VERSION "dbc-export 1 2026.26.6.5"

NS_ :

BS_:

BU_: ADSP APB APP APS APSB BB BMS CC CMP CMPD CP DAS DI DIF DIR DPB EPAS3P EPAS3S EPASTP EPASTS EPBL EPBR ESP EVSE FC GTW HCML HCMR HVP IBST ICR IDB LS OCS1P PARK PCS PCS2 PM PMF PMR PNCD PTC RADC RCM RCM2 RCM3 RCU SCCM SCM SCS SDCR TAS TCU TCU2 TPMS TRCM UI UIS UMC USM V2G VC VCBATT VCBATT0 VCBATT1 VCBATT2 VCCC VCFRONT VCFRONT1 VCFRONT2 VCLEFT VCRIGHT VCSEAT2L VCSEAT2R VCSEC VEH

BO_ 1025 BMS_brickMeasurements: 8 BMS
 SG_ BMS_brickVoltageMultiplexer M : 0|8@1+ (1,0) [0|255] "" Vector__XXX
 SG_ BMS_brickVoltageCounter : 14|2@1+ (1,0) [0|3] "" Vector__XXX
 SG_ BMS_brickVoltageStatus1 m0 : 8|2@1+ (1,0) [0|3] "" Vector__XXX
 SG_ BMS_brickVoltageStatus2 m0 : 10|2@1+ (1,0) [0|3] "" Vector__XXX
 SG_ BMS_brickVoltageStatus3 m0 : 12|2@1+ (1,0) [0|3] "" Vector__XXX
 SG_ BMS_brickVoltage1 m0 : 16|16@1+ (0.0001,0) [0|5] "V" Vector__XXX
 SG_ BMS_brickVoltage2 m0 : 32|16@1+ (0.0001,0) [0|5] "V" Vector__XXX
 SG_ BMS_brickVoltage3 m0 : 48|16@1+ (0.0001,0) [0|5] "V" Vector__XXX
 SG_ BMS_brickVoltageStatus4 m1 : 8|2@1+ (1,0) [0|3] "" Vector__XXX
 SG_ BMS_brickVoltageStatus5 m1 : 10|2@1+ (1,0) [0|3] "" Vector__XXX
 SG_ BMS_brickVoltageStatus6 m1 : 12|2@1+ (1,0) [0|3] "" Vector__XXX
 SG_ BMS_brickVoltage4 m1 : 16|16@1+ (0.0001,0) [0|5] "V" Vector__XXX
 SG_ BMS_brickVoltage5 m1 : 32|16@1+ (0.0001,0) [0|5] "V" Vector__XXX
 SG_ BMS_brickVoltage6 m1 : 48|16@1+ (0.0001,0) [0|5] "V" Vector__XXX
 SG_ BMS_brickVoltageStatus7 m2 : 8|2@1+ (1,0) [0|3] "" Vector__XXX
 SG_ BMS_brickVoltageStatus8 m2 : 10|2@1+ (1,0) [0|3] "" Vector__XXX
 SG_ BMS_brickVoltageStatus9 m2 : 12|2@1+ (1,0) [0|3] "" Vector__XXX
 SG_ BMS_brickVoltage7 m2 : 16|16@1+ (0.0001,0) [0|5] "V" Vector__XXX
 SG_ BMS_brickVoltage8 m2 : 32|16@1+ (0.0001,0) [0|5] "V" Vector__XXX
 SG_ BMS_brickVoltage9 m2 : 48|16@1+ (0.0001,0) [0|5] "V" Vector__XXX
 SG_ BMS_brickVoltageStatus10 m3 : 8|2@1+ (1,0) [0|3] "" Vector__XXX
 SG_ BMS_brickVoltageStatus11 m3 : 10|2@1+ (1,0) [0|3] "" Vector__XXX
 SG_ BMS_brickVoltageStatus12 m3 : 12|2@1+ (1,0) [0|3] "" Vector__XXX
 SG_ BMS_brickVoltage10 m3 : 16|16@1+ (0.0001,0) [0|5] "V" Vector__XXX
 SG_ BMS_brickVoltage11 m3 : 32|16@1+ (0.0001,0) [0|5] "V" Vector__XXX
 SG_ BMS_brickVoltage12 m3 : 48|16@1+ (0.0001,0) [0|5] "V" Vector__XXX
 SG_ BMS_brickVoltageStatus13 m4 : 8|2@1+ (1,0) [0|3] "" Vector__XXX
 SG_ BMS_brickVoltageStatus14 m4 : 10|2@1+ (1,0) [0|3] "" Vector__XXX
 SG_ BMS_brickVoltageStatus15 m4 : 12|2@1+ (1,0) [0|3] "" Vector__XXX
 SG_ BMS_brickVoltage13 m4 : 16|16@1+ (0.0001,0) [0|5] "V" Vector__XXX
 SG_ BMS_brickVoltage14 m4 : 32|16@1+ (0.0001,0) [0|5] "V" Vector__XXX
 SG_ BMS_brickVoltage15 m4 : 48|16@1+ (0.0001,0) [0|5] "V" Vector__XXX
 SG_ BMS_brickVoltageStatus16 m5 : 8|2@1+ (1,0) [0|3] "" Vector__XXX
 SG_ BMS_brickVoltageStatus17 m5 : 10|2@1+ (1,0) [0|3] "" Vector__XXX
 SG_ BMS_brickVoltageStatus18 m5 : 12|2@1+ (1,0) [0|3] "" Vector__XXX
 SG_ BMS_brickVoltage16 m5 : 16|16@1+ (0.0001,0) [0|5] "V" Vector__XXX
 SG_ BMS_brickVoltage17 m5 : 32|16@1+ (0.0001,0) [0|5] "V" Vector__XXX
 SG_ BMS_brickVoltage18 m5 : 48|16@1+ (0.0001,0) [0|5] "V" Vector__XXX
 SG_ BMS_brickVoltageStatus19 m6 : 8|2@1+ (1,0) [0|3] "" Vector__XXX
 SG_ BMS_brickVoltageStatus20 m6 : 10|2@1+ (1,0) [0|3] "" Vector__XXX
 SG_ BMS_brickVoltageStatus21 m6 : 12|2@1+ (1,0) [0|3] "" Vector__XXX
 SG_ BMS_brickVoltage19 m6 : 16|16@1+ (0.0001,0) [0|5] "V" Vector__XXX
 SG_ BMS_brickVoltage20 m6 : 32|16@1+ (0.0001,0) [0|5] "V" Vector__XXX
 SG_ BMS_brickVoltage21 m6 : 48|16@1+ (0.0001,0) [0|5] "V" Vector__XXX
 SG_ BMS_brickVoltageStatus22 m7 : 8|2@1+ (1,0) [0|3] "" Vector__XXX
 SG_ BMS_brickVoltageStatus23 m7 : 10|2@1+ (1,0) [0|3] "" Vector__XXX
 SG_ BMS_brickVoltageStatus24 m7 : 12|2@1+ (1,0) [0|3] "" Vector__XXX
 SG_ BMS_brickVoltage22 m7 : 16|16@1+ (0.0001,0) [0|5] "V" Vector__XXX
 SG_ BMS_brickVoltage23 m7 : 32|16@1+ (0.0001,0) [0|5] "V" Vector__XXX
 SG_ BMS_brickVoltage24 m7 : 48|16@1+ (0.0001,0) [0|5] "V" Vector__XXX
 SG_ BMS_brickVoltageStatus25 m8 : 8|2@1+ (1,0) [0|3] "" Vector__XXX
 SG_ BMS_brickVoltageStatus26 m8 : 10|2@1+ (1,0) [0|3] "" Vector__XXX
 SG_ BMS_brickVoltageStatus27 m8 : 12|2@1+ (1,0) [0|3] "" Vector__XXX
 SG_ BMS_brickVoltage25 m8 : 16|16@1+ (0.0001,0) [0|5] "V" Vector__XXX
 SG_ BMS_brickVoltage26 m8 : 32|16@1+ (0.0001,0) [0|5] "V" Vector__XXX
 SG_ BMS_brickVoltage27 m8 : 48|16@1+ (0.0001,0) [0|5] "V" Vector__XXX
 SG_ BMS_brickVoltageStatus28 m9 : 8|2@1+ (1,0) [0|3] "" Vector__XXX
 SG_ BMS_brickVoltageStatus29 m9 : 10|2@1+ (1,0) [0|3] "" Vector__XXX
 SG_ BMS_brickVoltageStatus30 m9 : 12|2@1+ (1,0) [0|3] "" Vector__XXX
 SG_ BMS_brickVoltage28 m9 : 16|16@1+ (0.0001,0) [0|5] "V" Vector__XXX
 SG_ BMS_brickVoltage29 m9 : 32|16@1+ (0.0001,0) [0|5] "V" Vector__XXX
 SG_ BMS_brickVoltage30 m9 : 48|16@1+ (0.0001,0) [0|5] "V" Vector__XXX
 SG_ BMS_brickVoltageStatus31 m10 : 8|2@1+ (1,0) [0|3] "" Vector__XXX
 SG_ BMS_brickVoltageStatus32 m10 : 10|2@1+ (1,0) [0|3] "" Vector__XXX
 SG_ BMS_brickVoltageStatus33 m10 : 12|2@1+ (1,0) [0|3] "" Vector__XXX
 SG_ BMS_brickVoltage31 m10 : 16|16@1+ (0.0001,0) [0|5] "V" Vector__XXX
 SG_ BMS_brickVoltage32 m10 : 32|16@1+ (0.0001,0) [0|5] "V" Vector__XXX
 SG_ BMS_brickVoltage33 m10 : 48|16@1+ (0.0001,0) [0|5] "V" Vector__XXX
 SG_ BMS_brickVoltageStatus34 m11 : 8|2@1+ (1,0) [0|3] "" Vector__XXX
 SG_ BMS_brickVoltageStatus35 m11 : 10|2@1+ (1,0) [0|3] "" Vector__XXX
 SG_ BMS_brickVoltageStatus36 m11 : 12|2@1+ (1,0) [0|3] "" Vector__XXX
 SG_ BMS_brickVoltage34 m11 : 16|16@1+ (0.0001,0) [0|5] "V" Vector__XXX
 SG_ BMS_brickVoltage35 m11 : 32|16@1+ (0.0001,0) [0|5] "V" Vector__XXX
 SG_ BMS_brickVoltage36 m11 : 48|16@1+ (0.0001,0) [0|5] "V" Vector__XXX
 SG_ BMS_brickVoltageStatus37 m12 : 8|2@1+ (1,0) [0|3] "" Vector__XXX
 SG_ BMS_brickVoltageStatus38 m12 : 10|2@1+ (1,0) [0|3] "" Vector__XXX
 SG_ BMS_brickVoltageStatus39 m12 : 12|2@1+ (1,0) [0|3] "" Vector__XXX
 SG_ BMS_brickVoltage37 m12 : 16|16@1+ (0.0001,0) [0|5] "V" Vector__XXX
 SG_ BMS_brickVoltage38 m12 : 32|16@1+ (0.0001,0) [0|5] "V" Vector__XXX
 SG_ BMS_brickVoltage39 m12 : 48|16@1+ (0.0001,0) [0|5] "V" Vector__XXX
 SG_ BMS_brickVoltageStatus40 m13 : 8|2@1+ (1,0) [0|3] "" Vector__XXX
 SG_ BMS_brickVoltageStatus41 m13 : 10|2@1+ (1,0) [0|3] "" Vector__XXX
 SG_ BMS_brickVoltageStatus42 m13 : 12|2@1+ (1,0) [0|3] "" Vector__XXX
 SG_ BMS_brickVoltage40 m13 : 16|16@1+ (0.0001,0) [0|5] "V" Vector__XXX
 SG_ BMS_brickVoltage41 m13 : 32|16@1+ (0.0001,0) [0|5] "V" Vector__XXX
 SG_ BMS_brickVoltage42 m13 : 48|16@1+ (0.0001,0) [0|5] "V" Vector__XXX
 SG_ BMS_brickVoltageStatus43 m14 : 8|2@1+ (1,0) [0|3] "" Vector__XXX
 SG_ BMS_brickVoltageStatus44 m14 : 10|2@1+ (1,0) [0|3] "" Vector__XXX
 SG_ BMS_brickVoltageStatus45 m14 : 12|2@1+ (1,0) [0|3] "" Vector__XXX
 SG_ BMS_brickVoltage43 m14 : 16|16@1+ (0.0001,0) [0|5] "V" Vector__XXX
 SG_ BMS_brickVoltage44 m14 : 32|16@1+ (0.0001,0) [0|5] "V" Vector__XXX
 SG_ BMS_brickVoltage45 m14 : 48|16@1+ (0.0001,0) [0|5] "V" Vector__XXX
 SG_ BMS_brickVoltageStatus46 m15 : 8|2@1+ (1,0) [0|3] "" Vector__XXX
 SG_ BMS_brickVoltageStatus47 m15 : 10|2@1+ (1,0) [0|3] "" Vector__XXX
 SG_ BMS_brickVoltageStatus48 m15 : 12|2@1+ (1,0) [0|3] "" Vector__XXX
 SG_ BMS_brickVoltage46 m15 : 16|16@1+ (0.0001,0) [0|5] "V" Vector__XXX
 SG_ BMS_brickVoltage47 m15 : 32|16@1+ (0.0001,0) [0|5] "V" Vector__XXX
 SG_ BMS_brickVoltage48 m15 : 48|16@1+ (0.0001,0) [0|5] "V" Vector__XXX
 SG_ BMS_brickVoltageStatus49 m16 : 8|2@1+ (1,0) [0|3] "" Vector__XXX
 SG_ BMS_brickVoltageStatus50 m16 : 10|2@1+ (1,0) [0|3] "" Vector__XXX
 SG_ BMS_brickVoltageStatus51 m16 : 12|2@1+ (1,0) [0|3] "" Vector__XXX
 SG_ BMS_brickVoltage49 m16 : 16|16@1+ (0.0001,0) [0|5] "V" Vector__XXX
 SG_ BMS_brickVoltage50 m16 : 32|16@1+ (0.0001,0) [0|5] "V" Vector__XXX
 SG_ BMS_brickVoltage51 m16 : 48|16@1+ (0.0001,0) [0|5] "V" Vector__XXX
 SG_ BMS_brickVoltageStatus52 m17 : 8|2@1+ (1,0) [0|3] "" Vector__XXX
 SG_ BMS_brickVoltageStatus53 m17 : 10|2@1+ (1,0) [0|3] "" Vector__XXX
 SG_ BMS_brickVoltageStatus54 m17 : 12|2@1+ (1,0) [0|3] "" Vector__XXX
 SG_ BMS_brickVoltage52 m17 : 16|16@1+ (0.0001,0) [0|5] "V" Vector__XXX
 SG_ BMS_brickVoltage53 m17 : 32|16@1+ (0.0001,0) [0|5] "V" Vector__XXX
 SG_ BMS_brickVoltage54 m17 : 48|16@1+ (0.0001,0) [0|5] "V" Vector__XXX
 SG_ BMS_brickVoltageStatus55 m18 : 8|2@1+ (1,0) [0|3] "" Vector__XXX
 SG_ BMS_brickVoltageStatus56 m18 : 10|2@1+ (1,0) [0|3] "" Vector__XXX
 SG_ BMS_brickVoltageStatus57 m18 : 12|2@1+ (1,0) [0|3] "" Vector__XXX
 SG_ BMS_brickVoltage55 m18 : 16|16@1+ (0.0001,0) [0|5] "V" Vector__XXX
 SG_ BMS_brickVoltage56 m18 : 32|16@1+ (0.0001,0) [0|5] "V" Vector__XXX
 SG_ BMS_brickVoltage57 m18 : 48|16@1+ (0.0001,0) [0|5] "V" Vector__XXX
 SG_ BMS_brickVoltageStatus58 m19 : 8|2@1+ (1,0) [0|3] "" Vector__XXX
 SG_ BMS_brickVoltageStatus59 m19 : 10|2@1+ (1,0) [0|3] "" Vector__XXX
 SG_ BMS_brickVoltageStatus60 m19 : 12|2@1+ (1,0) [0|3] "" Vector__XXX
 SG_ BMS_brickVoltage58 m19 : 16|16@1+ (0.0001,0) [0|5] "V" Vector__XXX
 SG_ BMS_brickVoltage59 m19 : 32|16@1+ (0.0001,0) [0|5] "V" Vector__XXX
 SG_ BMS_brickVoltage60 m19 : 48|16@1+ (0.0001,0) [0|5] "V" Vector__XXX
 SG_ BMS_brickVoltageStatus61 m20 : 8|2@1+ (1,0) [0|3] "" Vector__XXX
 SG_ BMS_brickVoltageStatus62 m20 : 10|2@1+ (1,0) [0|3] "" Vector__XXX
 SG_ BMS_brickVoltageStatus63 m20 : 12|2@1+ (1,0) [0|3] "" Vector__XXX
 SG_ BMS_brickVoltage61 m20 : 16|16@1+ (0.0001,0) [0|5] "V" Vector__XXX
 SG_ BMS_brickVoltage62 m20 : 32|16@1+ (0.0001,0) [0|5] "V" Vector__XXX
 SG_ BMS_brickVoltage63 m20 : 48|16@1+ (0.0001,0) [0|5] "V" Vector__XXX
 SG_ BMS_brickVoltageStatus64 m21 : 8|2@1+ (1,0) [0|3] "" Vector__XXX
 SG_ BMS_brickVoltageStatus65 m21 : 10|2@1+ (1,0) [0|3] "" Vector__XXX
 SG_ BMS_brickVoltageStatus66 m21 : 12|2@1+ (1,0) [0|3] "" Vector__XXX
 SG_ BMS_brickVoltage64 m21 : 16|16@1+ (0.0001,0) [0|5] "V" Vector__XXX
 SG_ BMS_brickVoltage65 m21 : 32|16@1+ (0.0001,0) [0|5] "V" Vector__XXX
 SG_ BMS_brickVoltage66 m21 : 48|16@1+ (0.0001,0) [0|5] "V" Vector__XXX
 SG_ BMS_brickVoltageStatus67 m22 : 8|2@1+ (1,0) [0|3] "" Vector__XXX
 SG_ BMS_brickVoltageStatus68 m22 : 10|2@1+ (1,0) [0|3] "" Vector__XXX
 SG_ BMS_brickVoltageStatus69 m22 : 12|2@1+ (1,0) [0|3] "" Vector__XXX
 SG_ BMS_brickVoltage67 m22 : 16|16@1+ (0.0001,0) [0|5] "V" Vector__XXX
 SG_ BMS_brickVoltage68 m22 : 32|16@1+ (0.0001,0) [0|5] "V" Vector__XXX
 SG_ BMS_brickVoltage69 m22 : 48|16@1+ (0.0001,0) [0|5] "V" Vector__XXX
 SG_ BMS_brickVoltageStatus70 m23 : 8|2@1+ (1,0) [0|3] "" Vector__XXX
 SG_ BMS_brickVoltageStatus71 m23 : 10|2@1+ (1,0) [0|3] "" Vector__XXX
 SG_ BMS_brickVoltageStatus72 m23 : 12|2@1+ (1,0) [0|3] "" Vector__XXX
 SG_ BMS_brickVoltage70 m23 : 16|16@1+ (0.0001,0) [0|5] "V" Vector__XXX
 SG_ BMS_brickVoltage71 m23 : 32|16@1+ (0.0001,0) [0|5] "V" Vector__XXX
 SG_ BMS_brickVoltage72 m23 : 48|16@1+ (0.0001,0) [0|5] "V" Vector__XXX
 SG_ BMS_brickVoltageStatus73 m24 : 8|2@1+ (1,0) [0|3] "" Vector__XXX
 SG_ BMS_brickVoltageStatus74 m24 : 10|2@1+ (1,0) [0|3] "" Vector__XXX
 SG_ BMS_brickVoltageStatus75 m24 : 12|2@1+ (1,0) [0|3] "" Vector__XXX
 SG_ BMS_brickVoltage73 m24 : 16|16@1+ (0.0001,0) [0|5] "V" Vector__XXX
 SG_ BMS_brickVoltage74 m24 : 32|16@1+ (0.0001,0) [0|5] "V" Vector__XXX
 SG_ BMS_brickVoltage75 m24 : 48|16@1+ (0.0001,0) [0|5] "V" Vector__XXX
 SG_ BMS_brickVoltageStatus76 m25 : 8|2@1+ (1,0) [0|3] "" Vector__XXX
 SG_ BMS_brickVoltageStatus77 m25 : 10|2@1+ (1,0) [0|3] "" Vector__XXX
 SG_ BMS_brickVoltageStatus78 m25 : 12|2@1+ (1,0) [0|3] "" Vector__XXX
 SG_ BMS_brickVoltage76 m25 : 16|16@1+ (0.0001,0) [0|5] "V" Vector__XXX
 SG_ BMS_brickVoltage77 m25 : 32|16@1+ (0.0001,0) [0|5] "V" Vector__XXX
 SG_ BMS_brickVoltage78 m25 : 48|16@1+ (0.0001,0) [0|5] "V" Vector__XXX
 SG_ BMS_brickVoltageStatus79 m26 : 8|2@1+ (1,0) [0|3] "" Vector__XXX
 SG_ BMS_brickVoltageStatus80 m26 : 10|2@1+ (1,0) [0|3] "" Vector__XXX
 SG_ BMS_brickVoltageStatus81 m26 : 12|2@1+ (1,0) [0|3] "" Vector__XXX
 SG_ BMS_brickVoltage79 m26 : 16|16@1+ (0.0001,0) [0|5] "V" Vector__XXX
 SG_ BMS_brickVoltage80 m26 : 32|16@1+ (0.0001,0) [0|5] "V" Vector__XXX
 SG_ BMS_brickVoltage81 m26 : 48|16@1+ (0.0001,0) [0|5] "V" Vector__XXX
 SG_ BMS_brickVoltageStatus82 m27 : 8|2@1+ (1,0) [0|3] "" Vector__XXX
 SG_ BMS_brickVoltageStatus83 m27 : 10|2@1+ (1,0) [0|3] "" Vector__XXX
 SG_ BMS_brickVoltageStatus84 m27 : 12|2@1+ (1,0) [0|3] "" Vector__XXX
 SG_ BMS_brickVoltage82 m27 : 16|16@1+ (0.0001,0) [0|5] "V" Vector__XXX
 SG_ BMS_brickVoltage83 m27 : 32|16@1+ (0.0001,0) [0|5] "V" Vector__XXX
 SG_ BMS_brickVoltage84 m27 : 48|16@1+ (0.0001,0) [0|5] "V" Vector__XXX
 SG_ BMS_brickVoltageStatus85 m28 : 8|2@1+ (1,0) [0|3] "" Vector__XXX
 SG_ BMS_brickVoltageStatus86 m28 : 10|2@1+ (1,0) [0|3] "" Vector__XXX
 SG_ BMS_brickVoltageStatus87 m28 : 12|2@1+ (1,0) [0|3] "" Vector__XXX
 SG_ BMS_brickVoltage85 m28 : 16|16@1+ (0.0001,0) [0|5] "V" Vector__XXX
 SG_ BMS_brickVoltage86 m28 : 32|16@1+ (0.0001,0) [0|5] "V" Vector__XXX
 SG_ BMS_brickVoltage87 m28 : 48|16@1+ (0.0001,0) [0|5] "V" Vector__XXX
 SG_ BMS_brickVoltageStatus88 m29 : 8|2@1+ (1,0) [0|3] "" Vector__XXX
 SG_ BMS_brickVoltageStatus89 m29 : 10|2@1+ (1,0) [0|3] "" Vector__XXX
 SG_ BMS_brickVoltageStatus90 m29 : 12|2@1+ (1,0) [0|3] "" Vector__XXX
 SG_ BMS_brickVoltage88 m29 : 16|16@1+ (0.0001,0) [0|5] "V" Vector__XXX
 SG_ BMS_brickVoltage89 m29 : 32|16@1+ (0.0001,0) [0|5] "V" Vector__XXX
 SG_ BMS_brickVoltage90 m29 : 48|16@1+ (0.0001,0) [0|5] "V" Vector__XXX
 SG_ BMS_brickVoltageStatus91 m30 : 8|2@1+ (1,0) [0|3] "" Vector__XXX
 SG_ BMS_brickVoltageStatus92 m30 : 10|2@1+ (1,0) [0|3] "" Vector__XXX
 SG_ BMS_brickVoltageStatus93 m30 : 12|2@1+ (1,0) [0|3] "" Vector__XXX
 SG_ BMS_brickVoltage91 m30 : 16|16@1+ (0.0001,0) [0|5] "V" Vector__XXX
 SG_ BMS_brickVoltage92 m30 : 32|16@1+ (0.0001,0) [0|5] "V" Vector__XXX
 SG_ BMS_brickVoltage93 m30 : 48|16@1+ (0.0001,0) [0|5] "V" Vector__XXX
 SG_ BMS_brickVoltageStatus94 m31 : 8|2@1+ (1,0) [0|3] "" Vector__XXX
 SG_ BMS_brickVoltageStatus95 m31 : 10|2@1+ (1,0) [0|3] "" Vector__XXX
 SG_ BMS_brickVoltageStatus96 m31 : 12|2@1+ (1,0) [0|3] "" Vector__XXX
 SG_ BMS_brickVoltage94 m31 : 16|16@1+ (0.0001,0) [0|5] "V" Vector__XXX
 SG_ BMS_brickVoltage95 m31 : 32|16@1+ (0.0001,0) [0|5] "V" Vector__XXX
 SG_ BMS_brickVoltage96 m31 : 48|16@1+ (0.0001,0) [0|5] "V" Vector__XXX
 SG_ BMS_brickVoltageStatus97 m32 : 8|2@1+ (1,0) [0|3] "" Vector__XXX
 SG_ BMS_brickVoltageStatus98 m32 : 10|2@1+ (1,0) [0|3] "" Vector__XXX
 SG_ BMS_brickVoltageStatus99 m32 : 12|2@1+ (1,0) [0|3] "" Vector__XXX
 SG_ BMS_brickVoltage97 m32 : 16|16@1+ (0.0001,0) [0|5] "V" Vector__XXX
 SG_ BMS_brickVoltage98 m32 : 32|16@1+ (0.0001,0) [0|5] "V" Vector__XXX
 SG_ BMS_brickVoltage99 m32 : 48|16@1+ (0.0001,0) [0|5] "V" Vector__XXX
 SG_ BMS_brickVoltageStatus100 m33 : 8|2@1+ (1,0) [0|3] "" Vector__XXX
 SG_ BMS_brickVoltageStatus101 m33 : 10|2@1+ (1,0) [0|3] "" Vector__XXX
 SG_ BMS_brickVoltageStatus102 m33 : 12|2@1+ (1,0) [0|3] "" Vector__XXX
 SG_ BMS_brickVoltage100 m33 : 16|16@1+ (0.0001,0) [0|5] "V" Vector__XXX
 SG_ BMS_brickVoltage101 m33 : 32|16@1+ (0.0001,0) [0|5] "V" Vector__XXX
 SG_ BMS_brickVoltage102 m33 : 48|16@1+ (0.0001,0) [0|5] "V" Vector__XXX
 SG_ BMS_brickVoltageStatus103 m34 : 8|2@1+ (1,0) [0|3] "" Vector__XXX
 SG_ BMS_brickVoltageStatus104 m34 : 10|2@1+ (1,0) [0|3] "" Vector__XXX
 SG_ BMS_brickVoltageStatus105 m34 : 12|2@1+ (1,0) [0|3] "" Vector__XXX
 SG_ BMS_brickVoltage103 m34 : 16|16@1+ (0.0001,0) [0|5] "V" Vector__XXX
 SG_ BMS_brickVoltage104 m34 : 32|16@1+ (0.0001,0) [0|5] "V" Vector__XXX
 SG_ BMS_brickVoltage105 m34 : 48|16@1+ (0.0001,0) [0|5] "V" Vector__XXX
 SG_ BMS_brickVoltageStatus106 m35 : 8|2@1+ (1,0) [0|3] "" Vector__XXX
 SG_ BMS_brickVoltageStatus107 m35 : 10|2@1+ (1,0) [0|3] "" Vector__XXX
 SG_ BMS_brickVoltageStatus108 m35 : 12|2@1+ (1,0) [0|3] "" Vector__XXX
 SG_ BMS_brickVoltage106 m35 : 16|16@1+ (0.0001,0) [0|5] "V" Vector__XXX
 SG_ BMS_brickVoltage107 m35 : 32|16@1+ (0.0001,0) [0|5] "V" Vector__XXX
 SG_ BMS_brickVoltage108 m35 : 48|16@1+ (0.0001,0) [0|5] "V" Vector__XXX

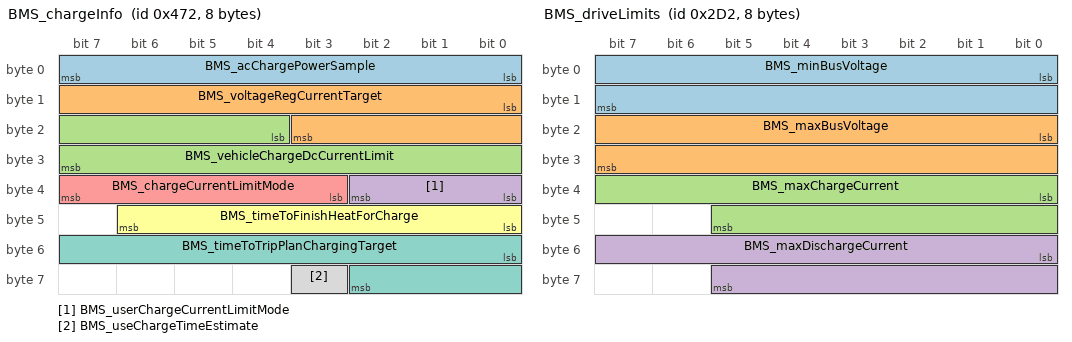
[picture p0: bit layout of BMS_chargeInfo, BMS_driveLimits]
BO_ 1138 BMS_chargeInfo: 8 BMS
 SG_ BMS_acChargePowerSample : 0|8@1+ (0.1,0) [0|25] "kW" Vector__XXX
 SG_ BMS_voltageRegCurrentTarget : 8|12@1+ (0.5,0) [0|2047.5] "A" Vector__XXX
 SG_ BMS_vehicleChargeDcCurrentLimit : 20|12@1+ (0.5,0) [0|2047.5] "A" Vector__XXX
 SG_ BMS_userChargeCurrentLimitMode : 32|3@1+ (1,0) [0|7] "" Vector__XXX
 SG_ BMS_chargeCurrentLimitMode : 35|5@1+ (1,0) [0|31] "" Vector__XXX
 SG_ BMS_timeToFinishHeatForCharge : 40|7@1+ (5,0) [0|600] "min" Vector__XXX
 SG_ BMS_timeToTripPlanChargingTarget : 48|11@1+ (1,0) [0|2046] "min" Vector__XXX
 SG_ BMS_useChargeTimeEstimate : 59|1@1+ (1,0) [0|1] "" Vector__XXX

BO_ 722 BMS_driveLimits: 8 BMS
 SG_ BMS_minBusVoltage : 0|16@1+ (0.02,0) [0|1200] "V" Vector__XXX
 SG_ BMS_maxBusVoltage : 16|16@1+ (0.02,0) [0|1200] "V" Vector__XXX
 SG_ BMS_maxChargeCurrent : 32|14@1+ (0.1,0) [0|1638.2] "A" Vector__XXX
 SG_ BMS_maxDischargeCurrent : 48|14@1+ (0.15,0) [0|2455] "A" Vector__XXX

BO_ 690 BMS_energyStatus: 8 BMS
 SG_ BMS_energyStatusMultiplexer M : 0|2@1+ (1,0) [0|3] "" Vector__XXX
 SG_ BMS_nominalFullPackEnergy m0 : 16|16@1+ (0.02,0) [0|1310.68] "kWh" Vector__XXX
 SG_ BMS_nominalEnergyRemaining m0 : 32|16@1+ (0.02,0) [0|1310.68] "kWh" Vector__XXX
 SG_ BMS_idealEnergyRemaining m0 : 48|16@1+ (0.02,0) [0|1310.68] "kWh" Vector__XXX
 SG_ BMS_fullChargeComplete m1 : 15|1@1+ (1,0) [0|1] "" Vector__XXX
 SG_ BMS_energyBuffer m1 : 16|16@1+ (0.01,0) [0|655.34] "kWh" Vector__XXX
 SG_ BMS_expectedEnergyRemaining m1 : 32|16@1+ (0.02,0) [0|1310.68] "kWh" Vector__XXX
 SG_ BMS_energyToChargeComplete m1 : 48|16@1+ (0.02,0) [0|1310.68] "kWh" Vector__XXX
 SG_ BMS_energyRemainingDisplay m2 : 8|16@1+ (0.02,0) [0|1310.68] "kWh" Vector__XXX
 SG_ BMS_energyRemainingTDisplay m2 : 24|16@1+ (0.02,0) [0|1310.68] "kWh" Vector__XXX
 SG_ BMS_energyDisplayErrorBlendRate m2 : 40|12@1+ (0.0156288165599,0) [0|64] "%" Vector__XXX
 SG_ BMS_userFacingSoe m2 : 52|11@1+ (0.05,0) [0|100] "%" Vector__XXX

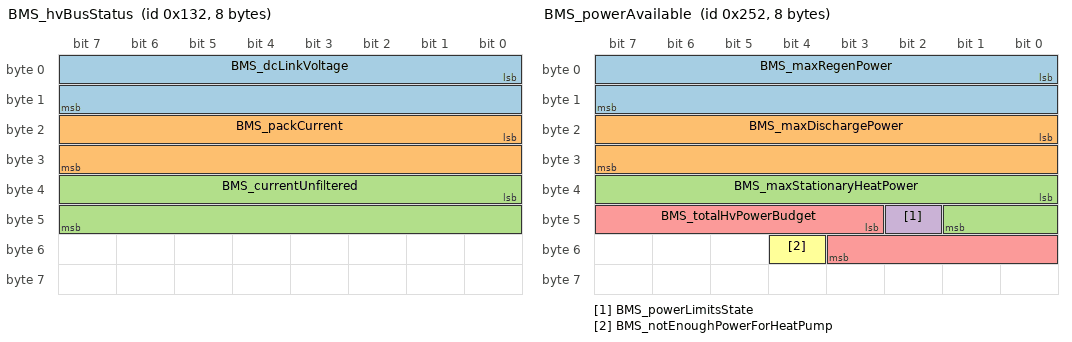
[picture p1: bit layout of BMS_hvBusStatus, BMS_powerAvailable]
BO_ 306 BMS_hvBusStatus: 8 BMS
 SG_ BMS_dcLinkVoltage : 0|16@1+ (0.01,0) [0|655.35] "V" Vector__XXX
 SG_ BMS_packCurrent : 16|16@1- (0.1,0) [-3276.7|3276.7] "A" Vector__XXX
 SG_ BMS_currentUnfiltered : 32|16@1- (0.05,-822) [-2460.3|816.3] "A" Vector__XXX

BO_ 768 BMS_info: 8 BMS
 SG_ BMS_infoIndex M : 0|8@1+ (1,0) [0|255] "" Vector__XXX
 SG_ BMS_buildType m10 : 8|3@1+ (1,0) [0|7] "" Vector__XXX
 SG_ BMS_buildConfigId m10 : 16|16@1+ (1,0) [0|65535] "" Vector__XXX
 SG_ BMS_hardwareId m10 : 32|16@1+ (1,0) [0|65535] "" Vector__XXX
 SG_ BMS_componentId m10 : 48|16@1+ (1,0) [0|65535] "" Vector__XXX
 SG_ BMS_pcbaId m11 : 16|8@1+ (1,0) [0|255] "" Vector__XXX
 SG_ BMS_assemblyId m11 : 24|8@1+ (1,0) [0|255] "" Vector__XXX
 SG_ BMS_usageId m11 : 32|16@1+ (1,0) [0|65535] "" Vector__XXX
 SG_ BMS_subUsageId m11 : 48|16@1+ (1,0) [0|65535] "" Vector__XXX
 SG_ BMS_platformType m13 : 8|8@1+ (1,0) [0|255] "" Vector__XXX
 SG_ BMS_appCrc m13 : 32|32@1+ (1,0) [0|4294967295] "" Vector__XXX
 SG_ BMS_appGitHash m17 : 8|56@1+ (1,0) [0|7.20575940379e+16] "" Vector__XXX
 SG_ BMS_bootGitHash m18 : 8|56@1+ (1,0) [0|7.20575940379e+16] "" Vector__XXX
 SG_ BMS_bootUdsProtoVersion m20 : 8|8@1+ (1,0) [0|255] "" Vector__XXX
 SG_ BMS_bootCrc m20 : 32|32@1+ (1,0) [0|4294967295] "" Vector__XXX

BO_ 978 BMS_kwhCounter: 8 BMS
 SG_ BMS_kwhDischargeTotal : 0|32@1+ (0.001,0) [0|268435.456] "KWh" Vector__XXX
 SG_ BMS_kwhChargeTotal : 32|32@1+ (0.001,0) [0|268435.456] "KWh" Vector__XXX

BO_ 1010 BMS_kwhCountersMultiplexed: 8 BMS
 SG_ BMS_kwhCounter_Id M : 0|4@1+ (1,0) [0|15] "" Vector__XXX
 SG_ BMS_acChargerKwhTotal m0 : 8|32@1+ (0.001,0) [0|268435.456] "KWh" Vector__XXX
 SG_ BMS_dcChargerKwhTotal m1 : 8|32@1+ (0.001,0) [0|268435.456] "KWh" Vector__XXX
 SG_ BMS_kwhRegenChargeTotal m2 : 8|32@1+ (0.001,0) [0|268435.456] "KWh" Vector__XXX
 SG_ BMS_kwhDriveDischargeTotal m3 : 8|32@1+ (0.001,0) [0|268435.456] "KWh" Vector__XXX
 SG_ BMS_kwhDischargeTotalModule1 m4 : 8|28@1+ (0.001,0) [0|268435.455] "KWh" Vector__XXX
 SG_ BMS_kwhChargeTotalModule1 m4 : 36|28@1+ (0.001,0) [0|268435.455] "KWh" Vector__XXX
 SG_ BMS_kwhAcChargeTotalModule1 m5 : 8|28@1+ (0.001,0) [0|268435.455] "KWh" Vector__XXX
 SG_ BMS_kwhDcChargeTotalModule1 m5 : 36|28@1+ (0.001,0) [0|268435.455] "KWh" Vector__XXX
 SG_ BMS_kwhDischargeTotalModule2 m6 : 8|28@1+ (0.001,0) [0|268435.455] "KWh" Vector__XXX
 SG_ BMS_kwhChargeTotalModule2 m6 : 36|28@1+ (0.001,0) [0|268435.455] "KWh" Vector__XXX
 SG_ BMS_kwhAcChargeTotalModule2 m7 : 8|28@1+ (0.001,0) [0|268435.455] "KWh" Vector__XXX
 SG_ BMS_kwhDcChargeTotalModule2 m7 : 36|28@1+ (0.001,0) [0|268435.455] "KWh" Vector__XXX
 SG_ BMS_kwhDischargeTotalModule3 m8 : 8|28@1+ (0.001,0) [0|268435.455] "KWh" Vector__XXX
 SG_ BMS_kwhChargeTotalModule3 m8 : 36|28@1+ (0.001,0) [0|268435.455] "KWh" Vector__XXX
 SG_ BMS_kwhAcChargeTotalModule3 m9 : 8|28@1+ (0.001,0) [0|268435.455] "KWh" Vector__XXX
 SG_ BMS_kwhDcChargeTotalModule3 m9 : 36|28@1+ (0.001,0) [0|268435.455] "KWh" Vector__XXX
 SG_ BMS_kwhDischargeTotalModule4 m10 : 8|28@1+ (0.001,0) [0|268435.455] "KWh" Vector__XXX
 SG_ BMS_kwhChargeTotalModule4 m10 : 36|28@1+ (0.001,0) [0|268435.455] "KWh" Vector__XXX
 SG_ BMS_kwhAcChargeTotalModule4 m11 : 8|28@1+ (0.001,0) [0|268435.455] "KWh" Vector__XXX
 SG_ BMS_kwhDcChargeTotalModule4 m11 : 36|28@1+ (0.001,0) [0|268435.455] "KWh" Vector__XXX

BO_ 884 BMS_log1: 8 BMS
 SG_ BMS_log1MuxId M : 0|8@1+ (1,0) [0|255] "" Vector__XXX
 SG_ BMS_powerTransferStatus m4 : 16|4@1+ (1,0) [0|15] "" Vector__XXX
 SG_ BMS_extDcPrechargeVoltageLimit m4 : 20|12@1+ (0.146502256393,0) [0|599.926739929] "V" Vector__XXX
 SG_ BMS_dcChargeCurrentRequest m4 : 32|14@1- (0.25,0) [-2048|2047.75] "A" Vector__XXX
 SG_ BMS_dcChargeCurrentLimit m4 : 46|13@1- (0.5,0) [-2048|2047.5] "A" Vector__XXX
 SG_ BMS_dcDischargeEnabled m4 : 59|1@1+ (1,0) [0|1] "" Vector__XXX
 SG_ BMS_rippleChargeRetryCount m4 : 60|3@1+ (1,0) [0|7] "" Vector__XXX
 SG_ BMS_dcChargeVoltageLimit m5 : 8|12@1+ (0.146502256393,0) [0|599.926739929] "V" Vector__XXX
 SG_ BMS_dcChargePowerLimit m5 : 20|12@1- (1,0) [-2048|2047] "kW" Vector__XXX
 SG_ BMS_acRealPowerRequest m5 : 32|16@1- (0.002,0) [-40|40] "kW" Vector__XXX
 SG_ BMS_maxExtIsoFcLinkV m5 : 48|13@1+ (0.134293735027,0) [0|1099.99998361] "V" Vector__XXX
 SG_ BMS_energyMaxPredictedBrickTemp m13 : 8|8@1+ (1,-50) [-50|205] "C" Vector__XXX
 SG_ BMS_energyTempGradientAtMaxTemp m13 : 16|9@1+ (0.1,0) [0|51.1] "C" Vector__XXX
 SG_ BMS_energyWalkMaxSoc m13 : 25|10@1+ (0.1,0) [0|102.3] "%" Vector__XXX
 SG_ BMS_energyWalkMinSoc m13 : 35|10@1+ (0.1,0) [0|102.3] "%" Vector__XXX
 SG_ BMS_chargeEnergyWalkState m13 : 45|2@1+ (1,0) [0|3] "" Vector__XXX
 SG_ BMS_packVoltage m13 : 48|16@1+ (0.01,0) [0|655.35] "V" Vector__XXX
 SG_ BMS_energyWalkMaxPackCurrent m14 : 8|16@1- (0.1,0) [-3276.7|3276.7] "A" Vector__XXX
 SG_ BMS_energyWalkMaxVehiclePower m14 : 24|11@1- (1,500) [-524|1523] "kW" Vector__XXX
 SG_ BMS_battTempPct m14 : 35|8@1+ (0.4,0) [0|100] "%" Vector__XXX
 SG_ BMS_powerTransferDisableType m14 : 43|2@1+ (1,0) [0|3] "" Vector__XXX
 SG_ BMS_powerTransferDisableReason m14 : 45|6@1+ (1,0) [0|63] "" Vector__XXX
 SG_ BMS_powerTransferWaitCondition m14 : 51|6@1+ (1,0) [0|63] "" Vector__XXX
 SG_ BMS_dischargeRetryCount m14 : 57|3@1+ (1,0) [0|7] "" Vector__XXX
 SG_ BMS_acChargeDesired m14 : 60|1@1+ (1,0) [0|1] "" Vector__XXX
 SG_ BMS_tetheringDesired m14 : 61|1@1+ (1,0) [0|1] "" Vector__XXX
 SG_ BMS_gridFormDesired m14 : 62|1@1+ (1,0) [0|1] "" Vector__XXX
 SG_ BMS_gridFollowDesired m14 : 63|1@1+ (1,0) [0|1] "" Vector__XXX

BO_ 946 BMS_log2: 8 BMS
 SG_ BMS_log2MuxId M : 0|7@1+ (1,0) [0|127] "" Vector__XXX
 SG_ BMS_maxChargeRestartNeededByVolt m0 : 7|1@1+ (1,0) [0|1] "" Vector__XXX
 SG_ BMS_cacAvg m0 : 8|13@1+ (0.1,0) [0|819.1] "Ah" Vector__XXX
 SG_ BMS_maxChargeNearComplete m0 : 21|1@1+ (1,0) [0|1] "" Vector__XXX
 SG_ BMS_cacMin m0 : 24|13@1+ (0.1,0) [0|819.1] "Ah" Vector__XXX
 SG_ BMS_cacMinBrickId m0 : 37|7@1+ (1,1) [1|128] "" Vector__XXX
 SG_ BMS_cacMax m0 : 44|13@1+ (0.1,0) [0|819.1] "Ah" Vector__XXX
 SG_ BMS_cacMaxBrickId m0 : 57|7@1+ (1,1) [1|128] "" Vector__XXX
 SG_ BMS_acRippleConfigNvramValid m18 : 7|1@1+ (1,0) [0|1] "" Vector__XXX
 SG_ BMS_hvChain_useLeakyBucket m18 : 8|1@1+ (1,0) [0|1] "" Vector__XXX
 SG_ BMS_hvChain_iLimit m18 : 9|14@1+ (0.2,0) [0|3275] "A" Vector__XXX
 SG_ BMS_hvChain_limitingState m18 : 23|9@1+ (1,1) [1|512] "" Vector__XXX
 SG_ BMS_hvChain_limitingStateTempera m18 : 32|13@1- (0.1,367.6) [-40|775] "DegC" Vector__XXX
 SG_ BMS_acRippleIsSupported m18 : 45|1@1+ (1,0) [0|1] "" Vector__XXX
 SG_ BMS_acRippleStartTemperatureMax m18 : 46|9@1+ (0.25,-25) [-25|100] "DegC" Vector__XXX
 SG_ BMS_acRippleStartTemperatureMin m18 : 55|9@1+ (0.25,-25) [-25|100] "DegC" Vector__XXX
 SG_ BMS_fcLinkTestDecayTime m20 : 8|10@1+ (2,0) [0|2044] "mS" Vector__XXX
 SG_ BMS_fcLinkTestTimeSinceLastRun m20 : 18|12@1+ (0.0175824183971,0) [0|71.99] "Hours" Vector__XXX
 SG_ BMS_pcsPrechargeRequest m20 : 30|2@1+ (1,0) [0|3] "" Vector__XXX
 SG_ BMS_pcsPrechargeTargetVoltage m20 : 32|16@1- (0.1,0) [-3276.8|3276.7] "V" Vector__XXX
 SG_ BMS_recentOvUvAlert m20 : 48|1@1+ (1,0) [0|1] "" Vector__XXX
 SG_ BMS_recentIsoAlert m20 : 49|1@1+ (1,0) [0|1] "" Vector__XXX
 SG_ BMS_recentBmbMiaAlert m20 : 50|1@1+ (1,0) [0|1] "" Vector__XXX
 SG_ BMS_cacBlendingConfigNvramValid m20 : 51|1@1+ (1,0) [0|1] "" Vector__XXX
 SG_ BMS_cacBlendingEnabled m20 : 52|1@1+ (1,0) [0|1] "" Vector__XXX
 SG_ BMS_cacBlendPercentPerCycle m20 : 53|10@1+ (0.001,0) [0|1.023] "%" Vector__XXX
 SG_ BMS_energyVariableChgRequested m21 : 8|1@1+ (1,0) [0|1] "" Vector__XXX
 SG_ BMS_packRestTime m21 : 9|12@1+ (0.0175824183971,0) [0|71.99] "Hours" Vector__XXX
 SG_ BMS_idealEnergyFloor m21 : 21|10@1+ (0.1,0) [0|102.2] "KWh" Vector__XXX
 SG_ BMS_thmGradientSlopeCondition m21 : 31|1@1+ (1,0) [0|1] "" Vector__XXX
 SG_ BMS_recentSlopeConditon m21 : 32|1@1+ (1,0) [0|1] "" Vector__XXX
 SG_ BMS_dynamicEnergyBuffer m21 : 33|10@1+ (0.1,0) [0|102.2] "KWh" Vector__XXX
 SG_ BMS_temperatureCondition m21 : 43|1@1+ (1,0) [0|1] "" Vector__XXX
 SG_ BMS_thmGradientSlope m21 : 44|10@1- (0.01,0) [-5.12|5.11] "C/min" Vector__XXX
 SG_ BMS_thmGradient m21 : 56|8@1+ (0.1,0) [0|25.5] "C" Vector__XXX
 SG_ BMS_tempVsSocTotalChgEnergy m31 : 7|25@1+ (0.000149011611938,0) [0|4999.99985097] "wh/wh" Vector__XXX
 SG_ BMS_powerVsVoltageTotalChgEnergy m31 : 32|25@1+ (0.000149011611938,0) [0|4999.99985097] "wh/wh" Vector__XXX
 SG_ BMS_lifeModelOutputsAreTrustwort m31 : 57|1@1+ (1,0) [0|1] "" Vector__XXX
 SG_ BMS_dSocNormalizedMin m33 : 8|12@1+ (0.0030517578125,-12.4969482422) [-12.4969482422|-0.0030517578125] "%" Vector__XXX
 SG_ BMS_dSocNormalizedFiltMin m33 : 20|12@1+ (0.0030517578125,-12.4969482422) [-12.4969482422|-0.0030517578125] "%" Vector__XXX
 SG_ BMS_dSocMinAlpha m33 : 32|12@1+ (0.0030517578125,-12.4969482422) [-12.4969482422|-0.0030517578125] "%" Vector__XXX
 SG_ BMS_dSocMaxLowAlphaCounter m33 : 44|4@1+ (1,0) [0|15] "" Vector__XXX
 SG_ BMS_dSocMinAlphaBrickID m33 : 48|7@1+ (1,1) [1|128] "" Vector__XXX
 SG_ BMS_dSocCacMargin m33 : 55|9@1+ (0.0030517578125,0) [0|1.55639648438] "%" Vector__XXX
 SG_ BMS_lifeModelNoCurrentStorageCap m54 : 7|9@1+ (0.1,0) [0|51] "%" Vector__XXX
 SG_ BMS_lifeModelShortDcr m54 : 16|8@1+ (0.01,0) [0|2.54] "mOhm" Vector__XXX
 SG_ BMS_lifeModelLongDcr m54 : 24|13@1- (0.1,309.6) [-100|719] "mOhm" Vector__XXX
 SG_ BMS_lifeModelStorageCapacityLoss m54 : 37|9@1+ (0.1,0) [0|51] "%" Vector__XXX
 SG_ BMS_lifeModelThroughputCapacityL m54 : 46|9@1+ (0.1,0) [0|51] "%" Vector__XXX
 SG_ BMS_passiveCoolCellTargetT m54 : 55|9@1+ (0.25,-25) [-25|100] "DegC" Vector__XXX
 SG_ BMS_lifeModelAvgTempSeverity m55 : 8|5@1+ (0.1,0) [0|3] "-" Vector__XXX
 SG_ BMS_lifeModelDepthOfDischargeSev m55 : 16|8@1+ (0.01,0) [0|1.5] "-" Vector__XXX
 SG_ BMS_lifeModelHistogramCapacityLo m55 : 24|9@1+ (0.1,0) [0|51] "%" Vector__XXX
 SG_ BMS_lifeModelHistogramBrickCapac m55 : 33|13@1+ (0.1,0) [0|819] "Ah" Vector__XXX
 SG_ BMS_lifeModelDcrGrowthPercent m55 : 48|14@1- (0.1,200) [-100|500] "%" Vector__XXX
 SG_ BMS_nominalFullPackEnergyRaw m56 : 8|16@1+ (0.02,0) [0|1310.68] "kWh" Vector__XXX
 SG_ BMS_nominalEnergyRemainingBuffer m56 : 24|16@1+ (0.02,0) [0|1310.68] "kWh" Vector__XXX
 SG_ BMS_idealEnergyRemainingBuffered m56 : 40|16@1+ (0.02,0) [0|1310.68] "kWh" Vector__XXX
 SG_ BMS_largestSynchronizedCacErrorP m56 : 56|8@1+ (0.1,0) [0|25.4] "%" Vector__XXX
 SG_ BMS_largestCacSpreadErrorLower m64 : 8|12@1+ (0.1,0) [0|409.4] "Ah" Vector__XXX
 SG_ BMS_lifeModelAverageCac m64 : 20|12@1+ (0.1,0) [0|409.4] "Ah" Vector__XXX
 SG_ BMS_lifeModelCacBrick1 m64 : 32|12@1+ (0.1,0) [0|409.4] "Ah" Vector__XXX
 SG_ BMS_lifeModelAverageOffset m64 : 44|10@1- (0.1,0) [-51.1|51.1] "Ah" Vector__XXX
 SG_ BMS_percentCacUpdatesInTimeWindo m64 : 54|10@1+ (0.1,0) [0|100] "%" Vector__XXX
 SG_ BMS_lifeModelMaxCacBrickId m65 : 8|8@1+ (1,1) [1|255] "" Vector__XXX
 SG_ BMS_lifeModelMaxCac m65 : 16|12@1+ (0.1,0) [0|409.4] "Ah" Vector__XXX
 SG_ BMS_lifeModelMinCacBrickId m65 : 28|8@1+ (1,1) [1|255] "" Vector__XXX
 SG_ BMS_lifeModelMinCac m65 : 36|12@1+ (0.1,0) [0|409.4] "Ah" Vector__XXX
 SG_ BMS_restingPointCacAvg m65 : 48|12@1+ (0.1,0) [0|409.4] "Ah" Vector__XXX
 SG_ BMS_cacEstimationSource m65 : 60|2@1+ (1,0) [0|3] "" Vector__XXX
 SG_ BMS_synchronizedCacMaxRaw m71 : 8|12@1+ (0.1,0) [0|409.4] "Ah" Vector__XXX
 SG_ BMS_synchronizedCacMinRaw m71 : 20|12@1+ (0.1,0) [0|409.4] "Ah" Vector__XXX
 SG_ BMS_largestSyncCacErrorStartSoc m71 : 32|10@1+ (0.1,0) [0|102.2] "%" Vector__XXX
 SG_ BMS_largestSyncCacErrorEndSoc m71 : 42|10@1+ (0.1,0) [0|102.2] "%" Vector__XXX
 SG_ BMS_runtimeSocConfigNvramValid m71 : 52|1@1+ (1,0) [0|1] "" Vector__XXX
 SG_ BMS_runtimeSocCorrectionsEnabled m71 : 53|1@1+ (1,0) [0|1] "" Vector__XXX
 SG_ BMS_rubberBandingEnabled m71 : 54|1@1+ (1,0) [0|1] "" Vector__XXX
 SG_ BMS_rubberBandingConfigNvramVali m71 : 55|1@1+ (1,0) [0|1] "" Vector__XXX
 SG_ BMS_runtimeSocMinTempForModel m71 : 56|6@1+ (0.5,0) [0|20] "DegC" Vector__XXX
 SG_ BMS_energyBufferConfigNvramValid m71 : 62|1@1+ (1,0) [0|1] "" Vector__XXX
 SG_ BMS_thermalEvent1pDetectConfigDi m71 : 63|1@1+ (1,0) [0|1] "" Vector__XXX
 SG_ BMS_sohEnergy m79 : 8|11@1+ (0.1,0) [0|204.7] "KWh" Vector__XXX
 SG_ BMS_fullCapacitySohEnergy m79 : 19|11@1+ (0.1,0) [0|204.7] "KWh" Vector__XXX
 SG_ BMS_calibratedCapacitySohEnergy m79 : 30|11@1+ (0.1,0) [0|204.7] "KWh" Vector__XXX
 SG_ BMS_estimatedCapacitySohEnergy m79 : 41|11@1+ (0.1,0) [0|204.7] "KWh" Vector__XXX
 SG_ BMS_prevUserFacingSohEnergy m79 : 52|11@1+ (0.1,0) [0|204.7] "KWh" Vector__XXX
 SG_ BMS_stateOfHealthMinCac m80 : 8|13@1+ (0.1,0) [0|819] "Ah" Vector__XXX
 SG_ BMS_lifeModelStorageLossPackAge m80 : 24|14@1+ (1,0) [0|16382] "days" Vector__XXX
 SG_ BMS_lifeModelThroughputDcrCycleC m80 : 38|12@1+ (1,0) [0|4094] "Cycles" Vector__XXX
 SG_ BMS_stateOfHealthMinCacLowerBoun m80 : 50|13@1+ (0.1,0) [0|819] "Ah" Vector__XXX
 SG_ BMS_energyWalkCounter m83 : 8|8@1+ (1,0) [0|255] "" Vector__XXX
 SG_ BMS_energyWalkTimeoutCounter m83 : 16|8@1+ (1,0) [0|255] "" Vector__XXX
 SG_ BMS_dynamicCcvEnabled m83 : 24|1@1+ (1,0) [0|1] "" Vector__XXX
 SG_ BMS_chargeTargetLookupSoc m83 : 25|10@1+ (0.1,0) [0|102.2] "%" Vector__XXX
 SG_ BMS_stateOfHealth m83 : 35|10@1+ (0.1,0) [0|100] "%" Vector__XXX
 SG_ BMS_avgShuntAsicCurrentOffset m83 : 48|15@1- (0.2,0) [-3276.6|3276.6] "mA" Vector__XXX
 SG_ BMS_cellAttributesGeneralAttribu m85 : 7|32@1+ (1,0) [0|4294967295] "" Vector__XXX
 SG_ BMS_cellAttributesPackManufactur m85 : 39|3@1+ (1,0) [0|7] "" Vector__XXX
 SG_ BMS_cellAttributesRemanufactured m85 : 42|1@1+ (1,0) [0|1] "" Vector__XXX
 SG_ BMS_cellAttributesConfigNvramVal m85 : 43|1@1+ (1,0) [0|1] "" Vector__XXX
 SG_ BMS_cellAttributesCellType m85 : 44|6@1+ (1,0) [0|63] "" Vector__XXX
 SG_ BMS_cellAttributesAutocloseAndSc m85 : 50|1@1+ (1,0) [0|1] "" Vector__XXX
 SG_ BMS_cellAttributesShipPackForFai m85 : 51|1@1+ (1,0) [0|1] "" Vector__XXX
 SG_ BMS_lifeModelThroughputCycleCoun m85 : 52|12@1+ (1,0) [0|4094] "Cycles" Vector__XXX
 SG_ BMS_limpChargeCurrentLimit m89 : 8|10@1+ (1,0) [0|1022] "A" Vector__XXX
 SG_ BMS_energyRemainingDisplayError m89 : 18|10@1- (0.1,0) [-50|50] "kWh" Vector__XXX
 SG_ BMS_energyRemainingTDisplayError m89 : 28|10@1- (0.1,0) [-50|50] "kWh" Vector__XXX
 SG_ BMS_numOfThermistors m89 : 38|5@1+ (1,0) [0|31] "" Vector__XXX
 SG_ BMS_numOfBricks m89 : 43|8@1+ (1,0) [0|255] "" Vector__XXX
 SG_ BMS_cellChargeDcCurrentLimit m89 : 51|12@1+ (0.5,0) [0|2047.5] "A" Vector__XXX
 SG_ BMS_socByDeltaVEnabled m90 : 8|1@1+ (1,0) [0|1] "" Vector__XXX
 SG_ BMS_socByDvMaxSocLimit m90 : 9|10@1+ (0.1,0) [0|102.2] "%" Vector__XXX
 SG_ BMS_socByDvVoltageChangeOverAh m90 : 19|9@1+ (0.002,0) [0|1] "V" Vector__XXX
 SG_ BMS_socByDvMaxSocByAhCorrected m90 : 28|10@1+ (0.1,0) [0|102.2] "%" Vector__XXX
 SG_ BMS_socByDvMaxBrickVoltage m90 : 40|12@1+ (0.002,0) [0|5] "V" Vector__XXX
 SG_ BMS_socByDvMaxBrickId m90 : 56|8@1+ (1,1) [1|256] "" Vector__XXX
 SG_ BMS_socByDvMaxSocByAhRaw m91 : 8|10@1+ (0.1,0) [0|102.2] "%" Vector__XXX
 SG_ BMS_voltageInstabilityExcessNois m91 : 18|12@1+ (0.1,0) [0|408] "counts" Vector__XXX
 SG_ BMS_maxModelThermistorTempDelta m91 : 30|10@1- (0.1,0) [-51.2|51.1] "C" Vector__XXX
 SG_ BMS_activeCoolCellTargetT m91 : 40|9@1+ (0.25,-25) [-25|100] "DegC" Vector__XXX
 SG_ BMS_cellTempTargetMode m91 : 49|4@1+ (1,0) [0|15] "" Vector__XXX
 SG_ BMS_minPackTempForChargeToStart m91 : 56|7@1+ (0.5,-40) [-40|23.5] "C" Vector__XXX

BO_ 914 BMS_packConfig: 8 BMS
 SG_ BMS_packConfigMultiplexer M : 0|8@1+ (1,0) [0|255] "" Vector__XXX
 SG_ BMS_reservedConfig_0 m0 : 8|6@1+ (1,0) [0|63] "" Vector__XXX
 SG_ BMS_moduleType m1 : 8|3@1+ (1,0) [0|7] "" Vector__XXX
 SG_ BMS_thermalPackType m1 : 11|4@1+ (1,0) [0|15] "" Vector__XXX
 SG_ BMS_packMass m1 : 16|8@1+ (1,300) [342|540] "kg" Vector__XXX
 SG_ BMS_platformMaxBusVoltage m1 : 24|10@1+ (1,300) [300|1300] "V" Vector__XXX
 SG_ BMS_standbySupplyContinuousPower m1 : 36|2@1+ (1,0) [0|3] "" Vector__XXX
 SG_ BMS_beginningOfLifePackEnergy m1 : 40|10@1+ (0.1,0) [0|102.2] "KWh" Vector__XXX

BO_ 1810 BMS_packTemperatureMeasurements: 8 BMS
 SG_ BMS_packTemperatureMultiplexer M : 0|8@1+ (1,0) [0|255] "" Vector__XXX
 SG_ BMS_packTemperatureCounter : 14|2@1+ (1,0) [0|3] "" Vector__XXX
 SG_ BMS_packTemperatureStatus1 m0 : 8|2@1+ (1,0) [0|3] "" Vector__XXX
 SG_ BMS_packTemperatureStatus2 m0 : 10|2@1+ (1,0) [0|3] "" Vector__XXX
 SG_ BMS_packTemperatureStatus3 m0 : 12|2@1+ (1,0) [0|3] "" Vector__XXX
 SG_ BMS_packTemperature1 m0 : 16|16@1- (0.01,0) [-327.68|327.67] "C" Vector__XXX
 SG_ BMS_packTemperature2 m0 : 32|16@1- (0.01,0) [-327.68|327.67] "C" Vector__XXX
 SG_ BMS_packTemperature3 m0 : 48|16@1- (0.01,0) [-327.68|327.67] "C" Vector__XXX
 SG_ BMS_packTemperatureStatus4 m1 : 8|2@1+ (1,0) [0|3] "" Vector__XXX
 SG_ BMS_packTemperatureStatus5 m1 : 10|2@1+ (1,0) [0|3] "" Vector__XXX
 SG_ BMS_packTemperatureStatus6 m1 : 12|2@1+ (1,0) [0|3] "" Vector__XXX
 SG_ BMS_packTemperature4 m1 : 16|16@1- (0.01,0) [-327.68|327.67] "C" Vector__XXX
 SG_ BMS_packTemperature5 m1 : 32|16@1- (0.01,0) [-327.68|327.67] "C" Vector__XXX
 SG_ BMS_packTemperature6 m1 : 48|16@1- (0.01,0) [-327.68|327.67] "C" Vector__XXX
 SG_ BMS_packTemperatureStatus7 m2 : 8|2@1+ (1,0) [0|3] "" Vector__XXX
 SG_ BMS_packTemperatureStatus8 m2 : 10|2@1+ (1,0) [0|3] "" Vector__XXX
 SG_ BMS_packTemperatureStatus9 m2 : 12|2@1+ (1,0) [0|3] "" Vector__XXX
 SG_ BMS_packTemperature7 m2 : 16|16@1- (0.01,0) [-327.68|327.67] "C" Vector__XXX
 SG_ BMS_packTemperature8 m2 : 32|16@1- (0.01,0) [-327.68|327.67] "C" Vector__XXX
 SG_ BMS_packTemperature9 m2 : 48|16@1- (0.01,0) [-327.68|327.67] "C" Vector__XXX
 SG_ BMS_packTemperatureStatus10 m3 : 8|2@1+ (1,0) [0|3] "" Vector__XXX
 SG_ BMS_packTemperatureStatus11 m3 : 10|2@1+ (1,0) [0|3] "" Vector__XXX
 SG_ BMS_packTemperatureStatus12 m3 : 12|2@1+ (1,0) [0|3] "" Vector__XXX
 SG_ BMS_packTemperature10 m3 : 16|16@1- (0.01,0) [-327.68|327.67] "C" Vector__XXX
 SG_ BMS_packTemperature11 m3 : 32|16@1- (0.01,0) [-327.68|327.67] "C" Vector__XXX
 SG_ BMS_packTemperature12 m3 : 48|16@1- (0.01,0) [-327.68|327.67] "C" Vector__XXX
 SG_ BMS_packTemperatureStatus13 m4 : 8|2@1+ (1,0) [0|3] "" Vector__XXX
 SG_ BMS_packTemperatureStatus14 m4 : 10|2@1+ (1,0) [0|3] "" Vector__XXX
 SG_ BMS_packTemperatureStatus15 m4 : 12|2@1+ (1,0) [0|3] "" Vector__XXX
 SG_ BMS_packTemperature13 m4 : 16|16@1- (0.01,0) [-327.68|327.67] "C" Vector__XXX
 SG_ BMS_packTemperature14 m4 : 32|16@1- (0.01,0) [-327.68|327.67] "C" Vector__XXX
 SG_ BMS_packTemperature15 m4 : 48|16@1- (0.01,0) [-327.68|327.67] "C" Vector__XXX
 SG_ BMS_packTemperatureStatus16 m5 : 8|2@1+ (1,0) [0|3] "" Vector__XXX
 SG_ BMS_packTemperatureStatus17 m5 : 10|2@1+ (1,0) [0|3] "" Vector__XXX
 SG_ BMS_packTemperatureStatus18 m5 : 12|2@1+ (1,0) [0|3] "" Vector__XXX
 SG_ BMS_packTemperature16 m5 : 16|16@1- (0.01,0) [-327.68|327.67] "C" Vector__XXX
 SG_ BMS_packTemperature17 m5 : 32|16@1- (0.01,0) [-327.68|327.67] "C" Vector__XXX
 SG_ BMS_packTemperature18 m5 : 48|16@1- (0.01,0) [-327.68|327.67] "C" Vector__XXX

BO_ 594 BMS_powerAvailable: 8 BMS
 SG_ BMS_maxRegenPower : 0|16@1+ (0.01,0) [0|655.35] "kW" Vector__XXX
 SG_ BMS_maxDischargePower : 16|16@1+ (0.013,0) [0|850] "kW" Vector__XXX
 SG_ BMS_maxStationaryHeatPower : 32|10@1+ (0.01,0) [0|10.23] "kW" Vector__XXX
 SG_ BMS_powerLimitsState : 42|1@1+ (1,0) [0|1] "" Vector__XXX
 SG_ BMS_totalHvPowerBudget : 43|9@1+ (0.1,0) [0|51.1] "kW" Vector__XXX
 SG_ BMS_notEnoughPowerForHeatPump : 52|1@1+ (1,0) [0|1] "" Vector__XXX

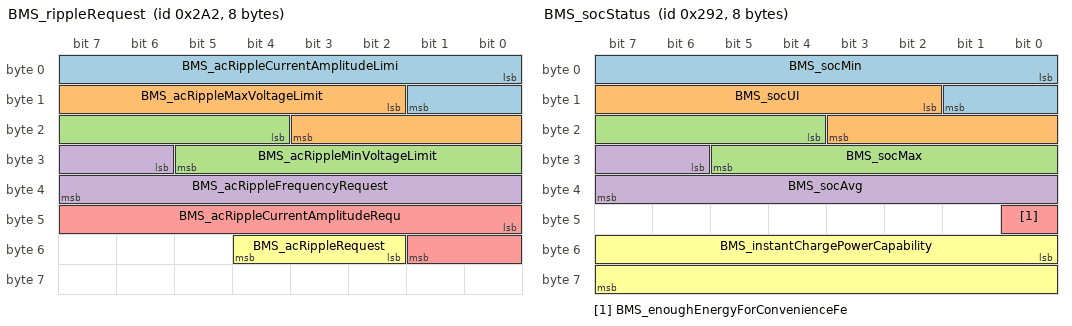
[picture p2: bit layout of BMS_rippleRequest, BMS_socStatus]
BO_ 674 BMS_rippleRequest: 8 BMS
 SG_ BMS_acRippleCurrentAmplitudeLimi : 0|10@1+ (1,0) [0|1023] "A" Vector__XXX
 SG_ BMS_acRippleMaxVoltageLimit : 10|10@1+ (1,0) [0|1023] "V" Vector__XXX
 SG_ BMS_acRippleMinVoltageLimit : 20|10@1+ (1,0) [0|1023] "V" Vector__XXX
 SG_ BMS_acRippleFrequencyRequest : 30|10@1+ (1,0) [0|1022] "Hz" Vector__XXX
 SG_ BMS_acRippleCurrentAmplitudeRequ : 40|10@1+ (1,0) [0|1023] "A" Vector__XXX
 SG_ BMS_acRippleRequest : 50|3@1+ (1,0) [0|7] "" Vector__XXX

BO_ 658 BMS_socStatus: 8 BMS
 SG_ BMS_socMin : 0|10@1+ (0.1,0) [0|102.2] "%" Vector__XXX
 SG_ BMS_socUI : 10|10@1+ (0.1,0) [0|100] "%" Vector__XXX
 SG_ BMS_socMax : 20|10@1+ (0.1,0) [0|102.2] "%" Vector__XXX
 SG_ BMS_socAvg : 30|10@1+ (0.1,0) [0|102.2] "%" Vector__XXX
 SG_ BMS_enoughEnergyForConvenienceFe : 40|1@1+ (1,0) [0|1] "" Vector__XXX
 SG_ BMS_instantChargePowerCapability : 48|16@1+ (0.05,0) [0|3276.75] "kW" Vector__XXX

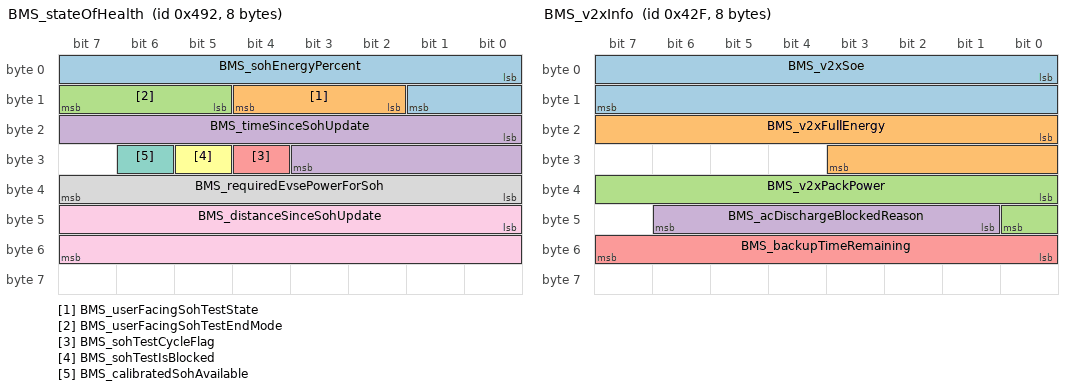
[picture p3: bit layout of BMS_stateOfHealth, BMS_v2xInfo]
BO_ 1170 BMS_stateOfHealth: 8 BMS
 SG_ BMS_sohEnergyPercent : 0|10@1+ (0.1,0) [0|100] "%" Vector__XXX
 SG_ BMS_userFacingSohTestState : 10|3@1+ (1,0) [0|7] "" Vector__XXX
 SG_ BMS_userFacingSohTestEndMode : 13|3@1+ (1,0) [0|7] "" Vector__XXX
 SG_ BMS_timeSinceSohUpdate : 16|12@1+ (1,0) [0|3650] "days" Vector__XXX
 SG_ BMS_sohTestCycleFlag : 28|1@1+ (1,0) [0|1] "" Vector__XXX
 SG_ BMS_sohTestIsBlocked : 29|1@1+ (1,0) [0|1] "" Vector__XXX
 SG_ BMS_calibratedSohAvailable : 30|1@1+ (1,0) [0|1] "" Vector__XXX
 SG_ BMS_requiredEvsePowerForSoh : 32|8@1+ (0.125,0) [0|31.75] "kW" Vector__XXX
 SG_ BMS_distanceSinceSohUpdate : 40|16@1+ (1,0) [0|65534] "km" Vector__XXX

BO_ 530 BMS_status: 8 BMS
 SG_ BMS_hvacPowerRequest : 0|1@1+ (1,0) [0|1] "" Vector__XXX
 SG_ BMS_notEnoughPowerForDrive : 1|1@1+ (1,0) [0|1] "" Vector__XXX
 SG_ BMS_notEnoughPowerForSupport : 2|1@1+ (1,0) [0|1] "" Vector__XXX
 SG_ BMS_preconditionAllowed : 3|1@1+ (1,0) [0|1] "" Vector__XXX
 SG_ BMS_updateAllowed : 4|1@1+ (1,0) [0|1] "" Vector__XXX
 SG_ BMS_cpMiaOnHvs : 5|1@1+ (1,0) [0|1] "" Vector__XXX
 SG_ BMS_pcsPwmEnabled : 6|1@1+ (1,0) [0|1] "" Vector__XXX
 SG_ BMS_contactorState : 8|3@1+ (1,0) [0|7] "" Vector__XXX
 SG_ BMS_userChargeStatus : 11|3@1+ (1,0) [0|7] "" Vector__XXX
 SG_ BMS_batteryInputPower : 14|16@1+ (0.05,0) [0|3276.75] "kW" Vector__XXX
 SG_ BMS_chargeRequest : 30|1@1+ (1,0) [0|1] "" Vector__XXX
 SG_ BMS_state : 32|4@1+ (1,0) [0|15] "" Vector__XXX
 SG_ BMS_diLimpRequest : 36|1@1+ (1,0) [0|1] "" Vector__XXX
 SG_ BMS_okToShipByAir : 37|1@1+ (1,0) [0|1] "" Vector__XXX
 SG_ BMS_okToShipByLand : 38|1@1+ (1,0) [0|1] "" Vector__XXX
 SG_ BMS_chgPowerAvailable : 39|12@1+ (0.125,0) [0|511.75] "kW" Vector__XXX
 SG_ BMS_acManagerState : 52|4@1+ (1,0) [0|15] "" Vector__XXX
 SG_ BMS_conditioningRequest : 56|1@1+ (1,0) [0|1] "" Vector__XXX
 SG_ BMS_smStateRequest : 57|4@1+ (1,0) [0|15] "" Vector__XXX
 SG_ BMS_hvState : 61|3@1+ (1,0) [0|7] "" Vector__XXX

BO_ 786 BMS_thermalStatus: 8 BMS
 SG_ BMS_thermalStatusMultiplexer M : 0|2@1+ (1,0) [0|3] "" Vector__XXX
 SG_ BMS_inletActiveCoolTargetT m0 : 2|9@1+ (0.25,-25) [-25|100] "DegC" Vector__XXX
 SG_ BMS_inletPassiveTargetT m0 : 11|9@1+ (0.25,-25) [-25|100] "DegC" Vector__XXX
 SG_ BMS_inletActiveHeatTargetT m0 : 20|9@1+ (0.25,-25) [-25|100] "DegC" Vector__XXX
 SG_ BMS_requestDischarge m0 : 29|1@1+ (1,0) [0|1] "" Vector__XXX
 SG_ BMS_activeHeatingWorthwhile m0 : 30|1@1+ (1,0) [0|1] "" Vector__XXX
 SG_ BMS_pcsNoFlowRequest m0 : 31|1@1+ (1,0) [0|1] "" Vector__XXX
 SG_ BMS_minPackTemperature m0 : 32|10@1+ (0.2,-40) [-40|164.6] "DegC" Vector__XXX
 SG_ BMS_noFlowRequest m0 : 42|1@1+ (1,0) [0|1] "" Vector__XXX
 SG_ BMS_maxPackTemperature m0 : 43|11@1+ (0.1,-40) [-40|164.7] "DegC" Vector__XXX
 SG_ BMS_flowRequest m0 : 56|8@1+ (0.25,0) [0|60] "LPM" Vector__XXX
 SG_ BMS_coldStagnationLimit m1 : 2|9@1+ (0.25,-25) [-25|100] "DegC" Vector__XXX
 SG_ BMS_hotStagnationLimit m1 : 11|9@1+ (0.25,-25) [-25|100] "DegC" Vector__XXX
 SG_ BMS_hotCellTempLimit m1 : 20|9@1+ (0.25,-25) [-25|100] "DegC" Vector__XXX
 SG_ BMS_i2tDeratingEnabled m1 : 29|1@1+ (1,0) [0|1] "" Vector__XXX
 SG_ BMS_activeCoolCellReferenceT m1 : 32|9@1+ (0.25,-25) [-25|100] "DegC" Vector__XXX
 SG_ BMS_activeHeatCellTargetT m1 : 41|9@1+ (0.25,-25) [-25|100] "DegC" Vector__XXX
 SG_ BMS_powerDissipation m1 : 50|10@1+ (0.02,0) [0|20] "kW" Vector__XXX

BO_ 1071 BMS_v2xInfo: 8 BMS
 SG_ BMS_v2xSoe : 0|16@1+ (0.002,0) [0|100] "%" Vector__XXX
 SG_ BMS_v2xFullEnergy : 16|12@1+ (0.05,0) [0|200] "kWh" Vector__XXX
 SG_ BMS_v2xPackPower : 32|9@1+ (0.1,-25) [-25|25] "kW" Vector__XXX
 SG_ BMS_acDischargeBlockedReason : 41|6@1+ (1,0) [0|63] "" Vector__XXX
 SG_ BMS_backupTimeRemaining : 48|8@1+ (1,0) [0|254] "Hours" Vector__XXX

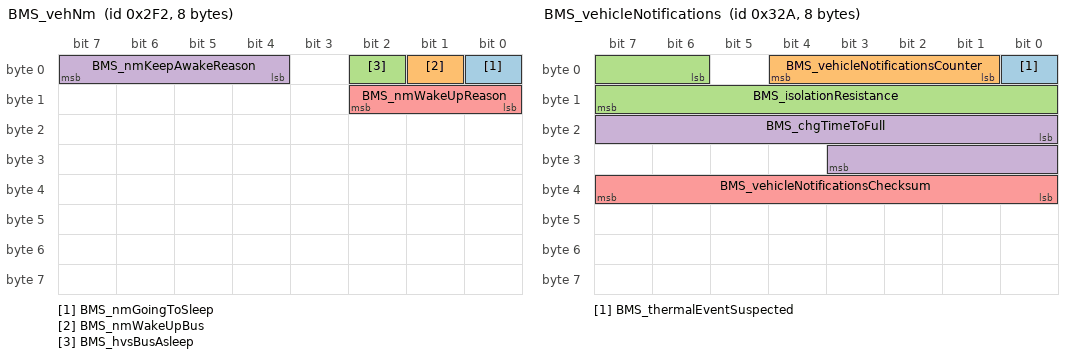
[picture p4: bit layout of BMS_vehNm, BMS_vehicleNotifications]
BO_ 754 BMS_vehNm: 8 BMS
 SG_ BMS_nmGoingToSleep : 0|1@1+ (1,0) [0|1] "" Vector__XXX
 SG_ BMS_nmWakeUpBus : 1|1@1+ (1,0) [0|1] "" Vector__XXX
 SG_ BMS_hvsBusAsleep : 2|1@1+ (1,0) [0|1] "" Vector__XXX
 SG_ BMS_nmKeepAwakeReason : 4|4@1+ (1,0) [0|15] "" Vector__XXX
 SG_ BMS_nmWakeUpReason : 8|3@1+ (1,0) [0|7] "" Vector__XXX

BO_ 810 BMS_vehicleNotifications: 8 BMS
 SG_ BMS_thermalEventSuspected : 0|1@1+ (1,0) [0|1] "" Vector__XXX
 SG_ BMS_vehicleNotificationsCounter : 1|4@1+ (1,0) [0|15] "" Vector__XXX
 SG_ BMS_isolationResistance : 6|10@1+ (10,0) [0|10000] "kOhm" Vector__XXX
 SG_ BMS_chgTimeToFull : 16|12@1+ (0.01666667,0) [0|68.25001365] "Hours" Vector__XXX
 SG_ BMS_vehicleNotificationsChecksum : 32|8@1+ (1,0) [0|255] "" Vector__XXX

BO_ 1116 CC_alertLog: 8 CC
 SG_ CC_alertID M : 0|15@1+ (1,0) [0|32767] "" Vector__XXX
 SG_ CC_alertType : 15|1@1+ (1,0) [0|1] "" Vector__XXX
 SG_ CC_a001_groundResistance m1 : 16|12@1+ (1000,0) [0|4095000] "" Vector__XXX
 SG_ CC_a003_gfciRmsCurrent m3 : 16|12@1+ (0.001,0) [0|4.095] "" Vector__XXX
 SG_ CC_a003_gfciRmsCurrentAvg m3 : 28|12@1+ (0.001,0) [0|4.095] "" Vector__XXX
 SG_ CC_a003_dcGfciCurrent m3 : 40|10@1- (0.001,0) [-0.512|0.511] "" Vector__XXX
 SG_ CC_a003_gfciFaultReason m3 : 50|4@1+ (1,0) [0|15] "" Vector__XXX
 SG_ CC_a003_gfciFaultBucket m3 : 56|4@1+ (1,0) [0|15] "" Vector__XXX
 SG_ CC_a004_gfciErrorReason m4 : 16|8@1+ (1,0) [0|255] "" Vector__XXX
 SG_ CC_a004_gfciAsicErrorBitfield m4 : 24|8@1+ (1,0) [0|255] "" Vector__XXX
 SG_ CC_a004_gfciSelfTestDuty m4 : 32|16@1- (0.0001,50) [46.7232|53.2767] "" Vector__XXX
 SG_ CC_a004_gfciSelfTestCurrent m4 : 48|16@1- (0.0001,0) [-3.2768|3.2767] "" Vector__XXX
 SG_ CC_a006_line1Current m6 : 16|16@1+ (0.01,0) [0|655.35] "" Vector__XXX
 SG_ CC_a006_line2Current m6 : 32|16@1+ (0.01,0) [0|655.35] "" Vector__XXX
 SG_ CC_a006_line3Current m6 : 48|16@1+ (0.01,0) [0|655.35] "" Vector__XXX
 SG_ CC_a007_inputVoltage m7 : 16|16@1+ (0.01,0) [0|655.35] "" Vector__XXX
 SG_ CC_a007_inputLineVoltage m7 : 32|16@1+ (0.01,0) [0|655.35] "" Vector__XXX
 SG_ CC_a007_inputNeutralVoltage m7 : 48|16@1+ (0.01,0) [0|655.35] "" Vector__XXX
 SG_ CC_a008_inputVoltage m8 : 16|16@1+ (0.01,0) [0|655.35] "" Vector__XXX
 SG_ CC_a008_inputLineVoltage m8 : 32|16@1+ (0.01,0) [0|655.35] "" Vector__XXX
 SG_ CC_a008_inputNeutralVoltage m8 : 48|16@1+ (0.01,0) [0|655.35] "" Vector__XXX
 SG_ CC_a010_line1Voltage m10 : 16|12@1+ (0.1,0) [0|409.5] "" Vector__XXX
 SG_ CC_a010_line2Voltage m10 : 28|12@1+ (0.1,0) [0|409.5] "" Vector__XXX
 SG_ CC_a010_line3Voltage m10 : 40|12@1+ (0.1,0) [0|409.5] "" Vector__XXX
 SG_ CC_a010_line1StuckClosed m10 : 52|1@1+ (1,0) [0|1] "" Vector__XXX
 SG_ CC_a010_line2StuckClosed m10 : 53|1@1+ (1,0) [0|1] "" Vector__XXX
 SG_ CC_a010_line3StuckClosed m10 : 54|1@1+ (1,0) [0|1] "" Vector__XXX
 SG_ CC_a011_pcbaTemp m11 : 16|9@1- (1,88) [-168|343] "" Vector__XXX
 SG_ CC_a012_inputThermopile m12 : 16|12@1+ (1.0e-06,0) [0|0.004095] "" Vector__XXX
 SG_ CC_a012_inputThermopileDvdt m12 : 28|12@1+ (1.0e-06,0) [0|0.004095] "" Vector__XXX
 SG_ CC_a013_handleTemp m13 : 16|9@1- (1,88) [-168|343] "" Vector__XXX
 SG_ CC_a014_failureCause m14 : 16|9@1+ (1,0) [0|511] "" Vector__XXX
 SG_ CC_a014_meterFaultAddress m14 : 25|16@1+ (1,0) [0|65535] "" Vector__XXX
 SG_ CC_a014_meterFaultData m14 : 41|16@1+ (1,0) [0|65535] "" Vector__XXX
 SG_ CC_a014_meterRetryCount m14 : 57|4@1+ (1,0) [0|15] "" Vector__XXX
 SG_ CC_a015_pilotHighVolage m15 : 16|16@1+ (0.001,0) [0|65.535] "" Vector__XXX
 SG_ CC_a015_smState m15 : 32|8@1+ (1,0) [0|255] "" Vector__XXX
 SG_ CC_a027_handleTemperature m27 : 16|12@1- (0.1,0) [-204.8|204.7] "" Vector__XXX
 SG_ CC_a027_handleTempFaultReason m27 : 28|4@1+ (1,0) [0|15] "" Vector__XXX
 SG_ CC_a032_meteringSpiCommsFailure m32 : 16|1@1+ (1,0) [0|1] "" Vector__XXX
 SG_ CC_a032_meteringConfigMismatch m32 : 17|1@1+ (1,0) [0|1] "" Vector__XXX
 SG_ CC_a033_nominalVoltage m33 : 16|9@1+ (0.01,0) [0|5.11] "" Vector__XXX
 SG_ CC_a033_measuredVoltage m33 : 25|9@1+ (0.01,0) [0|5.11] "" Vector__XXX
 SG_ CC_a036_line1Voltage m36 : 16|12@1+ (0.1,0) [0|409.5] "" Vector__XXX
 SG_ CC_a036_line2Voltage m36 : 28|12@1+ (0.1,0) [0|409.5] "" Vector__XXX
 SG_ CC_a036_line3Voltage m36 : 40|12@1+ (0.1,0) [0|409.5] "" Vector__XXX
 SG_ CC_a036_line1StuckOpen m36 : 52|1@1+ (1,0) [0|1] "" Vector__XXX
 SG_ CC_a036_line2StuckOpen m36 : 53|1@1+ (1,0) [0|1] "" Vector__XXX
 SG_ CC_a036_line3StuckOpen m36 : 54|1@1+ (1,0) [0|1] "" Vector__XXX
 SG_ CC_a037_expiredWatchdogModuleId m37 : 16|8@1+ (1,0) [0|255] "" Vector__XXX
 SG_ CC_a037_expiredWatchdogTaskId m37 : 24|8@1+ (1,0) [0|255] "" Vector__XXX
 SG_ CC_a037_expiredWatchdogAppCRC m37 : 32|32@1+ (1,0) [0|4294967295] "" Vector__XXX
 SG_ CC_a038_moduleMiaModuleId m38 : 16|8@1+ (1,0) [0|255] "" Vector__XXX
 SG_ CC_a038_moduleMiaTaskId m38 : 24|8@1+ (1,0) [0|255] "" Vector__XXX
 SG_ CC_a038_moduleMiaAppCRC m38 : 32|32@1+ (1,0) [0|4294967295] "" Vector__XXX
 SG_ CC_a039_intModuleTemperature m39 : 16|9@1- (1,88) [-168|343] "" Vector__XXX
 SG_ CC_a040_handleTemperature m40 : 16|9@1- (1,88) [-168|343] "" Vector__XXX
 SG_ CC_a041_inputThermopile m41 : 16|16@1- (1.0e-06,0) [-0.032768|0.032767] "" Vector__XXX
 SG_ CC_a041_inputThermopileDvdt m41 : 32|16@1- (1.0e-06,0) [-0.032768|0.032767] "" Vector__XXX
 SG_ CC_a042_pcbaTemperature m42 : 16|9@1- (1,88) [-168|343] "" Vector__XXX
 SG_ CC_a044_relayCoilVoltage m44 : 16|8@1+ (0.14,0) [0|35.7] "" Vector__XXX
 SG_ CC_a044_pcbaTemperature m44 : 24|9@1- (1,88) [-168|343] "" Vector__XXX

BO_ 1132 CC_alertMatrix1: 8 CC
 SG_ CC_a001_gndMonIntrptLineSide : 0|1@1+ (1,0) [0|1] "" Vector__XXX
 SG_ CC_a002_gndMonIntrptLoadSide : 1|1@1+ (1,0) [0|1] "" Vector__XXX
 SG_ CC_a003_CCIDTripped : 2|1@1+ (1,0) [0|1] "" Vector__XXX
 SG_ CC_a004_CCIDSelfTestFault : 3|1@1+ (1,0) [0|1] "" Vector__XXX
 SG_ CC_a005_groundedNeutral : 4|1@1+ (1,0) [0|1] "" Vector__XXX
 SG_ CC_a006_inputOverCurrent : 5|1@1+ (1,0) [0|1] "" Vector__XXX
 SG_ CC_a007_inputOverVoltage : 6|1@1+ (1,0) [0|1] "" Vector__XXX
 SG_ CC_a008_inputUnderVoltage : 7|1@1+ (1,0) [0|1] "" Vector__XXX
 SG_ CC_a009_inputMiswired : 8|1@1+ (1,0) [0|1] "" Vector__XXX
 SG_ CC_a010_contactorWelded : 9|1@1+ (1,0) [0|1] "" Vector__XXX
 SG_ CC_a011_ambientOT : 10|1@1+ (1,0) [0|1] "" Vector__XXX
 SG_ CC_a012_wallPlugOT : 11|1@1+ (1,0) [0|1] "" Vector__XXX
 SG_ CC_a013_vehConnOT : 12|1@1+ (1,0) [0|1] "" Vector__XXX
 SG_ CC_a014_mcuSelfTestFault : 13|1@1+ (1,0) [0|1] "" Vector__XXX
 SG_ CC_a015_PilotAFault : 14|1@1+ (1,0) [0|1] "" Vector__XXX
 SG_ CC_a016_PilotBFault : 15|1@1+ (1,0) [0|1] "" Vector__XXX
 SG_ CC_a017_PilotCFault : 16|1@1+ (1,0) [0|1] "" Vector__XXX
 SG_ CC_a018_PilotDFault : 17|1@1+ (1,0) [0|1] "" Vector__XXX
 SG_ CC_a019_proxDisconnected : 18|1@1+ (1,0) [0|1] "" Vector__XXX
 SG_ CC_a020_3vRailIncorrect : 19|1@1+ (1,0) [0|1] "" Vector__XXX
 SG_ CC_a021_CB_noMaster : 20|1@1+ (1,0) [0|1] "" Vector__XXX
 SG_ CC_a022_CB_tooManyMasters : 21|1@1+ (1,0) [0|1] "" Vector__XXX
 SG_ CC_a023_CB_tooManySlaves : 22|1@1+ (1,0) [0|1] "" Vector__XXX
 SG_ CC_a024_CB_masterISetTooLow : 23|1@1+ (1,0) [0|1] "" Vector__XXX
 SG_ CC_a025_evseTemp : 24|1@1+ (1,0) [0|1] "" Vector__XXX
 SG_ CC_a026_wallPlugTemp : 25|1@1+ (1,0) [0|1] "" Vector__XXX
 SG_ CC_a027_vehicleHandleTemp : 26|1@1+ (1,0) [0|1] "" Vector__XXX
 SG_ CC_a028_CB_rotarySelect : 27|1@1+ (1,0) [0|1] "" Vector__XXX
 SG_ CC_a029_PilotFFault : 28|1@1+ (1,0) [0|1] "" Vector__XXX
 SG_ CC_a030_masterSlaveMismatch : 29|1@1+ (1,0) [0|1] "" Vector__XXX
 SG_ CC_a031_pllLockLost : 30|1@1+ (1,0) [0|1] "" Vector__XXX
 SG_ CC_a032_meteringFailure : 31|1@1+ (1,0) [0|1] "" Vector__XXX
 SG_ CC_a033_vRefOutOfRange : 32|1@1+ (1,0) [0|1] "" Vector__XXX
 SG_ CC_a034_bootAlert : 33|1@1+ (1,0) [0|1] "" Vector__XXX
 SG_ CC_a035_CCIDCalibration : 34|1@1+ (1,0) [0|1] "" Vector__XXX
 SG_ CC_a036_contactorStuckOpen : 35|1@1+ (1,0) [0|1] "" Vector__XXX
 SG_ CC_a037_internalModuleWatchdogEx : 36|1@1+ (1,0) [0|1] "" Vector__XXX
 SG_ CC_a038_internalModuleMia : 37|1@1+ (1,0) [0|1] "" Vector__XXX
 SG_ CC_a039_internalModuleOverTemp : 38|1@1+ (1,0) [0|1] "" Vector__XXX
 SG_ CC_a040_handleTempFoldback : 39|1@1+ (1,0) [0|1] "" Vector__XXX
 SG_ CC_a041_inputWiringFoldback : 40|1@1+ (1,0) [0|1] "" Vector__XXX
 SG_ CC_a042_pcbaTempFoldback : 41|1@1+ (1,0) [0|1] "" Vector__XXX
 SG_ CC_a043_configurationRequired : 42|1@1+ (1,0) [0|1] "" Vector__XXX
 SG_ CC_a044_relayCoilVoltageRational : 43|1@1+ (1,0) [0|1] "" Vector__XXX
 SG_ CC_a045_ACPowerLoss : 44|1@1+ (1,0) [0|1] "" Vector__XXX
 SG_ CC_a046_GFCIConfigInvalid : 45|1@1+ (1,0) [0|1] "" Vector__XXX
 SG_ CC_a047_MDMotorContFault : 46|1@1+ (1,0) [0|1] "" Vector__XXX
 SG_ CC_a048_ACMDAdapterFault : 47|1@1+ (1,0) [0|1] "" Vector__XXX
 SG_ CC_a049_rs485Fault : 48|1@1+ (1,0) [0|1] "" Vector__XXX
 SG_ CC_a050_eFuseFault : 49|1@1+ (1,0) [0|1] "" Vector__XXX
 SG_ CC_a051_chcCriticalFault : 50|1@1+ (1,0) [0|1] "" Vector__XXX
 SG_ CC_a052_vRefOutOfRangePWM : 51|1@1+ (1,0) [0|1] "" Vector__XXX
 SG_ CC_a057_chcVitalsRequestFailure : 56|1@1+ (1,0) [0|1] "" Vector__XXX
 SG_ CC_a060_persistenceFault : 59|1@1+ (1,0) [0|1] "" Vector__XXX
 SG_ CC_a061_unfinishedCommissioning : 60|1@1+ (1,0) [0|1] "" Vector__XXX

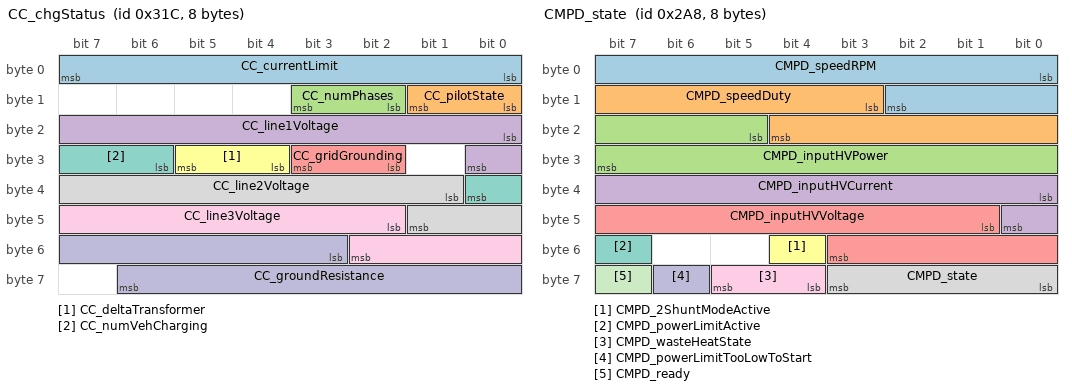
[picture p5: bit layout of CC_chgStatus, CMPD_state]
BO_ 796 CC_chgStatus: 8 CC
 SG_ CC_currentLimit : 0|8@1+ (0.5,0) [0|127.5] "A" Vector__XXX
 SG_ CC_pilotState : 8|2@1+ (1,0) [0|3] "" Vector__XXX
 SG_ CC_numPhases : 10|2@1+ (1,0) [0|3] "" Vector__XXX
 SG_ CC_line1Voltage : 16|9@1+ (1,0) [0|511] "V" Vector__XXX
 SG_ CC_gridGrounding : 26|2@1+ (1,0) [0|3] "" Vector__XXX
 SG_ CC_deltaTransformer : 28|2@1+ (1,0) [0|3] "" Vector__XXX
 SG_ CC_numVehCharging : 30|3@1+ (1,0) [0|7] "" Vector__XXX
 SG_ CC_line2Voltage : 33|9@1+ (1,0) [0|511] "V" Vector__XXX
 SG_ CC_line3Voltage : 42|9@1+ (1,0) [0|511] "V" Vector__XXX
 SG_ CC_groundResistance : 51|12@1+ (1,0) [0|4094] "kOhm" Vector__XXX

BO_ 797 CC_chgStatus2: 8 CC
 SG_ CC_chgStatus2Index M : 0|8@1+ (1,0) [0|255] "" Vector__XXX
 SG_ CC_buttonState m0 : 8|1@1+ (1,0) [0|1] "" Vector__XXX
 SG_ EVSE_v2xSupport m0 : 9|2@1+ (1,0) [0|3] "" Vector__XXX
 SG_ EVSE_v2xHandshakeStart m0 : 12|1@1+ (1,0) [0|1] "" Vector__XXX
 SG_ EVSE_v2xSessionType m0 : 13|2@1+ (1,0) [0|3] "" Vector__XXX

BO_ 812 CC_logData: 8 CC
 SG_ CC_logIndex M : 0|8@1+ (1,0) [0|255] "" Vector__XXX
 SG_ CC_activeConnectorID m0 : 8|8@1+ (1,0) [0|255] "" Vector__XXX
 SG_ CC_temperature1 m0 : 16|8@1- (1,88) [-40|215] "DegC" Vector__XXX
 SG_ CC_temperature2 m0 : 24|8@1- (1,88) [-40|215] "DegC" Vector__XXX
 SG_ CC_temperature3 m0 : 32|8@1- (1,88) [-40|215] "DegC" Vector__XXX
 SG_ CC_contactor1Closed m0 : 40|2@1+ (1,0) [0|3] "" Vector__XXX
 SG_ CC_contactor2Closed m0 : 42|2@1+ (1,0) [0|3] "" Vector__XXX
 SG_ CC_temperature4 m0 : 44|8@1- (1,88) [-40|215] "DegC" Vector__XXX
 SG_ CC_conn1Current m1 : 8|8@1+ (0.5,0) [0|127.5] "A" Vector__XXX
 SG_ CC_conn2Current m2 : 8|8@1+ (0.5,0) [0|127.5] "A" Vector__XXX
 SG_ CC_conn3Current m3 : 8|8@1+ (0.5,0) [0|127.5] "A" Vector__XXX
 SG_ CC_conn4Current m4 : 8|8@1+ (0.5,0) [0|127.5] "A" Vector__XXX
 SG_ CC_lifetimei2t m10 : 32|32@1+ (0.1,0) [0|429496729.5] "A2h" Vector__XXX
 SG_ CC_lifetimeCtrCycles m11 : 8|28@1+ (1,0) [0|268435455] "" Vector__XXX
 SG_ CC_lifetimeCtrCyclesLoaded m11 : 36|28@1+ (1,0) [0|268435455] "" Vector__XXX
 SG_ CC_lifetimeAlertCount m12 : 8|28@1+ (1,0) [0|268435455] "" Vector__XXX
 SG_ CC_lifetimeThermalFoldbacks m12 : 36|28@1+ (1,0) [0|268435455] "" Vector__XXX
 SG_ CC_lifetimeAvgStartupTemp m13 : 36|28@1- (0.1,0) [-13421772.8|13421772.7] "degC" Vector__XXX

BO_ 870 CMPD_info: 8 CMPD
 SG_ CMPD_infoIndex M : 0|8@1+ (1,0) [0|255] "" Vector__XXX
 SG_ CMPD_infoBuildType m10 : 8|8@1+ (1,0) [0|255] "" Vector__XXX
 SG_ CMPD_infoBuildConfigId m10 : 16|16@1+ (1,0) [0|65535] "" Vector__XXX
 SG_ CMPD_infoHardwareId m10 : 32|16@1+ (1,0) [0|65535] "" Vector__XXX
 SG_ CMPD_infoComponentId m10 : 48|16@1+ (1,0) [0|65535] "" Vector__XXX
 SG_ CMPD_infoPcbaId m11 : 16|8@1+ (1,0) [0|255] "" Vector__XXX
 SG_ CMPD_infoAssemblyId m11 : 24|8@1+ (1,0) [0|255] "" Vector__XXX
 SG_ CMPD_infoUsageId m11 : 32|16@1+ (1,0) [0|65535] "" Vector__XXX
 SG_ CMPD_infoSubUsageId m11 : 48|16@1+ (1,0) [0|65535] "" Vector__XXX

BO_ 680 CMPD_state: 8 CMPD
 SG_ CMPD_speedRPM : 0|11@1+ (10,0) [0|20000] "RPM" Vector__XXX
 SG_ CMPD_speedDuty : 11|10@1+ (0.1,0) [0|100] "%" Vector__XXX
 SG_ CMPD_inputHVPower : 21|11@1+ (10,0) [0|20000] "W" Vector__XXX
 SG_ CMPD_inputHVCurrent : 32|9@1+ (0.1,0) [0|50] "A" Vector__XXX
 SG_ CMPD_inputHVVoltage : 41|11@1+ (0.5,0) [0|1000] "V" Vector__XXX
 SG_ CMPD_2ShuntModeActive : 52|1@1+ (1,0) [0|1] "" Vector__XXX
 SG_ CMPD_powerLimitActive : 55|1@1+ (1,0) [0|1] "" Vector__XXX
 SG_ CMPD_state : 56|4@1+ (1,0) [0|15] "" Vector__XXX
 SG_ CMPD_wasteHeatState : 60|2@1+ (1,0) [0|3] "" Vector__XXX
 SG_ CMPD_powerLimitTooLowToStart : 62|1@1+ (1,0) [0|1] "" Vector__XXX
 SG_ CMPD_ready : 63|1@1+ (1,0) [0|1] "" Vector__XXX

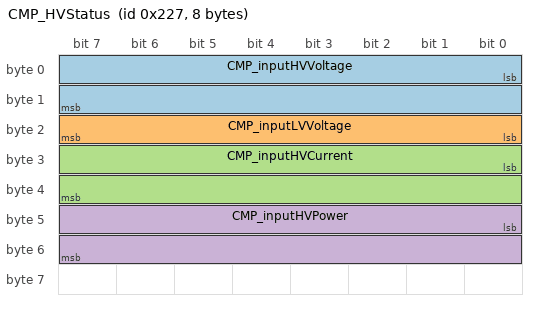
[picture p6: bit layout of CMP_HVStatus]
BO_ 551 CMP_HVStatus: 8 CMP
 SG_ CMP_inputHVVoltage : 0|16@1+ (0.1,0) [0|6553.4] "V" Vector__XXX
 SG_ CMP_inputLVVoltage : 16|8@1+ (0.1,0) [0|25.5] "V" Vector__XXX
 SG_ CMP_inputHVCurrent : 24|16@1+ (0.1,0) [0|6553.4] "A" Vector__XXX
 SG_ CMP_inputHVPower : 40|16@1+ (1,0) [0|65534] "W" Vector__XXX

BO_ 867 CMP_info: 8 CMP
 SG_ CMP_infoIndex M : 0|8@1+ (1,0) [0|255] "" Vector__XXX
 SG_ CMP_infoBuildType m10 : 8|8@1+ (1,0) [0|255] "" Vector__XXX
 SG_ CMP_infoBuildConfigId m10 : 16|16@1+ (1,0) [0|65535] "" Vector__XXX
 SG_ CMP_infoHardwareId m10 : 32|16@1+ (1,0) [0|65535] "" Vector__XXX
 SG_ CMP_infoComponentId m10 : 48|16@1+ (1,0) [0|65535] "" Vector__XXX
 SG_ CMP_infoPcbaId m11 : 16|8@1+ (1,0) [0|255] "" Vector__XXX
 SG_ CMP_infoAssemblyId m11 : 24|8@1+ (1,0) [0|255] "" Vector__XXX
 SG_ CMP_infoUsageId m11 : 32|16@1+ (1,0) [0|65535] "" Vector__XXX
 SG_ CMP_infoSubUsageId m11 : 48|16@1+ (1,0) [0|65535] "" Vector__XXX
 SG_ CMP_infoPlatformType m13 : 8|8@1+ (1,0) [0|255] "" Vector__XXX
 SG_ CMP_infoAppCrc m13 : 32|32@1+ (1,0) [0|4294967295] "" Vector__XXX
 SG_ CMP_infoBootUdsProtoVersion m20 : 8|8@1+ (1,0) [0|255] "" Vector__XXX
 SG_ CMP_infoBootCrc m20 : 32|32@1+ (1,0) [0|4294967295] "" Vector__XXX

BO_ 1767 CP_IsoTpPipeToPncd: 8 CP
 SG_ CP_isoTpToPncdData : 0|64@1+ (1,0) [0|1.84467440737e+19] "" Vector__XXX

CM_ BO_ 1025 "High-voltage battery management system message: brick measurements";
CM_ SG_ 1025 BMS_brickVoltageMultiplexer "High-voltage battery management system: brick voltage multiplexer";
CM_ SG_ 1025 BMS_brickVoltageCounter "High-voltage battery management system: brick voltage counter";
CM_ SG_ 1025 BMS_brickVoltageStatus1 "High-voltage battery management system: brick voltage status1";
CM_ SG_ 1025 BMS_brickVoltageStatus2 "High-voltage battery management system: brick voltage status2";
CM_ SG_ 1025 BMS_brickVoltageStatus3 "High-voltage battery management system: brick voltage status3";
CM_ SG_ 1025 BMS_brickVoltage1 "High-voltage battery management system: brick voltage1";
CM_ SG_ 1025 BMS_brickVoltage2 "High-voltage battery management system: brick voltage2";
CM_ SG_ 1025 BMS_brickVoltage3 "High-voltage battery management system: brick voltage3";
CM_ SG_ 1025 BMS_brickVoltageStatus4 "High-voltage battery management system: brick voltage status4";
CM_ SG_ 1025 BMS_brickVoltageStatus5 "High-voltage battery management system: brick voltage status5";
CM_ SG_ 1025 BMS_brickVoltageStatus6 "High-voltage battery management system: brick voltage status6";
CM_ SG_ 1025 BMS_brickVoltage4 "High-voltage battery management system: brick voltage4";
CM_ SG_ 1025 BMS_brickVoltage5 "High-voltage battery management system: brick voltage5";
CM_ SG_ 1025 BMS_brickVoltage6 "High-voltage battery management system: brick voltage6";
CM_ SG_ 1025 BMS_brickVoltageStatus7 "High-voltage battery management system: brick voltage status7";
CM_ SG_ 1025 BMS_brickVoltageStatus8 "High-voltage battery management system: brick voltage status8";
CM_ SG_ 1025 BMS_brickVoltageStatus9 "High-voltage battery management system: brick voltage status9";
CM_ SG_ 1025 BMS_brickVoltage7 "High-voltage battery management system: brick voltage7";
CM_ SG_ 1025 BMS_brickVoltage8 "High-voltage battery management system: brick voltage8";
CM_ SG_ 1025 BMS_brickVoltage9 "High-voltage battery management system: brick voltage9";
CM_ SG_ 1025 BMS_brickVoltageStatus10 "High-voltage battery management system: brick voltage status10";
CM_ SG_ 1025 BMS_brickVoltageStatus11 "High-voltage battery management system: brick voltage status11";
CM_ SG_ 1025 BMS_brickVoltageStatus12 "High-voltage battery management system: brick voltage status12";
CM_ SG_ 1025 BMS_brickVoltage10 "High-voltage battery management system: brick voltage10";
CM_ SG_ 1025 BMS_brickVoltage11 "High-voltage battery management system: brick voltage11";
CM_ SG_ 1025 BMS_brickVoltage12 "High-voltage battery management system: brick voltage12";
CM_ SG_ 1025 BMS_brickVoltageStatus13 "High-voltage battery management system: brick voltage status13";
CM_ SG_ 1025 BMS_brickVoltageStatus14 "High-voltage battery management system: brick voltage status14";
CM_ SG_ 1025 BMS_brickVoltageStatus15 "High-voltage battery management system: brick voltage status15";
CM_ SG_ 1025 BMS_brickVoltage13 "High-voltage battery management system: brick voltage13";
CM_ SG_ 1025 BMS_brickVoltage14 "High-voltage battery management system: brick voltage14";
CM_ SG_ 1025 BMS_brickVoltage15 "High-voltage battery management system: brick voltage15";
CM_ SG_ 1025 BMS_brickVoltageStatus16 "High-voltage battery management system: brick voltage status16";
CM_ SG_ 1025 BMS_brickVoltageStatus17 "High-voltage battery management system: brick voltage status17";
CM_ SG_ 1025 BMS_brickVoltageStatus18 "High-voltage battery management system: brick voltage status18";
CM_ SG_ 1025 BMS_brickVoltage16 "High-voltage battery management system: brick voltage16";
CM_ SG_ 1025 BMS_brickVoltage17 "High-voltage battery management system: brick voltage17";
CM_ SG_ 1025 BMS_brickVoltage18 "High-voltage battery management system: brick voltage18";
CM_ SG_ 1025 BMS_brickVoltageStatus19 "High-voltage battery management system: brick voltage status19";
CM_ SG_ 1025 BMS_brickVoltageStatus20 "High-voltage battery management system: brick voltage status20";
CM_ SG_ 1025 BMS_brickVoltageStatus21 "High-voltage battery management system: brick voltage status21";
CM_ SG_ 1025 BMS_brickVoltage19 "High-voltage battery management system: brick voltage19";
CM_ SG_ 1025 BMS_brickVoltage20 "High-voltage battery management system: brick voltage20";
CM_ SG_ 1025 BMS_brickVoltage21 "High-voltage battery management system: brick voltage21";
CM_ SG_ 1025 BMS_brickVoltageStatus22 "High-voltage battery management system: brick voltage status22";
CM_ SG_ 1025 BMS_brickVoltageStatus23 "High-voltage battery management system: brick voltage status23";
CM_ SG_ 1025 BMS_brickVoltageStatus24 "High-voltage battery management system: brick voltage status24";
CM_ SG_ 1025 BMS_brickVoltage22 "High-voltage battery management system: brick voltage22";
CM_ SG_ 1025 BMS_brickVoltage23 "High-voltage battery management system: brick voltage23";
CM_ SG_ 1025 BMS_brickVoltage24 "High-voltage battery management system: brick voltage24";
CM_ SG_ 1025 BMS_brickVoltageStatus25 "High-voltage battery management system: brick voltage status25";
CM_ SG_ 1025 BMS_brickVoltageStatus26 "High-voltage battery management system: brick voltage status26";
CM_ SG_ 1025 BMS_brickVoltageStatus27 "High-voltage battery management system: brick voltage status27";
CM_ SG_ 1025 BMS_brickVoltage25 "High-voltage battery management system: brick voltage25";
CM_ SG_ 1025 BMS_brickVoltage26 "High-voltage battery management system: brick voltage26";
CM_ SG_ 1025 BMS_brickVoltage27 "High-voltage battery management system: brick voltage27";
CM_ SG_ 1025 BMS_brickVoltageStatus28 "High-voltage battery management system: brick voltage status28";
CM_ SG_ 1025 BMS_brickVoltageStatus29 "High-voltage battery management system: brick voltage status29";
CM_ SG_ 1025 BMS_brickVoltageStatus30 "High-voltage battery management system: brick voltage status30";
CM_ SG_ 1025 BMS_brickVoltage28 "High-voltage battery management system: brick voltage28";
CM_ SG_ 1025 BMS_brickVoltage29 "High-voltage battery management system: brick voltage29";
CM_ SG_ 1025 BMS_brickVoltage30 "High-voltage battery management system: brick voltage30";
CM_ SG_ 1025 BMS_brickVoltageStatus31 "High-voltage battery management system: brick voltage status31";
CM_ SG_ 1025 BMS_brickVoltageStatus32 "High-voltage battery management system: brick voltage status32";
CM_ SG_ 1025 BMS_brickVoltageStatus33 "High-voltage battery management system: brick voltage status33";
CM_ SG_ 1025 BMS_brickVoltage31 "High-voltage battery management system: brick voltage31";
CM_ SG_ 1025 BMS_brickVoltage32 "High-voltage battery management system: brick voltage32";
CM_ SG_ 1025 BMS_brickVoltage33 "High-voltage battery management system: brick voltage33";
CM_ SG_ 1025 BMS_brickVoltageStatus34 "High-voltage battery management system: brick voltage status34";
CM_ SG_ 1025 BMS_brickVoltageStatus35 "High-voltage battery management system: brick voltage status35";
CM_ SG_ 1025 BMS_brickVoltageStatus36 "High-voltage battery management system: brick voltage status36";
CM_ SG_ 1025 BMS_brickVoltage34 "High-voltage battery management system: brick voltage34";
CM_ SG_ 1025 BMS_brickVoltage35 "High-voltage battery management system: brick voltage35";
CM_ SG_ 1025 BMS_brickVoltage36 "High-voltage battery management system: brick voltage36";
CM_ SG_ 1025 BMS_brickVoltageStatus37 "High-voltage battery management system: brick voltage status37";
CM_ SG_ 1025 BMS_brickVoltageStatus38 "High-voltage battery management system: brick voltage status38";
CM_ SG_ 1025 BMS_brickVoltageStatus39 "High-voltage battery management system: brick voltage status39";
CM_ SG_ 1025 BMS_brickVoltage37 "High-voltage battery management system: brick voltage37";
CM_ SG_ 1025 BMS_brickVoltage38 "High-voltage battery management system: brick voltage38";
CM_ SG_ 1025 BMS_brickVoltage39 "High-voltage battery management system: brick voltage39";
CM_ SG_ 1025 BMS_brickVoltageStatus40 "High-voltage battery management system: brick voltage status40";
CM_ SG_ 1025 BMS_brickVoltageStatus41 "High-voltage battery management system: brick voltage status41";
CM_ SG_ 1025 BMS_brickVoltageStatus42 "High-voltage battery management system: brick voltage status42";
CM_ SG_ 1025 BMS_brickVoltage40 "High-voltage battery management system: brick voltage40";
CM_ SG_ 1025 BMS_brickVoltage41 "High-voltage battery management system: brick voltage41";
CM_ SG_ 1025 BMS_brickVoltage42 "High-voltage battery management system: brick voltage42";
CM_ SG_ 1025 BMS_brickVoltageStatus43 "High-voltage battery management system: brick voltage status43";
CM_ SG_ 1025 BMS_brickVoltageStatus44 "High-voltage battery management system: brick voltage status44";
CM_ SG_ 1025 BMS_brickVoltageStatus45 "High-voltage battery management system: brick voltage status45";
CM_ SG_ 1025 BMS_brickVoltage43 "High-voltage battery management system: brick voltage43";
CM_ SG_ 1025 BMS_brickVoltage44 "High-voltage battery management system: brick voltage44";
CM_ SG_ 1025 BMS_brickVoltage45 "High-voltage battery management system: brick voltage45";
CM_ SG_ 1025 BMS_brickVoltageStatus46 "High-voltage battery management system: brick voltage status46";
CM_ SG_ 1025 BMS_brickVoltageStatus47 "High-voltage battery management system: brick voltage status47";
CM_ SG_ 1025 BMS_brickVoltageStatus48 "High-voltage battery management system: brick voltage status48";
CM_ SG_ 1025 BMS_brickVoltage46 "High-voltage battery management system: brick voltage46";
CM_ SG_ 1025 BMS_brickVoltage47 "High-voltage battery management system: brick voltage47";
CM_ SG_ 1025 BMS_brickVoltage48 "High-voltage battery management system: brick voltage48";
CM_ SG_ 1025 BMS_brickVoltageStatus49 "High-voltage battery management system: brick voltage status49";
CM_ SG_ 1025 BMS_brickVoltageStatus50 "High-voltage battery management system: brick voltage status50";
CM_ SG_ 1025 BMS_brickVoltageStatus51 "High-voltage battery management system: brick voltage status51";
CM_ SG_ 1025 BMS_brickVoltage49 "High-voltage battery management system: brick voltage49";
CM_ SG_ 1025 BMS_brickVoltage50 "High-voltage battery management system: brick voltage50";
CM_ SG_ 1025 BMS_brickVoltage51 "High-voltage battery management system: brick voltage51";
CM_ SG_ 1025 BMS_brickVoltageStatus52 "High-voltage battery management system: brick voltage status52";
CM_ SG_ 1025 BMS_brickVoltageStatus53 "High-voltage battery management system: brick voltage status53";
CM_ SG_ 1025 BMS_brickVoltageStatus54 "High-voltage battery management system: brick voltage status54";
CM_ SG_ 1025 BMS_brickVoltage52 "High-voltage battery management system: brick voltage52";
CM_ SG_ 1025 BMS_brickVoltage53 "High-voltage battery management system: brick voltage53";
CM_ SG_ 1025 BMS_brickVoltage54 "High-voltage battery management system: brick voltage54";
CM_ SG_ 1025 BMS_brickVoltageStatus55 "High-voltage battery management system: brick voltage status55";
CM_ SG_ 1025 BMS_brickVoltageStatus56 "High-voltage battery management system: brick voltage status56";
CM_ SG_ 1025 BMS_brickVoltageStatus57 "High-voltage battery management system: brick voltage status57";
CM_ SG_ 1025 BMS_brickVoltage55 "High-voltage battery management system: brick voltage55";
CM_ SG_ 1025 BMS_brickVoltage56 "High-voltage battery management system: brick voltage56";
CM_ SG_ 1025 BMS_brickVoltage57 "High-voltage battery management system: brick voltage57";
CM_ SG_ 1025 BMS_brickVoltageStatus58 "High-voltage battery management system: brick voltage status58";
CM_ SG_ 1025 BMS_brickVoltageStatus59 "High-voltage battery management system: brick voltage status59";
CM_ SG_ 1025 BMS_brickVoltageStatus60 "High-voltage battery management system: brick voltage status60";
CM_ SG_ 1025 BMS_brickVoltage58 "High-voltage battery management system: brick voltage58";
CM_ SG_ 1025 BMS_brickVoltage59 "High-voltage battery management system: brick voltage59";
CM_ SG_ 1025 BMS_brickVoltage60 "High-voltage battery management system: brick voltage60";
CM_ SG_ 1025 BMS_brickVoltageStatus61 "High-voltage battery management system: brick voltage status61";
CM_ SG_ 1025 BMS_brickVoltageStatus62 "High-voltage battery management system: brick voltage status62";
CM_ SG_ 1025 BMS_brickVoltageStatus63 "High-voltage battery management system: brick voltage status63";
CM_ SG_ 1025 BMS_brickVoltage61 "High-voltage battery management system: brick voltage61";
CM_ SG_ 1025 BMS_brickVoltage62 "High-voltage battery management system: brick voltage62";
CM_ SG_ 1025 BMS_brickVoltage63 "High-voltage battery management system: brick voltage63";
CM_ SG_ 1025 BMS_brickVoltageStatus64 "High-voltage battery management system: brick voltage status64";
CM_ SG_ 1025 BMS_brickVoltageStatus65 "High-voltage battery management system: brick voltage status65";
CM_ SG_ 1025 BMS_brickVoltageStatus66 "High-voltage battery management system: brick voltage status66";
CM_ SG_ 1025 BMS_brickVoltage64 "High-voltage battery management system: brick voltage64";
CM_ SG_ 1025 BMS_brickVoltage65 "High-voltage battery management system: brick voltage65";
CM_ SG_ 1025 BMS_brickVoltage66 "High-voltage battery management system: brick voltage66";
CM_ SG_ 1025 BMS_brickVoltageStatus67 "High-voltage battery management system: brick voltage status67";
CM_ SG_ 1025 BMS_brickVoltageStatus68 "High-voltage battery management system: brick voltage status68";
CM_ SG_ 1025 BMS_brickVoltageStatus69 "High-voltage battery management system: brick voltage status69";
CM_ SG_ 1025 BMS_brickVoltage67 "High-voltage battery management system: brick voltage67";
CM_ SG_ 1025 BMS_brickVoltage68 "High-voltage battery management system: brick voltage68";
CM_ SG_ 1025 BMS_brickVoltage69 "High-voltage battery management system: brick voltage69";
CM_ SG_ 1025 BMS_brickVoltageStatus70 "High-voltage battery management system: brick voltage status70";
CM_ SG_ 1025 BMS_brickVoltageStatus71 "High-voltage battery management system: brick voltage status71";
CM_ SG_ 1025 BMS_brickVoltageStatus72 "High-voltage battery management system: brick voltage status72";
CM_ SG_ 1025 BMS_brickVoltage70 "High-voltage battery management system: brick voltage70";
CM_ SG_ 1025 BMS_brickVoltage71 "High-voltage battery management system: brick voltage71";
CM_ SG_ 1025 BMS_brickVoltage72 "High-voltage battery management system: brick voltage72";
CM_ SG_ 1025 BMS_brickVoltageStatus73 "High-voltage battery management system: brick voltage status73";
CM_ SG_ 1025 BMS_brickVoltageStatus74 "High-voltage battery management system: brick voltage status74";
CM_ SG_ 1025 BMS_brickVoltageStatus75 "High-voltage battery management system: brick voltage status75";
CM_ SG_ 1025 BMS_brickVoltage73 "High-voltage battery management system: brick voltage73";
CM_ SG_ 1025 BMS_brickVoltage74 "High-voltage battery management system: brick voltage74";
CM_ SG_ 1025 BMS_brickVoltage75 "High-voltage battery management system: brick voltage75";
CM_ SG_ 1025 BMS_brickVoltageStatus76 "High-voltage battery management system: brick voltage status76";
CM_ SG_ 1025 BMS_brickVoltageStatus77 "High-voltage battery management system: brick voltage status77";
CM_ SG_ 1025 BMS_brickVoltageStatus78 "High-voltage battery management system: brick voltage status78";
CM_ SG_ 1025 BMS_brickVoltage76 "High-voltage battery management system: brick voltage76";
CM_ SG_ 1025 BMS_brickVoltage77 "High-voltage battery management system: brick voltage77";
CM_ SG_ 1025 BMS_brickVoltage78 "High-voltage battery management system: brick voltage78";
CM_ SG_ 1025 BMS_brickVoltageStatus79 "High-voltage battery management system: brick voltage status79";
CM_ SG_ 1025 BMS_brickVoltageStatus80 "High-voltage battery management system: brick voltage status80";
CM_ SG_ 1025 BMS_brickVoltageStatus81 "High-voltage battery management system: brick voltage status81";
CM_ SG_ 1025 BMS_brickVoltage79 "High-voltage battery management system: brick voltage79";
CM_ SG_ 1025 BMS_brickVoltage80 "High-voltage battery management system: brick voltage80";
CM_ SG_ 1025 BMS_brickVoltage81 "High-voltage battery management system: brick voltage81";
CM_ SG_ 1025 BMS_brickVoltageStatus82 "High-voltage battery management system: brick voltage status82";
CM_ SG_ 1025 BMS_brickVoltageStatus83 "High-voltage battery management system: brick voltage status83";
CM_ SG_ 1025 BMS_brickVoltageStatus84 "High-voltage battery management system: brick voltage status84";
CM_ SG_ 1025 BMS_brickVoltage82 "High-voltage battery management system: brick voltage82";
CM_ SG_ 1025 BMS_brickVoltage83 "High-voltage battery management system: brick voltage83";
CM_ SG_ 1025 BMS_brickVoltage84 "High-voltage battery management system: brick voltage84";
CM_ SG_ 1025 BMS_brickVoltageStatus85 "High-voltage battery management system: brick voltage status85";
CM_ SG_ 1025 BMS_brickVoltageStatus86 "High-voltage battery management system: brick voltage status86";
CM_ SG_ 1025 BMS_brickVoltageStatus87 "High-voltage battery management system: brick voltage status87";
CM_ SG_ 1025 BMS_brickVoltage85 "High-voltage battery management system: brick voltage85";
CM_ SG_ 1025 BMS_brickVoltage86 "High-voltage battery management system: brick voltage86";
CM_ SG_ 1025 BMS_brickVoltage87 "High-voltage battery management system: brick voltage87";
CM_ SG_ 1025 BMS_brickVoltageStatus88 "High-voltage battery management system: brick voltage status88";
CM_ SG_ 1025 BMS_brickVoltageStatus89 "High-voltage battery management system: brick voltage status89";
CM_ SG_ 1025 BMS_brickVoltageStatus90 "High-voltage battery management system: brick voltage status90";
CM_ SG_ 1025 BMS_brickVoltage88 "High-voltage battery management system: brick voltage88";
CM_ SG_ 1025 BMS_brickVoltage89 "High-voltage battery management system: brick voltage89";
CM_ SG_ 1025 BMS_brickVoltage90 "High-voltage battery management system: brick voltage90";
CM_ SG_ 1025 BMS_brickVoltageStatus91 "High-voltage battery management system: brick voltage status91";
CM_ SG_ 1025 BMS_brickVoltageStatus92 "High-voltage battery management system: brick voltage status92";
CM_ SG_ 1025 BMS_brickVoltageStatus93 "High-voltage battery management system: brick voltage status93";
CM_ SG_ 1025 BMS_brickVoltage91 "High-voltage battery management system: brick voltage91";
CM_ SG_ 1025 BMS_brickVoltage92 "High-voltage battery management system: brick voltage92";
CM_ SG_ 1025 BMS_brickVoltage93 "High-voltage battery management system: brick voltage93";
CM_ SG_ 1025 BMS_brickVoltageStatus94 "High-voltage battery management system: brick voltage status94";
CM_ SG_ 1025 BMS_brickVoltageStatus95 "High-voltage battery management system: brick voltage status95";
CM_ SG_ 1025 BMS_brickVoltageStatus96 "High-voltage battery management system: brick voltage status96";
CM_ SG_ 1025 BMS_brickVoltage94 "High-voltage battery management system: brick voltage94";
CM_ SG_ 1025 BMS_brickVoltage95 "High-voltage battery management system: brick voltage95";
CM_ SG_ 1025 BMS_brickVoltage96 "High-voltage battery management system: brick voltage96";
CM_ SG_ 1025 BMS_brickVoltageStatus97 "High-voltage battery management system: brick voltage status97";
CM_ SG_ 1025 BMS_brickVoltageStatus98 "High-voltage battery management system: brick voltage status98";
CM_ SG_ 1025 BMS_brickVoltageStatus99 "High-voltage battery management system: brick voltage status99";
CM_ SG_ 1025 BMS_brickVoltage97 "High-voltage battery management system: brick voltage97";
CM_ SG_ 1025 BMS_brickVoltage98 "High-voltage battery management system: brick voltage98";
CM_ SG_ 1025 BMS_brickVoltage99 "High-voltage battery management system: brick voltage99";
CM_ SG_ 1025 BMS_brickVoltageStatus100 "High-voltage battery management system: brick voltage status100";
CM_ SG_ 1025 BMS_brickVoltageStatus101 "High-voltage battery management system: brick voltage status101";
CM_ SG_ 1025 BMS_brickVoltageStatus102 "High-voltage battery management system: brick voltage status102";
CM_ SG_ 1025 BMS_brickVoltage100 "High-voltage battery management system: brick voltage100";
CM_ SG_ 1025 BMS_brickVoltage101 "High-voltage battery management system: brick voltage101";
CM_ SG_ 1025 BMS_brickVoltage102 "High-voltage battery management system: brick voltage102";
CM_ SG_ 1025 BMS_brickVoltageStatus103 "High-voltage battery management system: brick voltage status103";
CM_ SG_ 1025 BMS_brickVoltageStatus104 "High-voltage battery management system: brick voltage status104";
CM_ SG_ 1025 BMS_brickVoltageStatus105 "High-voltage battery management system: brick voltage status105";
CM_ SG_ 1025 BMS_brickVoltage103 "High-voltage battery management system: brick voltage103";
CM_ SG_ 1025 BMS_brickVoltage104 "High-voltage battery management system: brick voltage104";
CM_ SG_ 1025 BMS_brickVoltage105 "High-voltage battery management system: brick voltage105";
CM_ SG_ 1025 BMS_brickVoltageStatus106 "High-voltage battery management system: brick voltage status106";
CM_ SG_ 1025 BMS_brickVoltageStatus107 "High-voltage battery management system: brick voltage status107";
CM_ SG_ 1025 BMS_brickVoltageStatus108 "High-voltage battery management system: brick voltage status108";
CM_ SG_ 1025 BMS_brickVoltage106 "High-voltage battery management system: brick voltage106";
CM_ SG_ 1025 BMS_brickVoltage107 "High-voltage battery management system: brick voltage107";
CM_ SG_ 1025 BMS_brickVoltage108 "High-voltage battery management system: brick voltage108";
CM_ BO_ 1138 "High-voltage battery management system message: charge info";
CM_ SG_ 1138 BMS_acChargePowerSample "High-voltage battery management system: ac charge power sample";
CM_ SG_ 1138 BMS_voltageRegCurrentTarget "DC current target based on voltage regulator";
CM_ SG_ 1138 BMS_vehicleChargeDcCurrentLimit "Charge current target after all aggregating all vehicle-side limits, exclude EVSE limits";
CM_ SG_ 1138 BMS_userChargeCurrentLimitMode "BMS' user-facing reason for charge being either limited or not limited";
CM_ SG_ 1138 BMS_chargeCurrentLimitMode "BMS charging current limiting factor";
CM_ SG_ 1138 BMS_timeToFinishHeatForCharge "High-voltage battery management system: time to finish heat for charge";
CM_ SG_ 1138 BMS_timeToTripPlanChargingTarget "High-voltage battery management system: time to trip plan charging target";
CM_ SG_ 1138 BMS_useChargeTimeEstimate "High-voltage battery management system: use charge time estimate";
CM_ BO_ 722 "High-voltage battery management system message: drive limits";
CM_ SG_ 722 BMS_minBusVoltage "Calculated min bus voltage limit";
CM_ SG_ 722 BMS_maxBusVoltage "Calculated max bus voltage limit for the pack";
CM_ SG_ 722 BMS_maxChargeCurrent "Calculated max charge current limit for the pack";
CM_ SG_ 722 BMS_maxDischargeCurrent "Calculated max discharge current limit for the pack";
CM_ BO_ 690 "High-voltage battery management system message: energy status";
CM_ SG_ 690 BMS_energyStatusMultiplexer "High-voltage battery management system: energy status multiplexer";
CM_ SG_ 690 BMS_nominalFullPackEnergy "Full pack energy based on calculated pack energy from the full pack discharge energy walk";
CM_ SG_ 690 BMS_nominalEnergyRemaining "Nominal energy remaining based on calculated pack energy from the nominal discharge energy walk";
CM_ SG_ 690 BMS_idealEnergyRemaining "Ideal energy remaining based on calculated pack energy from ideal discharge energy walk";
CM_ SG_ 690 BMS_fullChargeComplete "Indicates BMS is fully charged";
CM_ SG_ 690 BMS_energyBuffer "Rough indication of confidence in the energy estimation";
CM_ SG_ 690 BMS_expectedEnergyRemaining "High-voltage battery management system: expected energy remaining";
CM_ SG_ 690 BMS_energyToChargeComplete "Calculated energy required to reach charge complete";
CM_ SG_ 690 BMS_energyRemainingDisplay "Rubber-banding energy remaining to be used for the UI facing miles remaining display";
CM_ SG_ 690 BMS_energyRemainingTDisplay "Rubber-banding energy remaining to be used for the UI facing miles remaining display";
CM_ SG_ 690 BMS_energyDisplayErrorBlendRate "Rubber-banding blend rate to be used to ensure consistency between the gauge display and UI energy algorithms";
CM_ SG_ 690 BMS_userFacingSoe "User facing state of energy";
CM_ BO_ 306 "High-voltage battery management system message: hv bus status";
CM_ SG_ 306 BMS_dcLinkVoltage "High-voltage battery management system: dc link voltage";
CM_ SG_ 306 BMS_packCurrent "Current measured at the HV contactors of the HV battery.";
CM_ SG_ 306 BMS_currentUnfiltered "Pack current with no filters applied";
CM_ BO_ 768 "High-voltage battery management system message: info";
CM_ SG_ 768 BMS_infoIndex "High-voltage battery management system: info index";
CM_ SG_ 768 BMS_buildType "High-voltage battery management system: build type";
CM_ SG_ 768 BMS_buildConfigId "High-voltage battery management system: build config id";
CM_ SG_ 768 BMS_hardwareId "High-voltage battery management system: hardware id";
CM_ SG_ 768 BMS_componentId "High-voltage battery management system: component id";
CM_ SG_ 768 BMS_pcbaId "BMS' assigned PCBA ID";
CM_ SG_ 768 BMS_assemblyId "BMS' assigned assembly ID";
CM_ SG_ 768 BMS_usageId "BMS' assigned usage ID";
CM_ SG_ 768 BMS_subUsageId "BMS' assigned subusage ID";
CM_ SG_ 768 BMS_platformType "High-voltage battery management system: platform type";
CM_ SG_ 768 BMS_appCrc "High-voltage battery management system: app crc";
CM_ SG_ 768 BMS_appGitHash "High-voltage battery management system: app git hash";
CM_ SG_ 768 BMS_bootGitHash "High-voltage battery management system: boot git hash";
CM_ SG_ 768 BMS_bootUdsProtoVersion "High-voltage battery management system: boot uds proto version";
CM_ SG_ 768 BMS_bootCrc "High-voltage battery management system: boot crc";
CM_ BO_ 978 "High-voltage battery management system message: kwh counter";
CM_ SG_ 978 BMS_kwhDischargeTotal "Total energy-lost kWh count during discharging";
CM_ SG_ 978 BMS_kwhChargeTotal "Total energy-gained kWh count during charging";
CM_ BO_ 1010 "High-voltage battery management system message: kwh counters multiplexed";
CM_ SG_ 1010 BMS_kwhCounter_Id "High-voltage battery management system: kwh counter id";
CM_ SG_ 1010 BMS_acChargerKwhTotal "Total energy-gained kWh count during AC charge";
CM_ SG_ 1010 BMS_dcChargerKwhTotal "Total energy-gained kWh count during DC charging";
CM_ SG_ 1010 BMS_kwhRegenChargeTotal "Total energy-gained kWh count during charging with regen";
CM_ SG_ 1010 BMS_kwhDriveDischargeTotal "Total energy-lost kWh count during discharging while driving";
CM_ SG_ 1010 BMS_kwhDischargeTotalModule1 "Total energy-lost kWh count during discharging for module number (1 indexed)";
CM_ SG_ 1010 BMS_kwhChargeTotalModule1 "Total energy-gained kWh count for module number (1 indexed)";
CM_ SG_ 1010 BMS_kwhAcChargeTotalModule1 "Total energy-gained kWh count during AC charge for module number (1 indexed)";
CM_ SG_ 1010 BMS_kwhDcChargeTotalModule1 "Total energy-gained kWh count during DC charge for module number (1 indexed)";
CM_ SG_ 1010 BMS_kwhDischargeTotalModule2 "Total energy-lost kWh count during discharging for module number (1 indexed)";
CM_ SG_ 1010 BMS_kwhChargeTotalModule2 "Total energy-gained kWh count for module number (1 indexed)";
CM_ SG_ 1010 BMS_kwhAcChargeTotalModule2 "Total energy-gained kWh count during AC charge for module number (1 indexed)";
CM_ SG_ 1010 BMS_kwhDcChargeTotalModule2 "Total energy-gained kWh count during DC charge for module number (1 indexed)";
CM_ SG_ 1010 BMS_kwhDischargeTotalModule3 "Total energy-lost kWh count during discharging for module number (1 indexed)";
CM_ SG_ 1010 BMS_kwhChargeTotalModule3 "Total energy-gained kWh count for module number (1 indexed)";
CM_ SG_ 1010 BMS_kwhAcChargeTotalModule3 "Total energy-gained kWh count during AC charge for module number (1 indexed)";
CM_ SG_ 1010 BMS_kwhDcChargeTotalModule3 "Total energy-gained kWh count during DC charge for module number (1 indexed)";
CM_ SG_ 1010 BMS_kwhDischargeTotalModule4 "Total energy-lost kWh count during discharging for module number (1 indexed)";
CM_ SG_ 1010 BMS_kwhChargeTotalModule4 "Total energy-gained kWh count for module number (1 indexed)";
CM_ SG_ 1010 BMS_kwhAcChargeTotalModule4 "Total energy-gained kWh count during AC charge for module number (1 indexed)";
CM_ SG_ 1010 BMS_kwhDcChargeTotalModule4 "Total energy-gained kWh count during DC charge for module number (1 indexed)";
CM_ BO_ 884 "High-voltage battery management system message: log1";
CM_ SG_ 884 BMS_log1MuxId "High-voltage battery management system: log1 mux id";
CM_ SG_ 884 BMS_powerTransferStatus "Reports the Battery Management System (BMS) power transfer interface state.";
CM_ SG_ 884 BMS_extDcPrechargeVoltageLimit "High-voltage battery management system: ext dc precharge voltage limit";
CM_ SG_ 884 BMS_dcChargeCurrentRequest "The BMS's instantaneous DC charge current request to the EVSE";
CM_ SG_ 884 BMS_dcChargeCurrentLimit "The vehicle's charge current limit on a DC EVSE's output";
CM_ SG_ 884 BMS_dcDischargeEnabled "High-voltage battery management system: dc discharge enabled";
CM_ SG_ 884 BMS_rippleChargeRetryCount "High-voltage battery management system: ripple charge retry count";
CM_ SG_ 884 BMS_dcChargeVoltageLimit "The vehicle's charge voltage limit on a DC EVSE's output";
CM_ SG_ 884 BMS_dcChargePowerLimit "Max power limit for pack during DC charging";
CM_ SG_ 884 BMS_acRealPowerRequest "Reports the instantaneous real AC power command during active power transfer.";
CM_ SG_ 884 BMS_maxExtIsoFcLinkV "The max voltage read on the FC link during the external isolation check";
CM_ SG_ 884 BMS_energyMaxPredictedBrickTemp "High-voltage battery management system: energy max predicted brick temp";
CM_ SG_ 884 BMS_energyTempGradientAtMaxTemp "High-voltage battery management system: energy temp gradient at max temp";
CM_ SG_ 884 BMS_energyWalkMaxSoc "High-voltage battery management system: energy walk max soc";
CM_ SG_ 884 BMS_energyWalkMinSoc "High-voltage battery management system: energy walk min soc";
CM_ SG_ 884 BMS_chargeEnergyWalkState "High-voltage battery management system: charge energy walk state";
CM_ SG_ 884 BMS_packVoltage "Measures voltage on the battery side of the High Voltage (HV) contactors.";
CM_ SG_ 884 BMS_energyWalkMaxPackCurrent "High-voltage battery management system: energy walk max pack current";
CM_ SG_ 884 BMS_energyWalkMaxVehiclePower "High-voltage battery management system: energy walk max vehicle power";
CM_ SG_ 884 BMS_battTempPct "High-voltage battery management system: batt temp pct";
CM_ SG_ 884 BMS_powerTransferDisableType "High-voltage battery management system: power transfer disable type";
CM_ SG_ 884 BMS_powerTransferDisableReason "High-voltage battery management system: power transfer disable reason";
CM_ SG_ 884 BMS_powerTransferWaitCondition "High-voltage battery management system: power transfer wait condition";
CM_ SG_ 884 BMS_dischargeRetryCount "High-voltage battery management system: discharge retry count";
CM_ SG_ 884 BMS_acChargeDesired "High-voltage battery management system: ac charge desired";
CM_ SG_ 884 BMS_tetheringDesired "High-voltage battery management system: tethering desired";
CM_ SG_ 884 BMS_gridFormDesired "High-voltage battery management system: grid form desired";
CM_ SG_ 884 BMS_gridFollowDesired "High-voltage battery management system: grid follow desired";
CM_ BO_ 946 "High-voltage battery management system message: log2";
CM_ SG_ 946 BMS_log2MuxId "High-voltage battery management system: log2 mux id";
CM_ SG_ 946 BMS_maxChargeRestartNeededByVolt "High-voltage battery management system: max charge restart needed by voltage";
CM_ SG_ 946 BMS_cacAvg "BMS Calculated Ah Capacity (CAC). This is the average of all the brick CACs";
CM_ SG_ 946 BMS_maxChargeNearComplete "High-voltage battery management system: max charge near complete";
CM_ SG_ 946 BMS_cacMin "BMS Calculated Ah Capacity (CAC). This is the min of all the brick CACs";
CM_ SG_ 946 BMS_cacMinBrickId "High-voltage battery management system: cac min brick id";
CM_ SG_ 946 BMS_cacMax "BMS Calculated Ah Capacity (CAC). This is the max of all the brick CACs";
CM_ SG_ 946 BMS_cacMaxBrickId "High-voltage battery management system: cac max brick id";
CM_ SG_ 946 BMS_acRippleConfigNvramValid "High-voltage battery management system: ac ripple config nvram valid";
CM_ SG_ 946 BMS_hvChain_useLeakyBucket "Is the leaky bucket being used - an indicator of the HV Chain Model health";
CM_ SG_ 946 BMS_hvChain_iLimit "High-voltage battery management system: hv chain i limit";
CM_ SG_ 946 BMS_hvChain_limitingState "High-voltage battery management system: hv chain limiting state";
CM_ SG_ 946 BMS_hvChain_limitingStateTempera "High-voltage battery management system: hv chain limiting state temperature";
CM_ SG_ 946 BMS_acRippleIsSupported "High-voltage battery management system: ac ripple is supported";
CM_ SG_ 946 BMS_acRippleStartTemperatureMax "High-voltage battery management system: ac ripple start temperature max";
CM_ SG_ 946 BMS_acRippleStartTemperatureMin "High-voltage battery management system: ac ripple start temperature min";
CM_ SG_ 946 BMS_fcLinkTestDecayTime "High-voltage battery management system: fc link test decay time";
CM_ SG_ 946 BMS_fcLinkTestTimeSinceLastRun "High-voltage battery management system: fc link test time since last run";
CM_ SG_ 946 BMS_pcsPrechargeRequest "Enum indicating the active precharge request type from BMS to PCS";
CM_ SG_ 946 BMS_pcsPrechargeTargetVoltage "Target voltage for precharging HV bus";
CM_ SG_ 946 BMS_recentOvUvAlert "At least one of the Brick OV or UV alerts has been active recently; consumed by BMS_a049_SW_Thermal_Event set condition";
CM_ SG_ 946 BMS_recentIsoAlert "At least one of the isolation alerts has been active recently; consumed by BMS_a049_SW_Thermal_Event set condition";
CM_ SG_ 946 BMS_recentBmbMiaAlert "At least one of the BMB communication alerts has been active recently; consumed by BMS_a049_SW_Thermal_Event set condition";
CM_ SG_ 946 BMS_cacBlendingConfigNvramValid "High-voltage battery management system: cac blending config nvram valid";
CM_ SG_ 946 BMS_cacBlendingEnabled "High-voltage battery management system: cac blending enabled";
CM_ SG_ 946 BMS_cacBlendPercentPerCycle "High-voltage battery management system: cac blend percent per cycle";
CM_ SG_ 946 BMS_energyVariableChgRequested "High-voltage battery management system: energy variable chg requested";
CM_ SG_ 946 BMS_packRestTime "Minimum resting time of all bricks";
CM_ SG_ 946 BMS_idealEnergyFloor "Ideal energy estimate based on the min bounded SOC that accounts for accumulated shunt error";
CM_ SG_ 946 BMS_thmGradientSlopeCondition "High-voltage battery management system: thm gradient slope condition";
CM_ SG_ 946 BMS_recentSlopeConditon "High-voltage battery management system: recent slope conditon";
CM_ SG_ 946 BMS_dynamicEnergyBuffer "BMS estimate of energy error based on SOC measurement inaccuracy";
CM_ SG_ 946 BMS_temperatureCondition "High-voltage battery management system: temperature condition";
CM_ SG_ 946 BMS_thmGradientSlope "High-voltage battery management system: thm gradient slope";
CM_ SG_ 946 BMS_thmGradient "High-voltage battery management system: thm gradient";
CM_ SG_ 946 BMS_tempVsSocTotalChgEnergy "High-voltage battery management system: temp vs soc total chg energy";
CM_ SG_ 946 BMS_powerVsVoltageTotalChgEnergy "High-voltage battery management system: power vs voltage total chg energy";
CM_ SG_ 946 BMS_lifeModelOutputsAreTrustwort "High-voltage battery management system: life model outputs are trustworthy";
CM_ SG_ 946 BMS_dSocNormalizedMin "High-voltage battery management system: d soc normalized min";
CM_ SG_ 946 BMS_dSocNormalizedFiltMin "High-voltage battery management system: d soc normalized filt min";
CM_ SG_ 946 BMS_dSocMinAlpha "minimum calculated alpha value across all bricks and all dSOC calculations";
CM_ SG_ 946 BMS_dSocMaxLowAlphaCounter "High-voltage battery management system: d soc max low alpha counter";
CM_ SG_ 946 BMS_dSocMinAlphaBrickID "High-voltage battery management system: d soc min alpha brick ID";
CM_ SG_ 946 BMS_dSocCacMargin "High-voltage battery management system: d soc cac margin";
CM_ SG_ 946 BMS_lifeModelNoCurrentStorageCap "High-voltage battery management system: life model no current storage capacity loss";
CM_ SG_ 946 BMS_lifeModelShortDcr "High-voltage battery management system: life model short dcr";
CM_ SG_ 946 BMS_lifeModelLongDcr "High-voltage battery management system: life model long dcr";
CM_ SG_ 946 BMS_lifeModelStorageCapacityLoss "High-voltage battery management system: life model storage capacity loss";
CM_ SG_ 946 BMS_lifeModelThroughputCapacityL "High-voltage battery management system: life model throughput capacity loss";
CM_ SG_ 946 BMS_passiveCoolCellTargetT "High-voltage battery management system: passive cool cell target t";
CM_ SG_ 946 BMS_lifeModelAvgTempSeverity "High-voltage battery management system: life model avg temp severity";
CM_ SG_ 946 BMS_lifeModelDepthOfDischargeSev "High-voltage battery management system: life model depth of discharge severity";
CM_ SG_ 946 BMS_lifeModelHistogramCapacityLo "High-voltage battery management system: life model histogram capacity loss";
CM_ SG_ 946 BMS_lifeModelHistogramBrickCapac "High-voltage battery management system: life model histogram brick capacity";
CM_ SG_ 946 BMS_lifeModelDcrGrowthPercent "High-voltage battery management system: life model dcr growth percent";
CM_ SG_ 946 BMS_nominalFullPackEnergyRaw "Non-latched version of BMS_nominalEnergyRemaining";
CM_ SG_ 946 BMS_nominalEnergyRemainingBuffer "Buffered version of BMS_nominalEnergyRemaining";
CM_ SG_ 946 BMS_idealEnergyRemainingBuffered "Buffered version of BMS_idealEnergyRemaining";
CM_ SG_ 946 BMS_largestSynchronizedCacErrorP "High-voltage battery management system: largest synchronized cac error pct";
CM_ SG_ 946 BMS_largestCacSpreadErrorLower "High-voltage battery management system: largest cac spread error lower";
CM_ SG_ 946 BMS_lifeModelAverageCac "High-voltage battery management system: life model average cac";
CM_ SG_ 946 BMS_lifeModelCacBrick1 "High-voltage battery management system: life model cac brick1";
CM_ SG_ 946 BMS_lifeModelAverageOffset "High-voltage battery management system: life model average offset";
CM_ SG_ 946 BMS_percentCacUpdatesInTimeWindo "High-voltage battery management system: percent cac updates in time window";
CM_ SG_ 946 BMS_lifeModelMaxCacBrickId "High-voltage battery management system: life model max cac brick id";
CM_ SG_ 946 BMS_lifeModelMaxCac "High-voltage battery management system: life model max cac";
CM_ SG_ 946 BMS_lifeModelMinCacBrickId "High-voltage battery management system: life model min cac brick id";
CM_ SG_ 946 BMS_lifeModelMinCac "High-voltage battery management system: life model min cac";
CM_ SG_ 946 BMS_restingPointCacAvg "High-voltage battery management system: resting point cac avg";
CM_ SG_ 946 BMS_cacEstimationSource "High-voltage battery management system: cac estimation source";
CM_ SG_ 946 BMS_synchronizedCacMaxRaw "High-voltage battery management system: synchronized cac max raw";
CM_ SG_ 946 BMS_synchronizedCacMinRaw "High-voltage battery management system: synchronized cac min raw";
CM_ SG_ 946 BMS_largestSyncCacErrorStartSoc "Start SOC for CAC update from the brick with the highest synchronized CAC error";
CM_ SG_ 946 BMS_largestSyncCacErrorEndSoc "Start SOC for CAC update from the brick with the highest synchronized CAC error";
CM_ SG_ 946 BMS_runtimeSocConfigNvramValid "High-voltage battery management system: runtime soc config nvram valid";
CM_ SG_ 946 BMS_runtimeSocCorrectionsEnabled "High-voltage battery management system: runtime soc corrections enabled";
CM_ SG_ 946 BMS_rubberBandingEnabled "Reports whether rubber banding of output energy corrections is enabled.";
CM_ SG_ 946 BMS_rubberBandingConfigNvramVali "High-voltage battery management system: rubber banding config nvram valid";
CM_ SG_ 946 BMS_runtimeSocMinTempForModel "High-voltage battery management system: runtime soc min temp for model";
CM_ SG_ 946 BMS_energyBufferConfigNvramValid "High-voltage battery management system: energy buffer config nvram valid";
CM_ SG_ 946 BMS_thermalEvent1pDetectConfigDi "High-voltage battery management system: thermal event1p detect config disabled";
CM_ SG_ 946 BMS_sohEnergy "Battery SOH energy estimate. If calibrated SOH capacity is unavailable, this value is a filtered result from brick CACs.";
CM_ SG_ 946 BMS_fullCapacitySohEnergy "Energy estimate using nominal brick capacity at maximum SOC using SOH retention test conditions";
CM_ SG_ 946 BMS_calibratedCapacitySohEnergy "Energy estimate using CAC from the most recent valid SOH test at maximum SOC using SOH retention test conditions";
CM_ SG_ 946 BMS_estimatedCapacitySohEnergy "Energy estimate using filtered brick capacities at maximum SOC using SOH retention test conditions";
CM_ SG_ 946 BMS_prevUserFacingSohEnergy "The last soh energy stored in NVM for rate limiting purposes";
CM_ SG_ 946 BMS_stateOfHealthMinCac "Reports the minimum Calculated Amp-hour Capacity (CAC) by aged Open Circuit Voltage (OCV) raw values across bricks that could be used in State of Health (SOH) calculations.";
CM_ SG_ 946 BMS_lifeModelStorageLossPackAge "High-voltage battery management system: life model storage loss pack age";
CM_ SG_ 946 BMS_lifeModelThroughputDcrCycleC "High-voltage battery management system: life model throughput dcr cycle count";
CM_ SG_ 946 BMS_stateOfHealthMinCacLowerBoun "Reports the minimum Calculated Amp-hour Capacity (CAC) by aged Open Circuit Voltage (OCV) raw lower bound values across bricks that could be used in State of Health (SOH) calculations.";
CM_ SG_ 946 BMS_energyWalkCounter "High-voltage battery management system: energy walk counter";
CM_ SG_ 946 BMS_energyWalkTimeoutCounter "High-voltage battery management system: energy walk timeout counter";
CM_ SG_ 946 BMS_dynamicCcvEnabled "High-voltage battery management system: dynamic ccv enabled";
CM_ SG_ 946 BMS_chargeTargetLookupSoc "High-voltage battery management system: charge target lookup soc";
CM_ SG_ 946 BMS_stateOfHealth "Most recent battery capacity estimate, from a successful SOH test in %";
CM_ SG_ 946 BMS_avgShuntAsicCurrentOffset "High-voltage battery management system: avg shunt asic current offset";
CM_ SG_ 946 BMS_cellAttributesGeneralAttribu "High-voltage battery management system: cell attributes general attributes";
CM_ SG_ 946 BMS_cellAttributesPackManufactur "High-voltage battery management system: cell attributes pack manufacturing location";
CM_ SG_ 946 BMS_cellAttributesRemanufactured "High-voltage battery management system: cell attributes remanufactured pack";
CM_ SG_ 946 BMS_cellAttributesConfigNvramVal "High-voltage battery management system: cell attributes config nvram valid";
CM_ SG_ 946 BMS_cellAttributesCellType "High-voltage battery management system: cell attributes cell type";
CM_ SG_ 946 BMS_cellAttributesAutocloseAndSc "High-voltage battery management system: cell attributes autoclose and scrap pack on field return";
CM_ SG_ 946 BMS_cellAttributesShipPackForFai "High-voltage battery management system: cell attributes ship pack for failure analysis";
CM_ SG_ 946 BMS_lifeModelThroughputCycleCoun "High-voltage battery management system: life model throughput cycle count";
CM_ SG_ 946 BMS_limpChargeCurrentLimit "DC current limit based on limp mode";
CM_ SG_ 946 BMS_energyRemainingDisplayError "High-voltage battery management system: energy remaining display error";
CM_ SG_ 946 BMS_energyRemainingTDisplayError "High-voltage battery management system: energy remaining t display error";
CM_ SG_ 946 BMS_numOfThermistors "Measures the number of thermistors in the battery pack for temperature monitoring.";
CM_ SG_ 946 BMS_numOfBricks "Measures the number of battery bricks (modules or cell groups) in the pack.";
CM_ SG_ 946 BMS_cellChargeDcCurrentLimit "DC current target based on cell voltage & temp tables";
CM_ SG_ 946 BMS_socByDeltaVEnabled "High-voltage battery management system: soc by delta v enabled";
CM_ SG_ 946 BMS_socByDvMaxSocLimit "High-voltage battery management system: soc by dv max soc limit";
CM_ SG_ 946 BMS_socByDvVoltageChangeOverAh "High-voltage battery management system: soc by dv voltage change over ah";
CM_ SG_ 946 BMS_socByDvMaxSocByAhCorrected "High-voltage battery management system: soc by dv max soc by ah corrected";
CM_ SG_ 946 BMS_socByDvMaxBrickVoltage "High-voltage battery management system: soc by dv max brick voltage";
CM_ SG_ 946 BMS_socByDvMaxBrickId "High-voltage battery management system: soc by dv max brick id";
CM_ SG_ 946 BMS_socByDvMaxSocByAhRaw "High-voltage battery management system: soc by dv max soc by ah raw";
CM_ SG_ 946 BMS_voltageInstabilityExcessNois "High-voltage battery management system: voltage instability excess noise log";
CM_ SG_ 946 BMS_maxModelThermistorTempDelta "High-voltage battery management system: max model thermistor temp delta";
CM_ SG_ 946 BMS_activeCoolCellTargetT "High-voltage battery management system: active cool cell target t";
CM_ SG_ 946 BMS_cellTempTargetMode "Operating mode of the thermal controls for the Battery Management System (BMS)";
CM_ SG_ 946 BMS_minPackTempForChargeToStart "High-voltage battery management system: min pack temp for charge to start";
CM_ BO_ 914 "High-voltage battery management system message: pack config";
CM_ SG_ 914 BMS_packConfigMultiplexer "High-voltage battery management system: pack config multiplexer";
CM_ SG_ 914 BMS_reservedConfig_0 "High-voltage battery management system: reserved config 0";
CM_ SG_ 914 BMS_moduleType "High-voltage battery management system: module type";
CM_ SG_ 914 BMS_thermalPackType "High-voltage battery management system: thermal pack type";
CM_ SG_ 914 BMS_packMass "High-voltage battery management system: pack mass";
CM_ SG_ 914 BMS_platformMaxBusVoltage "High-voltage battery management system: platform max bus voltage";
CM_ SG_ 914 BMS_standbySupplyContinuousPower "High-voltage battery management system: standby supply continuous power limit";
CM_ SG_ 914 BMS_beginningOfLifePackEnergy "High-voltage battery management system: beginning of life pack energy";
CM_ BO_ 1810 "High-voltage battery management system message: pack temperature measurements";
CM_ SG_ 1810 BMS_packTemperatureMultiplexer "High-voltage battery management system: pack temperature multiplexer";
CM_ SG_ 1810 BMS_packTemperatureCounter "High-voltage battery management system: pack temperature counter";
CM_ SG_ 1810 BMS_packTemperatureStatus1 "High-voltage battery management system: pack temperature status1";
CM_ SG_ 1810 BMS_packTemperatureStatus2 "High-voltage battery management system: pack temperature status2";
CM_ SG_ 1810 BMS_packTemperatureStatus3 "High-voltage battery management system: pack temperature status3";
CM_ SG_ 1810 BMS_packTemperature1 "Measured temperature of location within the pack";
CM_ SG_ 1810 BMS_packTemperature2 "Measured temperature of location within the pack";
CM_ SG_ 1810 BMS_packTemperature3 "Measured temperature of location within the pack";
CM_ SG_ 1810 BMS_packTemperatureStatus4 "High-voltage battery management system: pack temperature status4";
CM_ SG_ 1810 BMS_packTemperatureStatus5 "High-voltage battery management system: pack temperature status5";
CM_ SG_ 1810 BMS_packTemperatureStatus6 "High-voltage battery management system: pack temperature status6";
CM_ SG_ 1810 BMS_packTemperature4 "Measured temperature of location within the pack";
CM_ SG_ 1810 BMS_packTemperature5 "Measured temperature of location within the pack";
CM_ SG_ 1810 BMS_packTemperature6 "Measured temperature of location within the pack";
CM_ SG_ 1810 BMS_packTemperatureStatus7 "High-voltage battery management system: pack temperature status7";
CM_ SG_ 1810 BMS_packTemperatureStatus8 "High-voltage battery management system: pack temperature status8";
CM_ SG_ 1810 BMS_packTemperatureStatus9 "High-voltage battery management system: pack temperature status9";
CM_ SG_ 1810 BMS_packTemperature7 "Measured temperature of location within the pack";
CM_ SG_ 1810 BMS_packTemperature8 "Measured temperature of location within the pack";
CM_ SG_ 1810 BMS_packTemperature9 "Measured temperature of location within the pack";
CM_ SG_ 1810 BMS_packTemperatureStatus10 "High-voltage battery management system: pack temperature status10";
CM_ SG_ 1810 BMS_packTemperatureStatus11 "High-voltage battery management system: pack temperature status11";
CM_ SG_ 1810 BMS_packTemperatureStatus12 "High-voltage battery management system: pack temperature status12";
CM_ SG_ 1810 BMS_packTemperature10 "Measured temperature of location within the pack";
CM_ SG_ 1810 BMS_packTemperature11 "Measured temperature of location within the pack";
CM_ SG_ 1810 BMS_packTemperature12 "Measured temperature of location within the pack";
CM_ SG_ 1810 BMS_packTemperatureStatus13 "High-voltage battery management system: pack temperature status13";
CM_ SG_ 1810 BMS_packTemperatureStatus14 "High-voltage battery management system: pack temperature status14";
CM_ SG_ 1810 BMS_packTemperatureStatus15 "High-voltage battery management system: pack temperature status15";
CM_ SG_ 1810 BMS_packTemperature13 "Measured temperature of location within the pack";
CM_ SG_ 1810 BMS_packTemperature14 "Measured temperature of location within the pack";
CM_ SG_ 1810 BMS_packTemperature15 "Measured temperature of location within the pack";
CM_ SG_ 1810 BMS_packTemperatureStatus16 "High-voltage battery management system: pack temperature status16";
CM_ SG_ 1810 BMS_packTemperatureStatus17 "High-voltage battery management system: pack temperature status17";
CM_ SG_ 1810 BMS_packTemperatureStatus18 "High-voltage battery management system: pack temperature status18";
CM_ SG_ 1810 BMS_packTemperature16 "Measured temperature of location within the pack";
CM_ SG_ 1810 BMS_packTemperature17 "Measured temperature of location within the pack";
CM_ SG_ 1810 BMS_packTemperature18 "Measured temperature of location within the pack";
CM_ BO_ 594 "High-voltage battery management system message: power available";
CM_ SG_ 594 BMS_maxRegenPower "Calculated max regen power";
CM_ SG_ 594 BMS_maxDischargePower "Calculated max discharge power possible based on max discharge current and sum of loaded voltages";
CM_ SG_ 594 BMS_maxStationaryHeatPower "Maximum heating power the DI can produce when in stationary heating mode";
CM_ SG_ 594 BMS_powerLimitsState "High-voltage battery management system: power limits state";
CM_ SG_ 594 BMS_totalHvPowerBudget "Maximum total power that the High Voltage (HV) battery and Electric Vehicle Supply Equipment (EVSE) (if present) can safely produce";
CM_ SG_ 594 BMS_notEnoughPowerForHeatPump "Flag indicating the min pack power is lower than specified threshold to support heating with the heat pump";
CM_ BO_ 674 "High-voltage battery management system message: ripple request";
CM_ SG_ 674 BMS_acRippleCurrentAmplitudeLimi "Transmits the Battery Management System (BMS) AC ripple current amplitude limit to the Electric Vehicle Supply Equipment (EVSE).";
CM_ SG_ 674 BMS_acRippleMaxVoltageLimit "Reports the maximum voltage limit when the Electric Vehicle Supply Equipment (EVSE) is performing the AC ripple.";
CM_ SG_ 674 BMS_acRippleMinVoltageLimit "Reports the minimum voltage limit when the Electric Vehicle Supply Equipment (EVSE) is performing the AC ripple.";
CM_ SG_ 674 BMS_acRippleFrequencyRequest "Transmits the Battery Management System (BMS) AC ripple frequency request to the Electric Vehicle Supply Equipment (EVSE).";
CM_ SG_ 674 BMS_acRippleCurrentAmplitudeRequ "Transmits the Battery Management System (BMS) AC ripple current amplitude request to the Electric Vehicle Supply Equipment (EVSE).";
CM_ SG_ 674 BMS_acRippleRequest "High-voltage battery management system: ac ripple request";
CM_ BO_ 658 "High-voltage battery management system message: soc status";
CM_ SG_ 658 BMS_socMin "BMS State Of Charge (SOC). This is the minimum brick SOC.";
CM_ SG_ 658 BMS_socUI "BMS State Of Energy (SOE) for the UI. This is ideal discharge energy from present state / ideal discharge energy from full.";
CM_ SG_ 658 BMS_socMax "BMS State Of Charge (SOC). This is the maximum brick SOC.";
CM_ SG_ 658 BMS_socAvg "BMS State Of Charge (SOC). This is the average of all the brick SOCs";
CM_ SG_ 658 BMS_enoughEnergyForConvenienceFe "Flag to indicate if there is enough energy for user facing features that are function of the UI discharge limit";
CM_ SG_ 658 BMS_instantChargePowerCapability "Indicates the instantaneous charge power capability of the high voltage battery.";
CM_ BO_ 1170 "High-voltage battery management system message: state of health";
CM_ SG_ 1170 BMS_sohEnergyPercent "Estimate of battery SOH Energy % based on the most accurate capacity estimates the BMS has available";
CM_ SG_ 1170 BMS_userFacingSohTestState "High-voltage battery management system: user facing soh test state";
CM_ SG_ 1170 BMS_userFacingSohTestEndMode "High-voltage battery management system: user facing soh test end mode";
CM_ SG_ 1170 BMS_timeSinceSohUpdate "Days since last successful SOH test";
CM_ SG_ 1170 BMS_sohTestCycleFlag "Flag that is True from the start of an SOH test until it ends and all relevant signals have been logged";
CM_ SG_ 1170 BMS_sohTestIsBlocked "High-voltage battery management system: soh test is blocked";
CM_ SG_ 1170 BMS_calibratedSohAvailable "SOH Energy is based on valid results from the SOH capacity test";
CM_ SG_ 1170 BMS_requiredEvsePowerForSoh "High-voltage battery management system: required evse power for soh";
CM_ SG_ 1170 BMS_distanceSinceSohUpdate "Distance since the last State of Health update in km";
CM_ BO_ 530 "High-voltage battery management system message: status";
CM_ SG_ 530 BMS_hvacPowerRequest "High-voltage battery management system: hvac power request";
CM_ SG_ 530 BMS_notEnoughPowerForDrive "Flag indicating the min pack power is lower than specified threshold to support drive";
CM_ SG_ 530 BMS_notEnoughPowerForSupport "Flag indicating if the system can support a new request for 12V battery support";
CM_ SG_ 530 BMS_preconditionAllowed "High-voltage battery management system: precondition allowed";
CM_ SG_ 530 BMS_updateAllowed "High-voltage battery management system: update allowed";
CM_ SG_ 530 BMS_cpMiaOnHvs "Flag indicating that BMS is no longer receiving comms from CP on HVS bus";
CM_ SG_ 530 BMS_pcsPwmEnabled "Reports the state of the PCS_PWM_ENABLE input on the HVBMS, which is derived from the P1-12-DCDC-ENABLE input, which comes from VCFRONT";
CM_ SG_ 530 BMS_contactorState "BMS Contactor Status";
CM_ SG_ 530 BMS_userChargeStatus "BMS charge status for UI display. Renamed from BMS_uiChargeStatus";
CM_ SG_ 530 BMS_batteryInputPower "High-voltage battery management system: battery input power";
CM_ SG_ 530 BMS_chargeRequest "Indicates charge is available and charge is desired";
CM_ SG_ 530 BMS_state "BMS operating state.";
CM_ SG_ 530 BMS_diLimpRequest "BMS request to DI to enter limp mode";
CM_ SG_ 530 BMS_okToShipByAir "High-voltage battery management system: ok to ship by air";
CM_ SG_ 530 BMS_okToShipByLand "High-voltage battery management system: ok to ship by land";
CM_ SG_ 530 BMS_chgPowerAvailable "BMS available charge power";
CM_ SG_ 530 BMS_acManagerState "High-voltage battery management system: ac manager state";
CM_ SG_ 530 BMS_conditioningRequest "BMS request to enable conditioning so it can attempt FEIM recovery";
CM_ SG_ 530 BMS_smStateRequest "BMS high level state request";
CM_ SG_ 530 BMS_hvState "BMS high voltage state";
CM_ BO_ 786 "High-voltage battery management system message: thermal status";
CM_ SG_ 786 BMS_thermalStatusMultiplexer "High-voltage battery management system: thermal status multiplexer";
CM_ SG_ 786 BMS_inletActiveCoolTargetT "Calculated active cooling temperature target at the inlet";
CM_ SG_ 786 BMS_inletPassiveTargetT "Calculated passive temperature target at the inlet";
CM_ SG_ 786 BMS_inletActiveHeatTargetT "Calculated active heating temperature target at the inlet";
CM_ SG_ 786 BMS_requestDischarge "Flag identifying when the Battery Management System (BMS) is requesting the battery pack to be discharged";
CM_ SG_ 786 BMS_activeHeatingWorthwhile "Determination by the Battery Management System (BMS) if active heating is worthwhile";
CM_ SG_ 786 BMS_pcsNoFlowRequest "High-voltage battery management system: pcs no flow request";
CM_ SG_ 786 BMS_minPackTemperature "Minimum pack temperature for consumption by external entities";
CM_ SG_ 786 BMS_noFlowRequest "High-voltage battery management system: no flow request";
CM_ SG_ 786 BMS_maxPackTemperature "Maximum pack temperature for consumption by external entities";
CM_ SG_ 786 BMS_flowRequest "Requested coolant flow rate in liters per minute (LPM) from the Battery Management System (BMS) to the thermal module";
CM_ SG_ 786 BMS_coldStagnationLimit "Minimum temperature at which the pack is allowed to be used as a heat-energy source";
CM_ SG_ 786 BMS_hotStagnationLimit "Maximum temperature at which we allow the pack to be used for heat-energy storage";
CM_ SG_ 786 BMS_hotCellTempLimit "Maximum temperature at which the pack will allow limp mode levels of current";
CM_ SG_ 786 BMS_i2tDeratingEnabled "High-voltage battery management system: i2t derating enabled";
CM_ SG_ 786 BMS_activeCoolCellReferenceT "Desired cell temperature reference which composes the temperature trajectory portion of the active cooling target temperature controls";
CM_ SG_ 786 BMS_activeHeatCellTargetT "Desired cell temperature which feeds as an input to the active heating target temperature, before any additional controls calculations";
CM_ SG_ 786 BMS_powerDissipation "High-voltage battery management system: power dissipation";
CM_ BO_ 1071 "High-voltage battery management system message: v2x info";
CM_ SG_ 1071 BMS_v2xSoe "High-voltage battery management system: v2x soe";
CM_ SG_ 1071 BMS_v2xFullEnergy "High-voltage battery management system: v2x full energy";
CM_ SG_ 1071 BMS_v2xPackPower "High-voltage battery management system: v2x pack power";
CM_ SG_ 1071 BMS_acDischargeBlockedReason "The enumerated reason why the ECU is blocking AC discharge";
CM_ SG_ 1071 BMS_backupTimeRemaining "High-voltage battery management system: backup time remaining";
CM_ BO_ 754 "High-voltage battery management system message: veh nm";
CM_ SG_ 754 BMS_nmGoingToSleep "High-voltage battery management system: nm going to sleep";
CM_ SG_ 754 BMS_nmWakeUpBus "High-voltage battery management system: nm wake up bus";
CM_ SG_ 754 BMS_hvsBusAsleep "HVS bus reported as off";
CM_ SG_ 754 BMS_nmKeepAwakeReason "BMS' determined reason to keep CAN awake";
CM_ SG_ 754 BMS_nmWakeUpReason "BMS' determined reason to wake up CAN";
CM_ BO_ 810 "High-voltage battery management system message: vehicle notifications";
CM_ SG_ 810 BMS_thermalEventSuspected "Indicates the Battery Management System (BMS) has detected conditions that reflect a possible battery thermal event";
CM_ SG_ 810 BMS_vehicleNotificationsCounter "High-voltage battery management system: vehicle notifications counter";
CM_ SG_ 810 BMS_isolationResistance "Resistance between HV bus and chassis.";
CM_ SG_ 810 BMS_chgTimeToFull "Estimated time remaining until charge termination percent will be reached";
CM_ SG_ 810 BMS_vehicleNotificationsChecksum "High-voltage battery management system: vehicle notifications checksum";
CM_ BO_ 1116 "Charge cable controller message: alert log";
CM_ SG_ 1116 CC_alertID "Charge cable controller: alert ID";
CM_ SG_ 1116 CC_alertType "Charge cable controller: alert type";
CM_ SG_ 1116 CC_a001_groundResistance "Charge cable controller: a001 ground resistance";
CM_ SG_ 1116 CC_a003_gfciRmsCurrent "Charge cable controller: a003 gfci rms current";
CM_ SG_ 1116 CC_a003_gfciRmsCurrentAvg "Charge cable controller: a003 gfci rms current avg";
CM_ SG_ 1116 CC_a003_dcGfciCurrent "Charge cable controller: a003 dc gfci current";
CM_ SG_ 1116 CC_a003_gfciFaultReason "Charge cable controller: a003 gfci fault reason";
CM_ SG_ 1116 CC_a003_gfciFaultBucket "Charge cable controller: a003 gfci fault bucket";
CM_ SG_ 1116 CC_a004_gfciErrorReason "Charge cable controller: a004 gfci error reason";
CM_ SG_ 1116 CC_a004_gfciAsicErrorBitfield "Charge cable controller: a004 gfci asic error bitfield";
CM_ SG_ 1116 CC_a004_gfciSelfTestDuty "Charge cable controller: a004 gfci self test duty";
CM_ SG_ 1116 CC_a004_gfciSelfTestCurrent "Charge cable controller: a004 gfci self test current";
CM_ SG_ 1116 CC_a006_line1Current "Charge cable controller: a006 line1 current";
CM_ SG_ 1116 CC_a006_line2Current "Charge cable controller: a006 line2 current";
CM_ SG_ 1116 CC_a006_line3Current "Charge cable controller: a006 line3 current";
CM_ SG_ 1116 CC_a007_inputVoltage "Charge cable controller: a007 input voltage";
CM_ SG_ 1116 CC_a007_inputLineVoltage "Charge cable controller: a007 input line voltage";
CM_ SG_ 1116 CC_a007_inputNeutralVoltage "Charge cable controller: a007 input neutral voltage";
CM_ SG_ 1116 CC_a008_inputVoltage "Charge cable controller: a008 input voltage";
CM_ SG_ 1116 CC_a008_inputLineVoltage "Charge cable controller: a008 input line voltage";
CM_ SG_ 1116 CC_a008_inputNeutralVoltage "Charge cable controller: a008 input neutral voltage";
CM_ SG_ 1116 CC_a010_line1Voltage "Charge cable controller: a010 line1 voltage";
CM_ SG_ 1116 CC_a010_line2Voltage "Charge cable controller: a010 line2 voltage";
CM_ SG_ 1116 CC_a010_line3Voltage "Charge cable controller: a010 line3 voltage";
CM_ SG_ 1116 CC_a010_line1StuckClosed "Charge cable controller: a010 line1 stuck closed";
CM_ SG_ 1116 CC_a010_line2StuckClosed "Charge cable controller: a010 line2 stuck closed";
CM_ SG_ 1116 CC_a010_line3StuckClosed "Charge cable controller: a010 line3 stuck closed";
CM_ SG_ 1116 CC_a011_pcbaTemp "Charge cable controller: a011 pcba temp";
CM_ SG_ 1116 CC_a012_inputThermopile "Charge cable controller: a012 input thermopile";
CM_ SG_ 1116 CC_a012_inputThermopileDvdt "Charge cable controller: a012 input thermopile dvdt";
CM_ SG_ 1116 CC_a013_handleTemp "Charge cable controller: a013 handle temp";
CM_ SG_ 1116 CC_a014_failureCause "Charge cable controller: a014 failure cause";
CM_ SG_ 1116 CC_a014_meterFaultAddress "Charge cable controller: a014 meter fault address";
CM_ SG_ 1116 CC_a014_meterFaultData "Charge cable controller: a014 meter fault data";
CM_ SG_ 1116 CC_a014_meterRetryCount "Charge cable controller: a014 meter retry count";
CM_ SG_ 1116 CC_a015_pilotHighVolage "Charge cable controller: a015 pilot high volage";
CM_ SG_ 1116 CC_a015_smState "Charge cable controller: a015 sm state";
CM_ SG_ 1116 CC_a027_handleTemperature "Charge cable controller: a027 handle temperature";
CM_ SG_ 1116 CC_a027_handleTempFaultReason "Charge cable controller: a027 handle temp fault reason";
CM_ SG_ 1116 CC_a032_meteringSpiCommsFailure "Charge cable controller: a032 metering spi comms failure";
CM_ SG_ 1116 CC_a032_meteringConfigMismatch "Charge cable controller: a032 metering config mismatch";
CM_ SG_ 1116 CC_a033_nominalVoltage "Charge cable controller: a033 nominal voltage";
CM_ SG_ 1116 CC_a033_measuredVoltage "Charge cable controller: a033 measured voltage";
CM_ SG_ 1116 CC_a036_line1Voltage "Charge cable controller: a036 line1 voltage";
CM_ SG_ 1116 CC_a036_line2Voltage "Charge cable controller: a036 line2 voltage";
CM_ SG_ 1116 CC_a036_line3Voltage "Charge cable controller: a036 line3 voltage";
CM_ SG_ 1116 CC_a036_line1StuckOpen "Charge cable controller: a036 line1 stuck open";
CM_ SG_ 1116 CC_a036_line2StuckOpen "Charge cable controller: a036 line2 stuck open";
CM_ SG_ 1116 CC_a036_line3StuckOpen "Charge cable controller: a036 line3 stuck open";
CM_ SG_ 1116 CC_a037_expiredWatchdogModuleId "Charge cable controller: a037 expired watchdog module id";
CM_ SG_ 1116 CC_a037_expiredWatchdogTaskId "Charge cable controller: a037 expired watchdog task id";
CM_ SG_ 1116 CC_a037_expiredWatchdogAppCRC "Charge cable controller: a037 expired watchdog app CRC";
CM_ SG_ 1116 CC_a038_moduleMiaModuleId "Charge cable controller: a038 module mia module id";
CM_ SG_ 1116 CC_a038_moduleMiaTaskId "Charge cable controller: a038 module mia task id";
CM_ SG_ 1116 CC_a038_moduleMiaAppCRC "Charge cable controller: a038 module mia app CRC";
CM_ SG_ 1116 CC_a039_intModuleTemperature "Charge cable controller: a039 int module temperature";
CM_ SG_ 1116 CC_a040_handleTemperature "Charge cable controller: a040 handle temperature";
CM_ SG_ 1116 CC_a041_inputThermopile "Charge cable controller: a041 input thermopile";
CM_ SG_ 1116 CC_a041_inputThermopileDvdt "Charge cable controller: a041 input thermopile dvdt";
CM_ SG_ 1116 CC_a042_pcbaTemperature "Charge cable controller: a042 pcba temperature";
CM_ SG_ 1116 CC_a044_relayCoilVoltage "Charge cable controller: a044 relay coil voltage";
CM_ SG_ 1116 CC_a044_pcbaTemperature "Charge cable controller: a044 pcba temperature";
CM_ BO_ 1132 "Charge cable controller message: alert matrix1";
CM_ SG_ 1132 CC_a001_gndMonIntrptLineSide "Charge cable controller: a001 gnd mon intrpt line side";
CM_ SG_ 1132 CC_a002_gndMonIntrptLoadSide "Charge cable controller: a002 gnd mon intrpt load side";
CM_ SG_ 1132 CC_a003_CCIDTripped "Charge cable controller: a003 CCID tripped";
CM_ SG_ 1132 CC_a004_CCIDSelfTestFault "Charge cable controller: a004 CCID self test fault";
CM_ SG_ 1132 CC_a005_groundedNeutral "Charge cable controller: a005 grounded neutral";
CM_ SG_ 1132 CC_a006_inputOverCurrent "Charge cable controller: a006 input over current";
CM_ SG_ 1132 CC_a007_inputOverVoltage "Charge cable controller: a007 input over voltage";
CM_ SG_ 1132 CC_a008_inputUnderVoltage "Charge cable controller: a008 input under voltage";
CM_ SG_ 1132 CC_a009_inputMiswired "Charge cable controller: a009 input miswired";
CM_ SG_ 1132 CC_a010_contactorWelded "Charge cable controller: a010 contactor welded";
CM_ SG_ 1132 CC_a011_ambientOT "Charge cable controller: a011 ambient OT";
CM_ SG_ 1132 CC_a012_wallPlugOT "Charge cable controller: a012 wall plug OT";
CM_ SG_ 1132 CC_a013_vehConnOT "Charge cable controller: a013 veh conn OT";
CM_ SG_ 1132 CC_a014_mcuSelfTestFault "Charge cable controller: a014 mcu self test fault";
CM_ SG_ 1132 CC_a015_PilotAFault "Charge cable controller: a015 pilot a fault";
CM_ SG_ 1132 CC_a016_PilotBFault "Charge cable controller: a016 pilot b fault";
CM_ SG_ 1132 CC_a017_PilotCFault "Charge cable controller: a017 pilot c fault";
CM_ SG_ 1132 CC_a018_PilotDFault "Charge cable controller: a018 pilot d fault";
CM_ SG_ 1132 CC_a019_proxDisconnected "Charge cable controller: a019 prox disconnected";
CM_ SG_ 1132 CC_a020_3vRailIncorrect "Charge cable controller: a020 3v rail incorrect";
CM_ SG_ 1132 CC_a021_CB_noMaster "Charge cable controller: a021 CB no master";
CM_ SG_ 1132 CC_a022_CB_tooManyMasters "Charge cable controller: a022 CB too many masters";
CM_ SG_ 1132 CC_a023_CB_tooManySlaves "Charge cable controller: a023 CB too many slaves";
CM_ SG_ 1132 CC_a024_CB_masterISetTooLow "Charge cable controller: a024 CB master i set too low";
CM_ SG_ 1132 CC_a025_evseTemp "Charge cable controller: a025 evse temp";
CM_ SG_ 1132 CC_a026_wallPlugTemp "Charge cable controller: a026 wall plug temp";
CM_ SG_ 1132 CC_a027_vehicleHandleTemp "Charge cable controller: a027 vehicle handle temp";
CM_ SG_ 1132 CC_a028_CB_rotarySelect "Charge cable controller: a028 CB rotary select";
CM_ SG_ 1132 CC_a029_PilotFFault "Charge cable controller: a029 pilot f fault";
CM_ SG_ 1132 CC_a030_masterSlaveMismatch "Charge cable controller: a030 master slave mismatch";
CM_ SG_ 1132 CC_a031_pllLockLost "Charge cable controller: a031 pll lock lost";
CM_ SG_ 1132 CC_a032_meteringFailure "Charge cable controller: a032 metering failure";
CM_ SG_ 1132 CC_a033_vRefOutOfRange "Charge cable controller: a033 v ref out of range";
CM_ SG_ 1132 CC_a034_bootAlert "Charge cable controller: a034 boot alert";
CM_ SG_ 1132 CC_a035_CCIDCalibration "Charge cable controller: a035 CCID calibration";
CM_ SG_ 1132 CC_a036_contactorStuckOpen "Charge cable controller: a036 contactor stuck open";
CM_ SG_ 1132 CC_a037_internalModuleWatchdogEx "Charge cable controller: a037 internal module watchdog expired";
CM_ SG_ 1132 CC_a038_internalModuleMia "Charge cable controller: a038 internal module mia";
CM_ SG_ 1132 CC_a039_internalModuleOverTemp "Charge cable controller: a039 internal module over temp";
CM_ SG_ 1132 CC_a040_handleTempFoldback "Charge cable controller: a040 handle temp foldback";
CM_ SG_ 1132 CC_a041_inputWiringFoldback "Charge cable controller: a041 input wiring foldback";
CM_ SG_ 1132 CC_a042_pcbaTempFoldback "Charge cable controller: a042 pcba temp foldback";
CM_ SG_ 1132 CC_a043_configurationRequired "Charge cable controller: a043 configuration required";
CM_ SG_ 1132 CC_a044_relayCoilVoltageRational "Charge cable controller: a044 relay coil voltage rationality";
CM_ SG_ 1132 CC_a045_ACPowerLoss "Charge cable controller: a045 AC power loss";
CM_ SG_ 1132 CC_a046_GFCIConfigInvalid "Charge cable controller: a046 GFCI config invalid";
CM_ SG_ 1132 CC_a047_MDMotorContFault "Charge cable controller: a047 MD motor cont fault";
CM_ SG_ 1132 CC_a048_ACMDAdapterFault "Charge cable controller: a048 ACMD adapter fault";
CM_ SG_ 1132 CC_a049_rs485Fault "Charge cable controller: a049 rs485 fault";
CM_ SG_ 1132 CC_a050_eFuseFault "Charge cable controller: a050 e fuse fault";
CM_ SG_ 1132 CC_a051_chcCriticalFault "Charge cable controller: a051 chc critical fault";
CM_ SG_ 1132 CC_a052_vRefOutOfRangePWM "Charge cable controller: a052 v ref out of range PWM";
CM_ SG_ 1132 CC_a057_chcVitalsRequestFailure "Charge cable controller: a057 chc vitals request failure";
CM_ SG_ 1132 CC_a060_persistenceFault "Charge cable controller: a060 persistence fault";
CM_ SG_ 1132 CC_a061_unfinishedCommissioning "Charge cable controller: a061 unfinished commissioning";
CM_ BO_ 796 "Charge cable controller message: chg status";
CM_ SG_ 796 CC_currentLimit "Maximum allowable AC current the wall connector is willing to provide";
CM_ SG_ 796 CC_pilotState "State of pilot signal reported by the wall connector";
CM_ SG_ 796 CC_numPhases "Number of AC phases expected by wall connector";
CM_ SG_ 796 CC_line1Voltage "RMS voltage on L1 terminal of wall connector";
CM_ SG_ 796 CC_gridGrounding "Grouding scheme expected by the wall connector";
CM_ SG_ 796 CC_deltaTransformer "Grid configuration expected by the wall connector";
CM_ SG_ 796 CC_numVehCharging "Number of vehicles charging in wall connector load sharing group";
CM_ SG_ 796 CC_line2Voltage "RMS voltage on L2 terminal of wall connector";
CM_ SG_ 796 CC_line3Voltage "RMS voltage on L3 terminal of wall connector";
CM_ SG_ 796 CC_groundResistance "Charge cable controller: ground resistance";
CM_ BO_ 797 "Charge cable controller message: chg status2";
CM_ SG_ 797 CC_chgStatus2Index "Charge cable controller: chg status2 index";
CM_ SG_ 797 CC_buttonState "Charge cable controller: button state";
CM_ SG_ 797 EVSE_v2xSupport "Charge cable controller: v2x support";
CM_ SG_ 797 EVSE_v2xHandshakeStart "Charge cable controller: v2x handshake start";
CM_ SG_ 797 EVSE_v2xSessionType "Charge cable controller: v2x session type";
CM_ BO_ 812 "Charge cable controller message: log data";
CM_ SG_ 812 CC_logIndex "Charge cable controller: log index";
CM_ SG_ 812 CC_activeConnectorID "Site identifier of active charge connector";
CM_ SG_ 812 CC_temperature1 "Charge cable vehicle connector temperature";
CM_ SG_ 812 CC_temperature2 "Charge cable vehicle connector temperature";
CM_ SG_ 812 CC_temperature3 "Charge cable vehicle connector temperature";
CM_ SG_ 812 CC_contactor1Closed "State of contactor 1 in wall connector";
CM_ SG_ 812 CC_contactor2Closed "State of contactor 1 in wall connector";
CM_ SG_ 812 CC_temperature4 "Charge cable vehicle connector temperature";
CM_ SG_ 812 CC_conn1Current "AC current on connector 1 in wall charger load sharing group";
CM_ SG_ 812 CC_conn2Current "AC current on connector 2 in wall charger load sharing group";
CM_ SG_ 812 CC_conn3Current "AC current on connector 3 in wall charger load sharing group";
CM_ SG_ 812 CC_conn4Current "AC current on connector 4 in wall charger load sharing group";
CM_ SG_ 812 CC_lifetimei2t "Charge cable controller: lifetimei2t";
CM_ SG_ 812 CC_lifetimeCtrCycles "Charge cable controller: lifetime ctr cycles";
CM_ SG_ 812 CC_lifetimeCtrCyclesLoaded "Charge cable controller: lifetime ctr cycles loaded";
CM_ SG_ 812 CC_lifetimeAlertCount "Charge cable controller: lifetime alert count";
CM_ SG_ 812 CC_lifetimeThermalFoldbacks "Charge cable controller: lifetime thermal foldbacks";
CM_ SG_ 812 CC_lifetimeAvgStartupTemp "Charge cable controller: lifetime avg startup temp";
CM_ BO_ 870 "CMPD ECU message: info";
CM_ SG_ 870 CMPD_infoIndex "CMPD ECU: info index";
CM_ SG_ 870 CMPD_infoBuildType "CMPD ECU: info build type";
CM_ SG_ 870 CMPD_infoBuildConfigId "CMPD ECU: info build config id";
CM_ SG_ 870 CMPD_infoHardwareId "CMPD ECU: info hardware id";
CM_ SG_ 870 CMPD_infoComponentId "CMPD ECU: info component id";
CM_ SG_ 870 CMPD_infoPcbaId "CMPD ECU: info pcba id";
CM_ SG_ 870 CMPD_infoAssemblyId "CMPD ECU: info assembly id";
CM_ SG_ 870 CMPD_infoUsageId "CMPD ECU: info usage id";
CM_ SG_ 870 CMPD_infoSubUsageId "CMPD ECU: info sub usage id";
CM_ BO_ 680 "CMPD ECU message: state";
CM_ SG_ 680 CMPD_speedRPM "Reports compressor speed.";
CM_ SG_ 680 CMPD_speedDuty "Reports compressor speed duty cycle percentage.";
CM_ SG_ 680 CMPD_inputHVPower "Measures compressor input high voltage (HV) power consumption.";
CM_ SG_ 680 CMPD_inputHVCurrent "Measures compressor input high voltage (HV) current draw.";
CM_ SG_ 680 CMPD_inputHVVoltage "Measures compressor input high voltage (HV) level.";
CM_ SG_ 680 CMPD_2ShuntModeActive "Indicates the compressor motor control is running using only two current shunt resistors instead of three.";
CM_ SG_ 680 CMPD_powerLimitActive "Indicates the compressor power limit is active.";
CM_ SG_ 680 CMPD_state "Reports compressor operational state.";
CM_ SG_ 680 CMPD_wasteHeatState "Reports compressor waste heat recovery state.";
CM_ SG_ 680 CMPD_powerLimitTooLowToStart "Indicates the compressor power limit is too low to start the compressor.";
CM_ SG_ 680 CMPD_ready "Indicates the compressor is ready to start.";
CM_ BO_ 551 "A/C compressor message: HV status";
CM_ SG_ 551 CMP_inputHVVoltage "Compressor high voltage input voltage";
CM_ SG_ 551 CMP_inputLVVoltage "A/C compressor: input LV voltage";
CM_ SG_ 551 CMP_inputHVCurrent "A/C compressor: input HV current";
CM_ SG_ 551 CMP_inputHVPower "Compressor high voltage input power";
CM_ BO_ 867 "A/C compressor message: info";
CM_ SG_ 867 CMP_infoIndex "A/C compressor: info index";
CM_ SG_ 867 CMP_infoBuildType "A/C compressor: info build type";
CM_ SG_ 867 CMP_infoBuildConfigId "A/C compressor: info build config id";
CM_ SG_ 867 CMP_infoHardwareId "A/C compressor: info hardware id";
CM_ SG_ 867 CMP_infoComponentId "A/C compressor: info component id";
CM_ SG_ 867 CMP_infoPcbaId "A/C compressor: info pcba id";
CM_ SG_ 867 CMP_infoAssemblyId "A/C compressor: info assembly id";
CM_ SG_ 867 CMP_infoUsageId "A/C compressor: info usage id";
CM_ SG_ 867 CMP_infoSubUsageId "A/C compressor: info sub usage id";
CM_ SG_ 867 CMP_infoPlatformType "A/C compressor: info platform type";
CM_ SG_ 867 CMP_infoAppCrc "A/C compressor: info app crc";
CM_ SG_ 867 CMP_infoBootUdsProtoVersion "A/C compressor: info boot uds proto version";
CM_ SG_ 867 CMP_infoBootCrc "A/C compressor: info boot crc";
CM_ BO_ 1767 "Charge port controller message: iso tp pipe to pncd";
CM_ SG_ 1767 CP_isoTpToPncdData "Charge port controller: iso tp to pncd data";
BA_DEF_ BO_ "GenMsgCycleTime" INT 0 3600000;
BA_DEF_ BO_ "GenMsgSendType" ENUM "Cyclic","NotUsed","NotUsed","NotUsed","NotUsed","NotUsed","NotUsed","IfActive","NoMsgSendType","NotUsed";
BA_DEF_ BO_ "VFrameFormat" ENUM "StandardCAN","ExtendedCAN","reserved","J1939PG","reserved","reserved","reserved","reserved","reserved","reserved","reserved","reserved","reserved","reserved","StandardCAN_FD","ExtendedCAN_FD";
BA_DEF_ BO_ "CANFD_BRS" ENUM "0","1";
BA_DEF_ SG_ "SystemSignalLongSymbol" STRING;
BA_DEF_ SG_ "Confidence" ENUM "layout-only","plausible","validated";
BA_DEF_DEF_ "GenMsgCycleTime" 0;
BA_DEF_DEF_ "GenMsgSendType" "NoMsgSendType";
BA_DEF_DEF_ "VFrameFormat" "StandardCAN";
BA_DEF_DEF_ "CANFD_BRS" "1";
BA_DEF_DEF_ "SystemSignalLongSymbol" "";
BA_DEF_DEF_ "Confidence" "layout-only";
BA_ "Confidence" SG_ 1025 BMS_brickVoltageStatus1 1;
BA_ "Confidence" SG_ 1025 BMS_brickVoltageStatus2 1;
BA_ "Confidence" SG_ 1025 BMS_brickVoltageStatus3 1;
BA_ "Confidence" SG_ 1025 BMS_brickVoltage1 1;
BA_ "Confidence" SG_ 1025 BMS_brickVoltage2 1;
BA_ "Confidence" SG_ 1025 BMS_brickVoltage3 1;
BA_ "Confidence" SG_ 1025 BMS_brickVoltageStatus4 1;
BA_ "Confidence" SG_ 1025 BMS_brickVoltageStatus5 1;
BA_ "Confidence" SG_ 1025 BMS_brickVoltageStatus6 1;
BA_ "Confidence" SG_ 1025 BMS_brickVoltage4 1;
BA_ "Confidence" SG_ 1025 BMS_brickVoltage5 1;
BA_ "Confidence" SG_ 1025 BMS_brickVoltage6 1;
BA_ "Confidence" SG_ 1025 BMS_brickVoltageStatus7 1;
BA_ "Confidence" SG_ 1025 BMS_brickVoltageStatus8 1;
BA_ "Confidence" SG_ 1025 BMS_brickVoltageStatus9 1;
BA_ "Confidence" SG_ 1025 BMS_brickVoltage7 1;
BA_ "Confidence" SG_ 1025 BMS_brickVoltage8 1;
BA_ "Confidence" SG_ 1025 BMS_brickVoltage9 1;
BA_ "Confidence" SG_ 1025 BMS_brickVoltageStatus10 1;
BA_ "Confidence" SG_ 1025 BMS_brickVoltageStatus11 1;
BA_ "Confidence" SG_ 1025 BMS_brickVoltageStatus12 1;
BA_ "Confidence" SG_ 1025 BMS_brickVoltage10 1;
BA_ "Confidence" SG_ 1025 BMS_brickVoltage11 1;
BA_ "Confidence" SG_ 1025 BMS_brickVoltage12 1;
BA_ "Confidence" SG_ 1025 BMS_brickVoltageStatus13 1;
BA_ "Confidence" SG_ 1025 BMS_brickVoltageStatus14 1;
BA_ "Confidence" SG_ 1025 BMS_brickVoltageStatus15 1;
BA_ "Confidence" SG_ 1025 BMS_brickVoltage13 1;
BA_ "Confidence" SG_ 1025 BMS_brickVoltage14 1;
BA_ "Confidence" SG_ 1025 BMS_brickVoltage15 1;
BA_ "Confidence" SG_ 1025 BMS_brickVoltageStatus16 1;
BA_ "Confidence" SG_ 1025 BMS_brickVoltageStatus17 1;
BA_ "Confidence" SG_ 1025 BMS_brickVoltageStatus18 1;
BA_ "Confidence" SG_ 1025 BMS_brickVoltage16 1;
BA_ "Confidence" SG_ 1025 BMS_brickVoltage17 1;
BA_ "Confidence" SG_ 1025 BMS_brickVoltage18 1;
BA_ "Confidence" SG_ 1025 BMS_brickVoltageStatus19 1;
BA_ "Confidence" SG_ 1025 BMS_brickVoltageStatus20 1;
BA_ "Confidence" SG_ 1025 BMS_brickVoltageStatus21 1;
BA_ "Confidence" SG_ 1025 BMS_brickVoltage19 1;
BA_ "Confidence" SG_ 1025 BMS_brickVoltage20 1;
BA_ "Confidence" SG_ 1025 BMS_brickVoltage21 1;
BA_ "Confidence" SG_ 1025 BMS_brickVoltageStatus22 1;
BA_ "Confidence" SG_ 1025 BMS_brickVoltageStatus23 1;
BA_ "Confidence" SG_ 1025 BMS_brickVoltageStatus24 1;
BA_ "Confidence" SG_ 1025 BMS_brickVoltage22 1;
BA_ "Confidence" SG_ 1025 BMS_brickVoltage23 1;
BA_ "Confidence" SG_ 1025 BMS_brickVoltage24 1;
BA_ "Confidence" SG_ 1025 BMS_brickVoltageStatus25 1;
BA_ "Confidence" SG_ 1025 BMS_brickVoltageStatus26 1;
BA_ "Confidence" SG_ 1025 BMS_brickVoltageStatus27 1;
BA_ "Confidence" SG_ 1025 BMS_brickVoltage25 1;
BA_ "Confidence" SG_ 1025 BMS_brickVoltage26 1;
BA_ "Confidence" SG_ 1025 BMS_brickVoltage27 1;
BA_ "Confidence" SG_ 1025 BMS_brickVoltageStatus28 1;
BA_ "Confidence" SG_ 1025 BMS_brickVoltageStatus29 1;
BA_ "Confidence" SG_ 1025 BMS_brickVoltageStatus30 1;
BA_ "Confidence" SG_ 1025 BMS_brickVoltage28 1;
BA_ "Confidence" SG_ 1025 BMS_brickVoltage29 1;
BA_ "Confidence" SG_ 1025 BMS_brickVoltage30 1;
BA_ "Confidence" SG_ 1025 BMS_brickVoltageStatus31 1;
BA_ "Confidence" SG_ 1025 BMS_brickVoltageStatus32 1;
BA_ "Confidence" SG_ 1025 BMS_brickVoltageStatus33 1;
BA_ "Confidence" SG_ 1025 BMS_brickVoltage31 1;
BA_ "Confidence" SG_ 1025 BMS_brickVoltage32 1;
BA_ "Confidence" SG_ 1025 BMS_brickVoltage33 1;
BA_ "Confidence" SG_ 1025 BMS_brickVoltageStatus34 1;
BA_ "Confidence" SG_ 1025 BMS_brickVoltageStatus35 1;
BA_ "Confidence" SG_ 1025 BMS_brickVoltageStatus36 1;
BA_ "Confidence" SG_ 1025 BMS_brickVoltage34 1;
BA_ "Confidence" SG_ 1025 BMS_brickVoltage35 1;
BA_ "Confidence" SG_ 1025 BMS_brickVoltage36 1;
BA_ "Confidence" SG_ 1025 BMS_brickVoltageStatus37 1;
BA_ "Confidence" SG_ 1025 BMS_brickVoltageStatus38 1;
BA_ "Confidence" SG_ 1025 BMS_brickVoltageStatus39 1;
BA_ "Confidence" SG_ 1025 BMS_brickVoltage37 1;
BA_ "Confidence" SG_ 1025 BMS_brickVoltage38 1;
BA_ "Confidence" SG_ 1025 BMS_brickVoltage39 1;
BA_ "Confidence" SG_ 1025 BMS_brickVoltageStatus40 1;
BA_ "Confidence" SG_ 1025 BMS_brickVoltageStatus41 1;
BA_ "Confidence" SG_ 1025 BMS_brickVoltageStatus42 1;
BA_ "Confidence" SG_ 1025 BMS_brickVoltage40 1;
BA_ "Confidence" SG_ 1025 BMS_brickVoltage41 1;
BA_ "Confidence" SG_ 1025 BMS_brickVoltage42 1;
BA_ "Confidence" SG_ 1025 BMS_brickVoltageStatus43 1;
BA_ "Confidence" SG_ 1025 BMS_brickVoltageStatus44 1;
BA_ "Confidence" SG_ 1025 BMS_brickVoltageStatus45 1;
BA_ "Confidence" SG_ 1025 BMS_brickVoltage43 1;
BA_ "Confidence" SG_ 1025 BMS_brickVoltage44 1;
BA_ "Confidence" SG_ 1025 BMS_brickVoltage45 1;
BA_ "Confidence" SG_ 1025 BMS_brickVoltageStatus46 1;
BA_ "Confidence" SG_ 1025 BMS_brickVoltageStatus47 1;
BA_ "Confidence" SG_ 1025 BMS_brickVoltageStatus48 1;
BA_ "Confidence" SG_ 1025 BMS_brickVoltage46 1;
BA_ "Confidence" SG_ 1025 BMS_brickVoltage47 1;
BA_ "Confidence" SG_ 1025 BMS_brickVoltage48 1;
BA_ "Confidence" SG_ 1025 BMS_brickVoltageStatus49 1;
BA_ "Confidence" SG_ 1025 BMS_brickVoltageStatus50 1;
BA_ "Confidence" SG_ 1025 BMS_brickVoltageStatus51 1;
BA_ "Confidence" SG_ 1025 BMS_brickVoltage49 1;
BA_ "Confidence" SG_ 1025 BMS_brickVoltage50 1;
BA_ "Confidence" SG_ 1025 BMS_brickVoltage51 1;
BA_ "Confidence" SG_ 1025 BMS_brickVoltageStatus52 1;
BA_ "Confidence" SG_ 1025 BMS_brickVoltageStatus53 1;
BA_ "Confidence" SG_ 1025 BMS_brickVoltageStatus54 1;
BA_ "Confidence" SG_ 1025 BMS_brickVoltage52 1;
BA_ "Confidence" SG_ 1025 BMS_brickVoltage53 1;
BA_ "Confidence" SG_ 1025 BMS_brickVoltage54 1;
BA_ "Confidence" SG_ 1025 BMS_brickVoltageStatus55 1;
BA_ "Confidence" SG_ 1025 BMS_brickVoltageStatus56 1;
BA_ "Confidence" SG_ 1025 BMS_brickVoltageStatus57 1;
BA_ "Confidence" SG_ 1025 BMS_brickVoltage55 1;
BA_ "Confidence" SG_ 1025 BMS_brickVoltage56 1;
BA_ "Confidence" SG_ 1025 BMS_brickVoltage57 1;
BA_ "Confidence" SG_ 1025 BMS_brickVoltageStatus58 1;
BA_ "Confidence" SG_ 1025 BMS_brickVoltageStatus59 1;
BA_ "Confidence" SG_ 1025 BMS_brickVoltageStatus60 1;
BA_ "Confidence" SG_ 1025 BMS_brickVoltage58 1;
BA_ "Confidence" SG_ 1025 BMS_brickVoltage59 1;
BA_ "Confidence" SG_ 1025 BMS_brickVoltage60 1;
BA_ "Confidence" SG_ 1025 BMS_brickVoltageStatus61 1;
BA_ "Confidence" SG_ 1025 BMS_brickVoltageStatus62 1;
BA_ "Confidence" SG_ 1025 BMS_brickVoltageStatus63 1;
BA_ "Confidence" SG_ 1025 BMS_brickVoltage61 1;
BA_ "Confidence" SG_ 1025 BMS_brickVoltage62 1;
BA_ "Confidence" SG_ 1025 BMS_brickVoltage63 1;
BA_ "Confidence" SG_ 1025 BMS_brickVoltageStatus64 1;
BA_ "Confidence" SG_ 1025 BMS_brickVoltageStatus65 1;
BA_ "Confidence" SG_ 1025 BMS_brickVoltageStatus66 1;
BA_ "Confidence" SG_ 1025 BMS_brickVoltage64 1;
BA_ "Confidence" SG_ 1025 BMS_brickVoltage65 1;
BA_ "Confidence" SG_ 1025 BMS_brickVoltage66 1;
BA_ "Confidence" SG_ 1025 BMS_brickVoltageStatus67 1;
BA_ "Confidence" SG_ 1025 BMS_brickVoltageStatus68 1;
BA_ "Confidence" SG_ 1025 BMS_brickVoltageStatus69 1;
BA_ "Confidence" SG_ 1025 BMS_brickVoltage67 1;
BA_ "Confidence" SG_ 1025 BMS_brickVoltage68 1;
BA_ "Confidence" SG_ 1025 BMS_brickVoltage69 1;
BA_ "Confidence" SG_ 1025 BMS_brickVoltageStatus70 1;
BA_ "Confidence" SG_ 1025 BMS_brickVoltageStatus71 1;
BA_ "Confidence" SG_ 1025 BMS_brickVoltageStatus72 1;
BA_ "Confidence" SG_ 1025 BMS_brickVoltage70 1;
BA_ "Confidence" SG_ 1025 BMS_brickVoltage71 1;
BA_ "Confidence" SG_ 1025 BMS_brickVoltage72 1;
BA_ "Confidence" SG_ 1025 BMS_brickVoltageStatus73 1;
BA_ "Confidence" SG_ 1025 BMS_brickVoltageStatus74 1;
BA_ "Confidence" SG_ 1025 BMS_brickVoltageStatus75 1;
BA_ "Confidence" SG_ 1025 BMS_brickVoltage73 1;
BA_ "Confidence" SG_ 1025 BMS_brickVoltage74 1;
BA_ "Confidence" SG_ 1025 BMS_brickVoltage75 1;
BA_ "Confidence" SG_ 1025 BMS_brickVoltageStatus76 1;
BA_ "Confidence" SG_ 1025 BMS_brickVoltageStatus77 1;
BA_ "Confidence" SG_ 1025 BMS_brickVoltageStatus78 1;
BA_ "Confidence" SG_ 1025 BMS_brickVoltage76 1;
BA_ "Confidence" SG_ 1025 BMS_brickVoltage77 1;
BA_ "Confidence" SG_ 1025 BMS_brickVoltage78 1;
BA_ "Confidence" SG_ 1025 BMS_brickVoltageStatus79 1;
BA_ "Confidence" SG_ 1025 BMS_brickVoltageStatus80 1;
BA_ "Confidence" SG_ 1025 BMS_brickVoltageStatus81 1;
BA_ "Confidence" SG_ 1025 BMS_brickVoltage79 1;
BA_ "Confidence" SG_ 1025 BMS_brickVoltage80 1;
BA_ "Confidence" SG_ 1025 BMS_brickVoltage81 1;
BA_ "Confidence" SG_ 1025 BMS_brickVoltageStatus82 1;
BA_ "Confidence" SG_ 1025 BMS_brickVoltageStatus83 1;
BA_ "Confidence" SG_ 1025 BMS_brickVoltageStatus84 1;
BA_ "Confidence" SG_ 1025 BMS_brickVoltage82 1;
BA_ "Confidence" SG_ 1025 BMS_brickVoltage83 1;
BA_ "Confidence" SG_ 1025 BMS_brickVoltage84 1;
BA_ "Confidence" SG_ 1025 BMS_brickVoltageStatus85 1;
BA_ "Confidence" SG_ 1025 BMS_brickVoltageStatus86 1;
BA_ "Confidence" SG_ 1025 BMS_brickVoltageStatus87 1;
BA_ "Confidence" SG_ 1025 BMS_brickVoltage85 1;
BA_ "Confidence" SG_ 1025 BMS_brickVoltage86 1;
BA_ "Confidence" SG_ 1025 BMS_brickVoltage87 1;
BA_ "Confidence" SG_ 1025 BMS_brickVoltageStatus88 1;
BA_ "Confidence" SG_ 1025 BMS_brickVoltageStatus89 1;
BA_ "Confidence" SG_ 1025 BMS_brickVoltageStatus90 1;
BA_ "Confidence" SG_ 1025 BMS_brickVoltage88 1;
BA_ "Confidence" SG_ 1025 BMS_brickVoltage89 1;
BA_ "Confidence" SG_ 1025 BMS_brickVoltage90 1;
BA_ "Confidence" SG_ 1025 BMS_brickVoltageStatus91 1;
BA_ "Confidence" SG_ 1025 BMS_brickVoltageStatus92 1;
BA_ "Confidence" SG_ 1025 BMS_brickVoltageStatus93 1;
BA_ "Confidence" SG_ 1025 BMS_brickVoltage91 1;
BA_ "Confidence" SG_ 1025 BMS_brickVoltage92 1;
BA_ "Confidence" SG_ 1025 BMS_brickVoltage93 1;
BA_ "Confidence" SG_ 1025 BMS_brickVoltageStatus94 1;
BA_ "Confidence" SG_ 1025 BMS_brickVoltageStatus95 1;
BA_ "Confidence" SG_ 1025 BMS_brickVoltageStatus96 1;
BA_ "Confidence" SG_ 1025 BMS_brickVoltage94 1;
BA_ "Confidence" SG_ 1025 BMS_brickVoltage95 1;
BA_ "Confidence" SG_ 1025 BMS_brickVoltage96 1;
BA_ "Confidence" SG_ 1025 BMS_brickVoltageStatus97 1;
BA_ "Confidence" SG_ 1025 BMS_brickVoltageStatus98 1;
BA_ "Confidence" SG_ 1025 BMS_brickVoltageStatus99 1;
BA_ "Confidence" SG_ 1025 BMS_brickVoltage97 1;
BA_ "Confidence" SG_ 1025 BMS_brickVoltage98 1;
BA_ "Confidence" SG_ 1025 BMS_brickVoltage99 1;
BA_ "Confidence" SG_ 1025 BMS_brickVoltageStatus100 1;
BA_ "Confidence" SG_ 1025 BMS_brickVoltageStatus101 1;
BA_ "Confidence" SG_ 1025 BMS_brickVoltageStatus102 1;
BA_ "Confidence" SG_ 1025 BMS_brickVoltage100 1;
BA_ "Confidence" SG_ 1025 BMS_brickVoltage101 1;
BA_ "Confidence" SG_ 1025 BMS_brickVoltage102 1;
BA_ "Confidence" SG_ 1025 BMS_brickVoltageStatus103 1;
BA_ "Confidence" SG_ 1025 BMS_brickVoltageStatus104 1;
BA_ "Confidence" SG_ 1025 BMS_brickVoltageStatus105 1;
BA_ "Confidence" SG_ 1025 BMS_brickVoltage103 1;
BA_ "Confidence" SG_ 1025 BMS_brickVoltage104 1;
BA_ "Confidence" SG_ 1025 BMS_brickVoltage105 1;
BA_ "Confidence" SG_ 1025 BMS_brickVoltageStatus106 1;
BA_ "Confidence" SG_ 1025 BMS_brickVoltageStatus107 1;
BA_ "Confidence" SG_ 1025 BMS_brickVoltageStatus108 1;
BA_ "Confidence" SG_ 1025 BMS_brickVoltage106 1;
BA_ "Confidence" SG_ 1025 BMS_brickVoltage107 1;
BA_ "Confidence" SG_ 1025 BMS_brickVoltage108 1;
BA_ "Confidence" SG_ 1138 BMS_acChargePowerSample 1;
BA_ "Confidence" SG_ 1138 BMS_voltageRegCurrentTarget 1;
BA_ "Confidence" SG_ 1138 BMS_vehicleChargeDcCurrentLimit 1;
BA_ "Confidence" SG_ 1138 BMS_userChargeCurrentLimitMode 1;
BA_ "Confidence" SG_ 1138 BMS_chargeCurrentLimitMode 1;
BA_ "Confidence" SG_ 1138 BMS_timeToFinishHeatForCharge 1;
BA_ "Confidence" SG_ 1138 BMS_timeToTripPlanChargingTarget 1;
BA_ "Confidence" SG_ 722 BMS_minBusVoltage 1;
BA_ "Confidence" SG_ 722 BMS_maxBusVoltage 1;
BA_ "Confidence" SG_ 722 BMS_maxChargeCurrent 1;
BA_ "Confidence" SG_ 722 BMS_maxDischargeCurrent 1;
BA_ "Confidence" SG_ 690 BMS_nominalFullPackEnergy 1;
BA_ "Confidence" SG_ 690 BMS_nominalEnergyRemaining 1;
BA_ "Confidence" SG_ 690 BMS_idealEnergyRemaining 1;
BA_ "Confidence" SG_ 690 BMS_fullChargeComplete 1;
BA_ "Confidence" SG_ 690 BMS_energyBuffer 1;
BA_ "Confidence" SG_ 690 BMS_expectedEnergyRemaining 1;
BA_ "Confidence" SG_ 690 BMS_energyToChargeComplete 1;
BA_ "Confidence" SG_ 690 BMS_energyRemainingDisplay 1;
BA_ "Confidence" SG_ 690 BMS_energyRemainingTDisplay 1;
BA_ "Confidence" SG_ 690 BMS_energyDisplayErrorBlendRate 1;
BA_ "Confidence" SG_ 690 BMS_userFacingSoe 1;
BA_ "Confidence" SG_ 306 BMS_dcLinkVoltage 1;
BA_ "Confidence" SG_ 306 BMS_packCurrent 1;
BA_ "Confidence" SG_ 306 BMS_currentUnfiltered 1;
BA_ "Confidence" SG_ 768 BMS_buildType 1;
BA_ "Confidence" SG_ 768 BMS_pcbaId 1;
BA_ "Confidence" SG_ 768 BMS_assemblyId 1;
BA_ "Confidence" SG_ 768 BMS_usageId 1;
BA_ "Confidence" SG_ 768 BMS_subUsageId 1;
BA_ "Confidence" SG_ 978 BMS_kwhDischargeTotal 1;
BA_ "Confidence" SG_ 978 BMS_kwhChargeTotal 1;
BA_ "Confidence" SG_ 1010 BMS_acChargerKwhTotal 1;
BA_ "Confidence" SG_ 1010 BMS_dcChargerKwhTotal 1;
BA_ "Confidence" SG_ 1010 BMS_kwhRegenChargeTotal 1;
BA_ "Confidence" SG_ 1010 BMS_kwhDriveDischargeTotal 1;
BA_ "Confidence" SG_ 1010 BMS_kwhDischargeTotalModule1 1;
BA_ "Confidence" SG_ 1010 BMS_kwhChargeTotalModule1 1;
BA_ "Confidence" SG_ 1010 BMS_kwhAcChargeTotalModule1 1;
BA_ "Confidence" SG_ 1010 BMS_kwhDcChargeTotalModule1 1;
BA_ "Confidence" SG_ 1010 BMS_kwhDischargeTotalModule2 1;
BA_ "Confidence" SG_ 1010 BMS_kwhChargeTotalModule2 1;
BA_ "Confidence" SG_ 1010 BMS_kwhAcChargeTotalModule2 1;
BA_ "Confidence" SG_ 1010 BMS_kwhDcChargeTotalModule2 1;
BA_ "Confidence" SG_ 1010 BMS_kwhDischargeTotalModule3 1;
BA_ "Confidence" SG_ 1010 BMS_kwhChargeTotalModule3 1;
BA_ "Confidence" SG_ 1010 BMS_kwhAcChargeTotalModule3 1;
BA_ "Confidence" SG_ 1010 BMS_kwhDcChargeTotalModule3 1;
BA_ "Confidence" SG_ 1010 BMS_kwhDischargeTotalModule4 1;
BA_ "Confidence" SG_ 1010 BMS_kwhChargeTotalModule4 1;
BA_ "Confidence" SG_ 1010 BMS_kwhAcChargeTotalModule4 1;
BA_ "Confidence" SG_ 1010 BMS_kwhDcChargeTotalModule4 1;
BA_ "Confidence" SG_ 884 BMS_powerTransferStatus 1;
BA_ "Confidence" SG_ 884 BMS_extDcPrechargeVoltageLimit 1;
BA_ "Confidence" SG_ 884 BMS_dcChargeCurrentRequest 1;
BA_ "Confidence" SG_ 884 BMS_dcChargeCurrentLimit 1;
BA_ "Confidence" SG_ 884 BMS_dcChargeVoltageLimit 1;
BA_ "Confidence" SG_ 884 BMS_dcChargePowerLimit 1;
BA_ "Confidence" SG_ 884 BMS_acRealPowerRequest 1;
BA_ "Confidence" SG_ 884 BMS_maxExtIsoFcLinkV 1;
BA_ "Confidence" SG_ 884 BMS_energyMaxPredictedBrickTemp 1;
BA_ "Confidence" SG_ 884 BMS_energyTempGradientAtMaxTemp 1;
BA_ "Confidence" SG_ 884 BMS_energyWalkMaxSoc 1;
BA_ "Confidence" SG_ 884 BMS_energyWalkMinSoc 1;
BA_ "Confidence" SG_ 884 BMS_chargeEnergyWalkState 1;
BA_ "Confidence" SG_ 884 BMS_packVoltage 1;
BA_ "Confidence" SG_ 884 BMS_energyWalkMaxPackCurrent 1;
BA_ "Confidence" SG_ 884 BMS_energyWalkMaxVehiclePower 1;
BA_ "Confidence" SG_ 884 BMS_battTempPct 1;
BA_ "Confidence" SG_ 884 BMS_powerTransferDisableType 1;
BA_ "Confidence" SG_ 884 BMS_powerTransferDisableReason 1;
BA_ "Confidence" SG_ 884 BMS_powerTransferWaitCondition 1;
BA_ "SystemSignalLongSymbol" SG_ 946 BMS_maxChargeRestartNeededByVolt "BMS_maxChargeRestartNeededByVoltage";
BA_ "Confidence" SG_ 946 BMS_cacAvg 1;
BA_ "Confidence" SG_ 946 BMS_cacMin 1;
BA_ "Confidence" SG_ 946 BMS_cacMax 1;
BA_ "Confidence" SG_ 946 BMS_hvChain_useLeakyBucket 1;
BA_ "Confidence" SG_ 946 BMS_hvChain_iLimit 1;
BA_ "Confidence" SG_ 946 BMS_hvChain_limitingStateTempera 1;
BA_ "SystemSignalLongSymbol" SG_ 946 BMS_hvChain_limitingStateTempera "BMS_hvChain_limitingStateTemperature";
BA_ "Confidence" SG_ 946 BMS_acRippleStartTemperatureMax 1;
BA_ "Confidence" SG_ 946 BMS_acRippleStartTemperatureMin 1;
BA_ "Confidence" SG_ 946 BMS_fcLinkTestDecayTime 1;
BA_ "Confidence" SG_ 946 BMS_fcLinkTestTimeSinceLastRun 1;
BA_ "Confidence" SG_ 946 BMS_pcsPrechargeRequest 1;
BA_ "Confidence" SG_ 946 BMS_pcsPrechargeTargetVoltage 1;
BA_ "Confidence" SG_ 946 BMS_recentOvUvAlert 1;
BA_ "Confidence" SG_ 946 BMS_recentIsoAlert 1;
BA_ "Confidence" SG_ 946 BMS_recentBmbMiaAlert 1;
BA_ "Confidence" SG_ 946 BMS_cacBlendPercentPerCycle 1;
BA_ "Confidence" SG_ 946 BMS_packRestTime 1;
BA_ "Confidence" SG_ 946 BMS_idealEnergyFloor 1;
BA_ "Confidence" SG_ 946 BMS_dynamicEnergyBuffer 1;
BA_ "Confidence" SG_ 946 BMS_thmGradientSlope 1;
BA_ "Confidence" SG_ 946 BMS_thmGradient 1;
BA_ "Confidence" SG_ 946 BMS_tempVsSocTotalChgEnergy 1;
BA_ "Confidence" SG_ 946 BMS_powerVsVoltageTotalChgEnergy 1;
BA_ "SystemSignalLongSymbol" SG_ 946 BMS_lifeModelOutputsAreTrustwort "BMS_lifeModelOutputsAreTrustworthy";
BA_ "Confidence" SG_ 946 BMS_dSocNormalizedMin 1;
BA_ "Confidence" SG_ 946 BMS_dSocNormalizedFiltMin 1;
BA_ "Confidence" SG_ 946 BMS_dSocMinAlpha 1;
BA_ "Confidence" SG_ 946 BMS_dSocCacMargin 1;
BA_ "Confidence" SG_ 946 BMS_lifeModelNoCurrentStorageCap 1;
BA_ "SystemSignalLongSymbol" SG_ 946 BMS_lifeModelNoCurrentStorageCap "BMS_lifeModelNoCurrentStorageCapacityLoss";
BA_ "Confidence" SG_ 946 BMS_lifeModelShortDcr 1;
BA_ "Confidence" SG_ 946 BMS_lifeModelLongDcr 1;
BA_ "Confidence" SG_ 946 BMS_lifeModelStorageCapacityLoss 1;
BA_ "Confidence" SG_ 946 BMS_lifeModelThroughputCapacityL 1;
BA_ "SystemSignalLongSymbol" SG_ 946 BMS_lifeModelThroughputCapacityL "BMS_lifeModelThroughputCapacityLoss";
BA_ "Confidence" SG_ 946 BMS_passiveCoolCellTargetT 1;
BA_ "Confidence" SG_ 946 BMS_lifeModelAvgTempSeverity 1;
BA_ "Confidence" SG_ 946 BMS_lifeModelDepthOfDischargeSev 1;
BA_ "SystemSignalLongSymbol" SG_ 946 BMS_lifeModelDepthOfDischargeSev "BMS_lifeModelDepthOfDischargeSeverity";
BA_ "Confidence" SG_ 946 BMS_lifeModelHistogramCapacityLo 1;
BA_ "SystemSignalLongSymbol" SG_ 946 BMS_lifeModelHistogramCapacityLo "BMS_lifeModelHistogramCapacityLoss";
BA_ "Confidence" SG_ 946 BMS_lifeModelHistogramBrickCapac 1;
BA_ "SystemSignalLongSymbol" SG_ 946 BMS_lifeModelHistogramBrickCapac "BMS_lifeModelHistogramBrickCapacity";
BA_ "Confidence" SG_ 946 BMS_lifeModelDcrGrowthPercent 1;
BA_ "Confidence" SG_ 946 BMS_nominalFullPackEnergyRaw 1;
BA_ "Confidence" SG_ 946 BMS_nominalEnergyRemainingBuffer 1;
BA_ "SystemSignalLongSymbol" SG_ 946 BMS_nominalEnergyRemainingBuffer "BMS_nominalEnergyRemainingBuffered";
BA_ "Confidence" SG_ 946 BMS_idealEnergyRemainingBuffered 1;
BA_ "Confidence" SG_ 946 BMS_largestSynchronizedCacErrorP 1;
BA_ "SystemSignalLongSymbol" SG_ 946 BMS_largestSynchronizedCacErrorP "BMS_largestSynchronizedCacErrorPct";
BA_ "Confidence" SG_ 946 BMS_largestCacSpreadErrorLower 1;
BA_ "Confidence" SG_ 946 BMS_lifeModelAverageCac 1;
BA_ "Confidence" SG_ 946 BMS_lifeModelCacBrick1 1;
BA_ "Confidence" SG_ 946 BMS_lifeModelAverageOffset 1;
BA_ "Confidence" SG_ 946 BMS_percentCacUpdatesInTimeWindo 1;
BA_ "SystemSignalLongSymbol" SG_ 946 BMS_percentCacUpdatesInTimeWindo "BMS_percentCacUpdatesInTimeWindow";
BA_ "Confidence" SG_ 946 BMS_lifeModelMaxCac 1;
BA_ "Confidence" SG_ 946 BMS_lifeModelMinCac 1;
BA_ "Confidence" SG_ 946 BMS_restingPointCacAvg 1;
BA_ "Confidence" SG_ 946 BMS_cacEstimationSource 1;
BA_ "Confidence" SG_ 946 BMS_synchronizedCacMaxRaw 1;
BA_ "Confidence" SG_ 946 BMS_synchronizedCacMinRaw 1;
BA_ "Confidence" SG_ 946 BMS_largestSyncCacErrorStartSoc 1;
BA_ "Confidence" SG_ 946 BMS_largestSyncCacErrorEndSoc 1;
BA_ "Confidence" SG_ 946 BMS_rubberBandingEnabled 1;
BA_ "SystemSignalLongSymbol" SG_ 946 BMS_rubberBandingConfigNvramVali "BMS_rubberBandingConfigNvramValid";
BA_ "Confidence" SG_ 946 BMS_runtimeSocMinTempForModel 1;
BA_ "SystemSignalLongSymbol" SG_ 946 BMS_thermalEvent1pDetectConfigDi "BMS_thermalEvent1pDetectConfigDisabled";
BA_ "Confidence" SG_ 946 BMS_sohEnergy 1;
BA_ "Confidence" SG_ 946 BMS_fullCapacitySohEnergy 1;
BA_ "Confidence" SG_ 946 BMS_calibratedCapacitySohEnergy 1;
BA_ "Confidence" SG_ 946 BMS_estimatedCapacitySohEnergy 1;
BA_ "Confidence" SG_ 946 BMS_prevUserFacingSohEnergy 1;
BA_ "Confidence" SG_ 946 BMS_stateOfHealthMinCac 1;
BA_ "Confidence" SG_ 946 BMS_lifeModelStorageLossPackAge 1;
BA_ "Confidence" SG_ 946 BMS_lifeModelThroughputDcrCycleC 1;
BA_ "SystemSignalLongSymbol" SG_ 946 BMS_lifeModelThroughputDcrCycleC "BMS_lifeModelThroughputDcrCycleCount";
BA_ "Confidence" SG_ 946 BMS_stateOfHealthMinCacLowerBoun 1;
BA_ "SystemSignalLongSymbol" SG_ 946 BMS_stateOfHealthMinCacLowerBoun "BMS_stateOfHealthMinCacLowerBound";
BA_ "Confidence" SG_ 946 BMS_chargeTargetLookupSoc 1;
BA_ "Confidence" SG_ 946 BMS_stateOfHealth 1;
BA_ "Confidence" SG_ 946 BMS_avgShuntAsicCurrentOffset 1;
BA_ "SystemSignalLongSymbol" SG_ 946 BMS_cellAttributesGeneralAttribu "BMS_cellAttributesGeneralAttributes";
BA_ "SystemSignalLongSymbol" SG_ 946 BMS_cellAttributesPackManufactur "BMS_cellAttributesPackManufacturingLocation";
BA_ "SystemSignalLongSymbol" SG_ 946 BMS_cellAttributesRemanufactured "BMS_cellAttributesRemanufacturedPack";
BA_ "SystemSignalLongSymbol" SG_ 946 BMS_cellAttributesConfigNvramVal "BMS_cellAttributesConfigNvramValid";
BA_ "SystemSignalLongSymbol" SG_ 946 BMS_cellAttributesAutocloseAndSc "BMS_cellAttributesAutocloseAndScrapPackOnFieldReturn";
BA_ "SystemSignalLongSymbol" SG_ 946 BMS_cellAttributesShipPackForFai "BMS_cellAttributesShipPackForFailureAnalysis";
BA_ "Confidence" SG_ 946 BMS_lifeModelThroughputCycleCoun 1;
BA_ "SystemSignalLongSymbol" SG_ 946 BMS_lifeModelThroughputCycleCoun "BMS_lifeModelThroughputCycleCount";
BA_ "Confidence" SG_ 946 BMS_limpChargeCurrentLimit 1;
BA_ "Confidence" SG_ 946 BMS_energyRemainingDisplayError 1;
BA_ "Confidence" SG_ 946 BMS_energyRemainingTDisplayError 1;
BA_ "Confidence" SG_ 946 BMS_numOfThermistors 1;
BA_ "Confidence" SG_ 946 BMS_numOfBricks 1;
BA_ "Confidence" SG_ 946 BMS_cellChargeDcCurrentLimit 1;
BA_ "Confidence" SG_ 946 BMS_socByDvMaxSocLimit 1;
BA_ "Confidence" SG_ 946 BMS_socByDvVoltageChangeOverAh 1;
BA_ "Confidence" SG_ 946 BMS_socByDvMaxSocByAhCorrected 1;
BA_ "Confidence" SG_ 946 BMS_socByDvMaxBrickVoltage 1;
BA_ "Confidence" SG_ 946 BMS_socByDvMaxSocByAhRaw 1;
BA_ "Confidence" SG_ 946 BMS_voltageInstabilityExcessNois 1;
BA_ "SystemSignalLongSymbol" SG_ 946 BMS_voltageInstabilityExcessNois "BMS_voltageInstabilityExcessNoiseLog";
BA_ "Confidence" SG_ 946 BMS_maxModelThermistorTempDelta 1;
BA_ "Confidence" SG_ 946 BMS_activeCoolCellTargetT 1;
BA_ "Confidence" SG_ 946 BMS_cellTempTargetMode 1;
BA_ "Confidence" SG_ 946 BMS_minPackTempForChargeToStart 1;
BA_ "Confidence" SG_ 914 BMS_reservedConfig_0 1;
BA_ "Confidence" SG_ 914 BMS_moduleType 1;
BA_ "Confidence" SG_ 914 BMS_thermalPackType 1;
BA_ "Confidence" SG_ 914 BMS_packMass 1;
BA_ "Confidence" SG_ 914 BMS_platformMaxBusVoltage 1;
BA_ "Confidence" SG_ 914 BMS_standbySupplyContinuousPower 1;
BA_ "SystemSignalLongSymbol" SG_ 914 BMS_standbySupplyContinuousPower "BMS_standbySupplyContinuousPowerLimit";
BA_ "Confidence" SG_ 914 BMS_beginningOfLifePackEnergy 1;
BA_ "Confidence" SG_ 1810 BMS_packTemperatureStatus1 1;
BA_ "Confidence" SG_ 1810 BMS_packTemperatureStatus2 1;
BA_ "Confidence" SG_ 1810 BMS_packTemperatureStatus3 1;
BA_ "Confidence" SG_ 1810 BMS_packTemperature1 1;
BA_ "Confidence" SG_ 1810 BMS_packTemperature2 1;
BA_ "Confidence" SG_ 1810 BMS_packTemperature3 1;
BA_ "Confidence" SG_ 1810 BMS_packTemperatureStatus4 1;
BA_ "Confidence" SG_ 1810 BMS_packTemperatureStatus5 1;
BA_ "Confidence" SG_ 1810 BMS_packTemperatureStatus6 1;
BA_ "Confidence" SG_ 1810 BMS_packTemperature4 1;
BA_ "Confidence" SG_ 1810 BMS_packTemperature5 1;
BA_ "Confidence" SG_ 1810 BMS_packTemperature6 1;
BA_ "Confidence" SG_ 1810 BMS_packTemperatureStatus7 1;
BA_ "Confidence" SG_ 1810 BMS_packTemperatureStatus8 1;
BA_ "Confidence" SG_ 1810 BMS_packTemperatureStatus9 1;
BA_ "Confidence" SG_ 1810 BMS_packTemperature7 1;
BA_ "Confidence" SG_ 1810 BMS_packTemperature8 1;
BA_ "Confidence" SG_ 1810 BMS_packTemperature9 1;
BA_ "Confidence" SG_ 1810 BMS_packTemperatureStatus10 1;
BA_ "Confidence" SG_ 1810 BMS_packTemperatureStatus11 1;
BA_ "Confidence" SG_ 1810 BMS_packTemperatureStatus12 1;
BA_ "Confidence" SG_ 1810 BMS_packTemperature10 1;
BA_ "Confidence" SG_ 1810 BMS_packTemperature11 1;
BA_ "Confidence" SG_ 1810 BMS_packTemperature12 1;
BA_ "Confidence" SG_ 1810 BMS_packTemperatureStatus13 1;
BA_ "Confidence" SG_ 1810 BMS_packTemperatureStatus14 1;
BA_ "Confidence" SG_ 1810 BMS_packTemperatureStatus15 1;
BA_ "Confidence" SG_ 1810 BMS_packTemperature13 1;
BA_ "Confidence" SG_ 1810 BMS_packTemperature14 1;
BA_ "Confidence" SG_ 1810 BMS_packTemperature15 1;
BA_ "Confidence" SG_ 1810 BMS_packTemperatureStatus16 1;
BA_ "Confidence" SG_ 1810 BMS_packTemperatureStatus17 1;
BA_ "Confidence" SG_ 1810 BMS_packTemperatureStatus18 1;
BA_ "Confidence" SG_ 1810 BMS_packTemperature16 1;
BA_ "Confidence" SG_ 1810 BMS_packTemperature17 1;
BA_ "Confidence" SG_ 1810 BMS_packTemperature18 1;
BA_ "Confidence" SG_ 594 BMS_maxRegenPower 1;
BA_ "Confidence" SG_ 594 BMS_maxDischargePower 1;
BA_ "Confidence" SG_ 594 BMS_maxStationaryHeatPower 1;
BA_ "Confidence" SG_ 594 BMS_powerLimitsState 1;
BA_ "Confidence" SG_ 594 BMS_totalHvPowerBudget 1;
BA_ "Confidence" SG_ 594 BMS_notEnoughPowerForHeatPump 1;
BA_ "Confidence" SG_ 674 BMS_acRippleCurrentAmplitudeLimi 1;
BA_ "SystemSignalLongSymbol" SG_ 674 BMS_acRippleCurrentAmplitudeLimi "BMS_acRippleCurrentAmplitudeLimit";
BA_ "Confidence" SG_ 674 BMS_acRippleMaxVoltageLimit 1;
BA_ "Confidence" SG_ 674 BMS_acRippleMinVoltageLimit 1;
BA_ "Confidence" SG_ 674 BMS_acRippleFrequencyRequest 1;
BA_ "Confidence" SG_ 674 BMS_acRippleCurrentAmplitudeRequ 1;
BA_ "SystemSignalLongSymbol" SG_ 674 BMS_acRippleCurrentAmplitudeRequ "BMS_acRippleCurrentAmplitudeRequest";
BA_ "Confidence" SG_ 674 BMS_acRippleRequest 1;
BA_ "Confidence" SG_ 658 BMS_socMin 1;
BA_ "Confidence" SG_ 658 BMS_socUI 1;
BA_ "Confidence" SG_ 658 BMS_socMax 1;
BA_ "Confidence" SG_ 658 BMS_socAvg 1;
BA_ "Confidence" SG_ 658 BMS_enoughEnergyForConvenienceFe 1;
BA_ "SystemSignalLongSymbol" SG_ 658 BMS_enoughEnergyForConvenienceFe "BMS_enoughEnergyForConvenienceFeatures";
BA_ "Confidence" SG_ 658 BMS_instantChargePowerCapability 1;
BA_ "Confidence" SG_ 1170 BMS_sohEnergyPercent 1;
BA_ "Confidence" SG_ 1170 BMS_userFacingSohTestState 1;
BA_ "Confidence" SG_ 1170 BMS_userFacingSohTestEndMode 1;
BA_ "Confidence" SG_ 1170 BMS_timeSinceSohUpdate 1;
BA_ "Confidence" SG_ 1170 BMS_sohTestCycleFlag 1;
BA_ "Confidence" SG_ 1170 BMS_calibratedSohAvailable 1;
BA_ "Confidence" SG_ 1170 BMS_requiredEvsePowerForSoh 1;
BA_ "Confidence" SG_ 1170 BMS_distanceSinceSohUpdate 1;
BA_ "Confidence" SG_ 530 BMS_notEnoughPowerForDrive 1;
BA_ "Confidence" SG_ 530 BMS_notEnoughPowerForSupport 1;
BA_ "Confidence" SG_ 530 BMS_cpMiaOnHvs 1;
BA_ "Confidence" SG_ 530 BMS_pcsPwmEnabled 1;
BA_ "Confidence" SG_ 530 BMS_contactorState 1;
BA_ "Confidence" SG_ 530 BMS_userChargeStatus 1;
BA_ "Confidence" SG_ 530 BMS_batteryInputPower 1;
BA_ "Confidence" SG_ 530 BMS_chargeRequest 1;
BA_ "Confidence" SG_ 530 BMS_state 1;
BA_ "Confidence" SG_ 530 BMS_diLimpRequest 1;
BA_ "Confidence" SG_ 530 BMS_chgPowerAvailable 1;
BA_ "Confidence" SG_ 530 BMS_acManagerState 1;
BA_ "Confidence" SG_ 530 BMS_conditioningRequest 1;
BA_ "Confidence" SG_ 530 BMS_smStateRequest 1;
BA_ "Confidence" SG_ 530 BMS_hvState 1;
BA_ "Confidence" SG_ 786 BMS_inletActiveCoolTargetT 1;
BA_ "Confidence" SG_ 786 BMS_inletPassiveTargetT 1;
BA_ "Confidence" SG_ 786 BMS_inletActiveHeatTargetT 1;
BA_ "Confidence" SG_ 786 BMS_requestDischarge 1;
BA_ "Confidence" SG_ 786 BMS_activeHeatingWorthwhile 1;
BA_ "Confidence" SG_ 786 BMS_minPackTemperature 1;
BA_ "Confidence" SG_ 786 BMS_maxPackTemperature 1;
BA_ "Confidence" SG_ 786 BMS_flowRequest 1;
BA_ "Confidence" SG_ 786 BMS_coldStagnationLimit 1;
BA_ "Confidence" SG_ 786 BMS_hotStagnationLimit 1;
BA_ "Confidence" SG_ 786 BMS_hotCellTempLimit 1;
BA_ "Confidence" SG_ 786 BMS_activeCoolCellReferenceT 1;
BA_ "Confidence" SG_ 786 BMS_activeHeatCellTargetT 1;
BA_ "Confidence" SG_ 786 BMS_powerDissipation 1;
BA_ "Confidence" SG_ 1071 BMS_v2xSoe 1;
BA_ "Confidence" SG_ 1071 BMS_v2xFullEnergy 1;
BA_ "Confidence" SG_ 1071 BMS_v2xPackPower 1;
BA_ "Confidence" SG_ 1071 BMS_acDischargeBlockedReason 1;
BA_ "Confidence" SG_ 1071 BMS_backupTimeRemaining 1;
BA_ "Confidence" SG_ 754 BMS_hvsBusAsleep 1;
BA_ "Confidence" SG_ 754 BMS_nmKeepAwakeReason 1;
BA_ "Confidence" SG_ 754 BMS_nmWakeUpReason 1;
BA_ "Confidence" SG_ 810 BMS_thermalEventSuspected 1;
BA_ "Confidence" SG_ 810 BMS_isolationResistance 1;
BA_ "Confidence" SG_ 810 BMS_chgTimeToFull 1;
BA_ "SystemSignalLongSymbol" SG_ 1132 CC_a037_internalModuleWatchdogEx "CC_a037_internalModuleWatchdogExpired";
BA_ "SystemSignalLongSymbol" SG_ 1132 CC_a044_relayCoilVoltageRational "CC_a044_relayCoilVoltageRationality";
BA_ "Confidence" SG_ 796 CC_currentLimit 1;
BA_ "Confidence" SG_ 796 CC_pilotState 1;
BA_ "Confidence" SG_ 796 CC_numPhases 1;
BA_ "Confidence" SG_ 796 CC_line1Voltage 1;
BA_ "Confidence" SG_ 796 CC_gridGrounding 1;
BA_ "Confidence" SG_ 796 CC_deltaTransformer 1;
BA_ "Confidence" SG_ 796 CC_numVehCharging 1;
BA_ "Confidence" SG_ 796 CC_line2Voltage 1;
BA_ "Confidence" SG_ 796 CC_line3Voltage 1;
BA_ "Confidence" SG_ 796 CC_groundResistance 1;
BA_ "Confidence" SG_ 797 CC_buttonState 1;
BA_ "Confidence" SG_ 797 EVSE_v2xSupport 1;
BA_ "Confidence" SG_ 812 CC_activeConnectorID 1;
BA_ "Confidence" SG_ 812 CC_temperature1 1;
BA_ "Confidence" SG_ 812 CC_temperature2 1;
BA_ "Confidence" SG_ 812 CC_temperature3 1;
BA_ "Confidence" SG_ 812 CC_contactor1Closed 1;
BA_ "Confidence" SG_ 812 CC_contactor2Closed 1;
BA_ "Confidence" SG_ 812 CC_temperature4 1;
BA_ "Confidence" SG_ 812 CC_conn1Current 1;
BA_ "Confidence" SG_ 812 CC_conn2Current 1;
BA_ "Confidence" SG_ 812 CC_conn3Current 1;
BA_ "Confidence" SG_ 812 CC_conn4Current 1;
BA_ "Confidence" SG_ 812 CC_lifetimei2t 1;
BA_ "Confidence" SG_ 812 CC_lifetimeAvgStartupTemp 1;
BA_ "Confidence" SG_ 870 CMPD_infoBuildType 1;
BA_ "Confidence" SG_ 680 CMPD_speedRPM 1;
BA_ "Confidence" SG_ 680 CMPD_speedDuty 1;
BA_ "Confidence" SG_ 680 CMPD_inputHVPower 1;
BA_ "Confidence" SG_ 680 CMPD_inputHVCurrent 1;
BA_ "Confidence" SG_ 680 CMPD_inputHVVoltage 1;
BA_ "Confidence" SG_ 680 CMPD_2ShuntModeActive 1;
BA_ "Confidence" SG_ 680 CMPD_powerLimitActive 1;
BA_ "Confidence" SG_ 680 CMPD_state 1;
BA_ "Confidence" SG_ 680 CMPD_wasteHeatState 1;
BA_ "Confidence" SG_ 680 CMPD_powerLimitTooLowToStart 1;
BA_ "Confidence" SG_ 680 CMPD_ready 1;
BA_ "Confidence" SG_ 551 CMP_inputHVVoltage 1;
BA_ "Confidence" SG_ 551 CMP_inputLVVoltage 1;
BA_ "Confidence" SG_ 551 CMP_inputHVCurrent 1;
BA_ "Confidence" SG_ 551 CMP_inputHVPower 1;
BA_ "Confidence" SG_ 867 CMP_infoBuildType 1;
VAL_ 1025 BMS_brickVoltageStatus1 3 "SENSOR_BYPASSED" 2 "SENSOR_NOMINAL" 1 "SENSOR_BAD" 0 "SENSOR_MISSING" ;
VAL_ 1025 BMS_brickVoltageStatus2 3 "SENSOR_BYPASSED" 2 "SENSOR_NOMINAL" 1 "SENSOR_BAD" 0 "SENSOR_MISSING" ;
VAL_ 1025 BMS_brickVoltageStatus3 3 "SENSOR_BYPASSED" 2 "SENSOR_NOMINAL" 1 "SENSOR_BAD" 0 "SENSOR_MISSING" ;
VAL_ 1025 BMS_brickVoltageStatus4 3 "SENSOR_BYPASSED" 2 "SENSOR_NOMINAL" 1 "SENSOR_BAD" 0 "SENSOR_MISSING" ;
VAL_ 1025 BMS_brickVoltageStatus5 3 "SENSOR_BYPASSED" 2 "SENSOR_NOMINAL" 1 "SENSOR_BAD" 0 "SENSOR_MISSING" ;
VAL_ 1025 BMS_brickVoltageStatus6 3 "SENSOR_BYPASSED" 2 "SENSOR_NOMINAL" 1 "SENSOR_BAD" 0 "SENSOR_MISSING" ;
VAL_ 1025 BMS_brickVoltageStatus7 3 "SENSOR_BYPASSED" 2 "SENSOR_NOMINAL" 1 "SENSOR_BAD" 0 "SENSOR_MISSING" ;
VAL_ 1025 BMS_brickVoltageStatus8 3 "SENSOR_BYPASSED" 2 "SENSOR_NOMINAL" 1 "SENSOR_BAD" 0 "SENSOR_MISSING" ;
VAL_ 1025 BMS_brickVoltageStatus9 3 "SENSOR_BYPASSED" 2 "SENSOR_NOMINAL" 1 "SENSOR_BAD" 0 "SENSOR_MISSING" ;
VAL_ 1025 BMS_brickVoltageStatus10 3 "SENSOR_BYPASSED" 2 "SENSOR_NOMINAL" 1 "SENSOR_BAD" 0 "SENSOR_MISSING" ;
VAL_ 1025 BMS_brickVoltageStatus11 3 "SENSOR_BYPASSED" 2 "SENSOR_NOMINAL" 1 "SENSOR_BAD" 0 "SENSOR_MISSING" ;
VAL_ 1025 BMS_brickVoltageStatus12 3 "SENSOR_BYPASSED" 2 "SENSOR_NOMINAL" 1 "SENSOR_BAD" 0 "SENSOR_MISSING" ;
VAL_ 1025 BMS_brickVoltageStatus13 3 "SENSOR_BYPASSED" 2 "SENSOR_NOMINAL" 1 "SENSOR_BAD" 0 "SENSOR_MISSING" ;
VAL_ 1025 BMS_brickVoltageStatus14 3 "SENSOR_BYPASSED" 2 "SENSOR_NOMINAL" 1 "SENSOR_BAD" 0 "SENSOR_MISSING" ;
VAL_ 1025 BMS_brickVoltageStatus15 3 "SENSOR_BYPASSED" 2 "SENSOR_NOMINAL" 1 "SENSOR_BAD" 0 "SENSOR_MISSING" ;
VAL_ 1025 BMS_brickVoltageStatus16 3 "SENSOR_BYPASSED" 2 "SENSOR_NOMINAL" 1 "SENSOR_BAD" 0 "SENSOR_MISSING" ;
VAL_ 1025 BMS_brickVoltageStatus17 3 "SENSOR_BYPASSED" 2 "SENSOR_NOMINAL" 1 "SENSOR_BAD" 0 "SENSOR_MISSING" ;
VAL_ 1025 BMS_brickVoltageStatus18 3 "SENSOR_BYPASSED" 2 "SENSOR_NOMINAL" 1 "SENSOR_BAD" 0 "SENSOR_MISSING" ;
VAL_ 1025 BMS_brickVoltageStatus19 3 "SENSOR_BYPASSED" 2 "SENSOR_NOMINAL" 1 "SENSOR_BAD" 0 "SENSOR_MISSING" ;
VAL_ 1025 BMS_brickVoltageStatus20 3 "SENSOR_BYPASSED" 2 "SENSOR_NOMINAL" 1 "SENSOR_BAD" 0 "SENSOR_MISSING" ;
VAL_ 1025 BMS_brickVoltageStatus21 3 "SENSOR_BYPASSED" 2 "SENSOR_NOMINAL" 1 "SENSOR_BAD" 0 "SENSOR_MISSING" ;
VAL_ 1025 BMS_brickVoltageStatus22 3 "SENSOR_BYPASSED" 2 "SENSOR_NOMINAL" 1 "SENSOR_BAD" 0 "SENSOR_MISSING" ;
VAL_ 1025 BMS_brickVoltageStatus23 3 "SENSOR_BYPASSED" 2 "SENSOR_NOMINAL" 1 "SENSOR_BAD" 0 "SENSOR_MISSING" ;
VAL_ 1025 BMS_brickVoltageStatus24 3 "SENSOR_BYPASSED" 2 "SENSOR_NOMINAL" 1 "SENSOR_BAD" 0 "SENSOR_MISSING" ;
VAL_ 1025 BMS_brickVoltageStatus25 3 "SENSOR_BYPASSED" 2 "SENSOR_NOMINAL" 1 "SENSOR_BAD" 0 "SENSOR_MISSING" ;
VAL_ 1025 BMS_brickVoltageStatus26 3 "SENSOR_BYPASSED" 2 "SENSOR_NOMINAL" 1 "SENSOR_BAD" 0 "SENSOR_MISSING" ;
VAL_ 1025 BMS_brickVoltageStatus27 3 "SENSOR_BYPASSED" 2 "SENSOR_NOMINAL" 1 "SENSOR_BAD" 0 "SENSOR_MISSING" ;
VAL_ 1025 BMS_brickVoltageStatus28 3 "SENSOR_BYPASSED" 2 "SENSOR_NOMINAL" 1 "SENSOR_BAD" 0 "SENSOR_MISSING" ;
VAL_ 1025 BMS_brickVoltageStatus29 3 "SENSOR_BYPASSED" 2 "SENSOR_NOMINAL" 1 "SENSOR_BAD" 0 "SENSOR_MISSING" ;
VAL_ 1025 BMS_brickVoltageStatus30 3 "SENSOR_BYPASSED" 2 "SENSOR_NOMINAL" 1 "SENSOR_BAD" 0 "SENSOR_MISSING" ;
VAL_ 1025 BMS_brickVoltageStatus31 3 "SENSOR_BYPASSED" 2 "SENSOR_NOMINAL" 1 "SENSOR_BAD" 0 "SENSOR_MISSING" ;
VAL_ 1025 BMS_brickVoltageStatus32 3 "SENSOR_BYPASSED" 2 "SENSOR_NOMINAL" 1 "SENSOR_BAD" 0 "SENSOR_MISSING" ;
VAL_ 1025 BMS_brickVoltageStatus33 3 "SENSOR_BYPASSED" 2 "SENSOR_NOMINAL" 1 "SENSOR_BAD" 0 "SENSOR_MISSING" ;
VAL_ 1025 BMS_brickVoltageStatus34 3 "SENSOR_BYPASSED" 2 "SENSOR_NOMINAL" 1 "SENSOR_BAD" 0 "SENSOR_MISSING" ;
VAL_ 1025 BMS_brickVoltageStatus35 3 "SENSOR_BYPASSED" 2 "SENSOR_NOMINAL" 1 "SENSOR_BAD" 0 "SENSOR_MISSING" ;
VAL_ 1025 BMS_brickVoltageStatus36 3 "SENSOR_BYPASSED" 2 "SENSOR_NOMINAL" 1 "SENSOR_BAD" 0 "SENSOR_MISSING" ;
VAL_ 1025 BMS_brickVoltageStatus37 3 "SENSOR_BYPASSED" 2 "SENSOR_NOMINAL" 1 "SENSOR_BAD" 0 "SENSOR_MISSING" ;
VAL_ 1025 BMS_brickVoltageStatus38 3 "SENSOR_BYPASSED" 2 "SENSOR_NOMINAL" 1 "SENSOR_BAD" 0 "SENSOR_MISSING" ;
VAL_ 1025 BMS_brickVoltageStatus39 3 "SENSOR_BYPASSED" 2 "SENSOR_NOMINAL" 1 "SENSOR_BAD" 0 "SENSOR_MISSING" ;
VAL_ 1025 BMS_brickVoltageStatus40 3 "SENSOR_BYPASSED" 2 "SENSOR_NOMINAL" 1 "SENSOR_BAD" 0 "SENSOR_MISSING" ;
VAL_ 1025 BMS_brickVoltageStatus41 3 "SENSOR_BYPASSED" 2 "SENSOR_NOMINAL" 1 "SENSOR_BAD" 0 "SENSOR_MISSING" ;
VAL_ 1025 BMS_brickVoltageStatus42 3 "SENSOR_BYPASSED" 2 "SENSOR_NOMINAL" 1 "SENSOR_BAD" 0 "SENSOR_MISSING" ;
VAL_ 1025 BMS_brickVoltageStatus43 3 "SENSOR_BYPASSED" 2 "SENSOR_NOMINAL" 1 "SENSOR_BAD" 0 "SENSOR_MISSING" ;
VAL_ 1025 BMS_brickVoltageStatus44 3 "SENSOR_BYPASSED" 2 "SENSOR_NOMINAL" 1 "SENSOR_BAD" 0 "SENSOR_MISSING" ;
VAL_ 1025 BMS_brickVoltageStatus45 3 "SENSOR_BYPASSED" 2 "SENSOR_NOMINAL" 1 "SENSOR_BAD" 0 "SENSOR_MISSING" ;
VAL_ 1025 BMS_brickVoltageStatus46 3 "SENSOR_BYPASSED" 2 "SENSOR_NOMINAL" 1 "SENSOR_BAD" 0 "SENSOR_MISSING" ;
VAL_ 1025 BMS_brickVoltageStatus47 3 "SENSOR_BYPASSED" 2 "SENSOR_NOMINAL" 1 "SENSOR_BAD" 0 "SENSOR_MISSING" ;
VAL_ 1025 BMS_brickVoltageStatus48 3 "SENSOR_BYPASSED" 2 "SENSOR_NOMINAL" 1 "SENSOR_BAD" 0 "SENSOR_MISSING" ;
VAL_ 1025 BMS_brickVoltageStatus49 3 "SENSOR_BYPASSED" 2 "SENSOR_NOMINAL" 1 "SENSOR_BAD" 0 "SENSOR_MISSING" ;
VAL_ 1025 BMS_brickVoltageStatus50 3 "SENSOR_BYPASSED" 2 "SENSOR_NOMINAL" 1 "SENSOR_BAD" 0 "SENSOR_MISSING" ;
VAL_ 1025 BMS_brickVoltageStatus51 3 "SENSOR_BYPASSED" 2 "SENSOR_NOMINAL" 1 "SENSOR_BAD" 0 "SENSOR_MISSING" ;
VAL_ 1025 BMS_brickVoltageStatus52 3 "SENSOR_BYPASSED" 2 "SENSOR_NOMINAL" 1 "SENSOR_BAD" 0 "SENSOR_MISSING" ;
VAL_ 1025 BMS_brickVoltageStatus53 3 "SENSOR_BYPASSED" 2 "SENSOR_NOMINAL" 1 "SENSOR_BAD" 0 "SENSOR_MISSING" ;
VAL_ 1025 BMS_brickVoltageStatus54 3 "SENSOR_BYPASSED" 2 "SENSOR_NOMINAL" 1 "SENSOR_BAD" 0 "SENSOR_MISSING" ;
VAL_ 1025 BMS_brickVoltageStatus55 3 "SENSOR_BYPASSED" 2 "SENSOR_NOMINAL" 1 "SENSOR_BAD" 0 "SENSOR_MISSING" ;
VAL_ 1025 BMS_brickVoltageStatus56 3 "SENSOR_BYPASSED" 2 "SENSOR_NOMINAL" 1 "SENSOR_BAD" 0 "SENSOR_MISSING" ;
VAL_ 1025 BMS_brickVoltageStatus57 3 "SENSOR_BYPASSED" 2 "SENSOR_NOMINAL" 1 "SENSOR_BAD" 0 "SENSOR_MISSING" ;
VAL_ 1025 BMS_brickVoltageStatus58 3 "SENSOR_BYPASSED" 2 "SENSOR_NOMINAL" 1 "SENSOR_BAD" 0 "SENSOR_MISSING" ;
VAL_ 1025 BMS_brickVoltageStatus59 3 "SENSOR_BYPASSED" 2 "SENSOR_NOMINAL" 1 "SENSOR_BAD" 0 "SENSOR_MISSING" ;
VAL_ 1025 BMS_brickVoltageStatus60 3 "SENSOR_BYPASSED" 2 "SENSOR_NOMINAL" 1 "SENSOR_BAD" 0 "SENSOR_MISSING" ;
VAL_ 1025 BMS_brickVoltageStatus61 3 "SENSOR_BYPASSED" 2 "SENSOR_NOMINAL" 1 "SENSOR_BAD" 0 "SENSOR_MISSING" ;
VAL_ 1025 BMS_brickVoltageStatus62 3 "SENSOR_BYPASSED" 2 "SENSOR_NOMINAL" 1 "SENSOR_BAD" 0 "SENSOR_MISSING" ;
VAL_ 1025 BMS_brickVoltageStatus63 3 "SENSOR_BYPASSED" 2 "SENSOR_NOMINAL" 1 "SENSOR_BAD" 0 "SENSOR_MISSING" ;
VAL_ 1025 BMS_brickVoltageStatus64 3 "SENSOR_BYPASSED" 2 "SENSOR_NOMINAL" 1 "SENSOR_BAD" 0 "SENSOR_MISSING" ;
VAL_ 1025 BMS_brickVoltageStatus65 3 "SENSOR_BYPASSED" 2 "SENSOR_NOMINAL" 1 "SENSOR_BAD" 0 "SENSOR_MISSING" ;
VAL_ 1025 BMS_brickVoltageStatus66 3 "SENSOR_BYPASSED" 2 "SENSOR_NOMINAL" 1 "SENSOR_BAD" 0 "SENSOR_MISSING" ;
VAL_ 1025 BMS_brickVoltageStatus67 3 "SENSOR_BYPASSED" 2 "SENSOR_NOMINAL" 1 "SENSOR_BAD" 0 "SENSOR_MISSING" ;
VAL_ 1025 BMS_brickVoltageStatus68 3 "SENSOR_BYPASSED" 2 "SENSOR_NOMINAL" 1 "SENSOR_BAD" 0 "SENSOR_MISSING" ;
VAL_ 1025 BMS_brickVoltageStatus69 3 "SENSOR_BYPASSED" 2 "SENSOR_NOMINAL" 1 "SENSOR_BAD" 0 "SENSOR_MISSING" ;
VAL_ 1025 BMS_brickVoltageStatus70 3 "SENSOR_BYPASSED" 2 "SENSOR_NOMINAL" 1 "SENSOR_BAD" 0 "SENSOR_MISSING" ;
VAL_ 1025 BMS_brickVoltageStatus71 3 "SENSOR_BYPASSED" 2 "SENSOR_NOMINAL" 1 "SENSOR_BAD" 0 "SENSOR_MISSING" ;
VAL_ 1025 BMS_brickVoltageStatus72 3 "SENSOR_BYPASSED" 2 "SENSOR_NOMINAL" 1 "SENSOR_BAD" 0 "SENSOR_MISSING" ;
VAL_ 1025 BMS_brickVoltageStatus73 3 "SENSOR_BYPASSED" 2 "SENSOR_NOMINAL" 1 "SENSOR_BAD" 0 "SENSOR_MISSING" ;
VAL_ 1025 BMS_brickVoltageStatus74 3 "SENSOR_BYPASSED" 2 "SENSOR_NOMINAL" 1 "SENSOR_BAD" 0 "SENSOR_MISSING" ;
VAL_ 1025 BMS_brickVoltageStatus75 3 "SENSOR_BYPASSED" 2 "SENSOR_NOMINAL" 1 "SENSOR_BAD" 0 "SENSOR_MISSING" ;
VAL_ 1025 BMS_brickVoltageStatus76 3 "SENSOR_BYPASSED" 2 "SENSOR_NOMINAL" 1 "SENSOR_BAD" 0 "SENSOR_MISSING" ;
VAL_ 1025 BMS_brickVoltageStatus77 3 "SENSOR_BYPASSED" 2 "SENSOR_NOMINAL" 1 "SENSOR_BAD" 0 "SENSOR_MISSING" ;
VAL_ 1025 BMS_brickVoltageStatus78 3 "SENSOR_BYPASSED" 2 "SENSOR_NOMINAL" 1 "SENSOR_BAD" 0 "SENSOR_MISSING" ;
VAL_ 1025 BMS_brickVoltageStatus79 3 "SENSOR_BYPASSED" 2 "SENSOR_NOMINAL" 1 "SENSOR_BAD" 0 "SENSOR_MISSING" ;
VAL_ 1025 BMS_brickVoltageStatus80 3 "SENSOR_BYPASSED" 2 "SENSOR_NOMINAL" 1 "SENSOR_BAD" 0 "SENSOR_MISSING" ;
VAL_ 1025 BMS_brickVoltageStatus81 3 "SENSOR_BYPASSED" 2 "SENSOR_NOMINAL" 1 "SENSOR_BAD" 0 "SENSOR_MISSING" ;
VAL_ 1025 BMS_brickVoltageStatus82 3 "SENSOR_BYPASSED" 2 "SENSOR_NOMINAL" 1 "SENSOR_BAD" 0 "SENSOR_MISSING" ;
VAL_ 1025 BMS_brickVoltageStatus83 3 "SENSOR_BYPASSED" 2 "SENSOR_NOMINAL" 1 "SENSOR_BAD" 0 "SENSOR_MISSING" ;
VAL_ 1025 BMS_brickVoltageStatus84 3 "SENSOR_BYPASSED" 2 "SENSOR_NOMINAL" 1 "SENSOR_BAD" 0 "SENSOR_MISSING" ;
VAL_ 1025 BMS_brickVoltageStatus85 3 "SENSOR_BYPASSED" 2 "SENSOR_NOMINAL" 1 "SENSOR_BAD" 0 "SENSOR_MISSING" ;
VAL_ 1025 BMS_brickVoltageStatus86 3 "SENSOR_BYPASSED" 2 "SENSOR_NOMINAL" 1 "SENSOR_BAD" 0 "SENSOR_MISSING" ;
VAL_ 1025 BMS_brickVoltageStatus87 3 "SENSOR_BYPASSED" 2 "SENSOR_NOMINAL" 1 "SENSOR_BAD" 0 "SENSOR_MISSING" ;
VAL_ 1025 BMS_brickVoltageStatus88 3 "SENSOR_BYPASSED" 2 "SENSOR_NOMINAL" 1 "SENSOR_BAD" 0 "SENSOR_MISSING" ;
VAL_ 1025 BMS_brickVoltageStatus89 3 "SENSOR_BYPASSED" 2 "SENSOR_NOMINAL" 1 "SENSOR_BAD" 0 "SENSOR_MISSING" ;
VAL_ 1025 BMS_brickVoltageStatus90 3 "SENSOR_BYPASSED" 2 "SENSOR_NOMINAL" 1 "SENSOR_BAD" 0 "SENSOR_MISSING" ;
VAL_ 1025 BMS_brickVoltageStatus91 3 "SENSOR_BYPASSED" 2 "SENSOR_NOMINAL" 1 "SENSOR_BAD" 0 "SENSOR_MISSING" ;
VAL_ 1025 BMS_brickVoltageStatus92 3 "SENSOR_BYPASSED" 2 "SENSOR_NOMINAL" 1 "SENSOR_BAD" 0 "SENSOR_MISSING" ;
VAL_ 1025 BMS_brickVoltageStatus93 3 "SENSOR_BYPASSED" 2 "SENSOR_NOMINAL" 1 "SENSOR_BAD" 0 "SENSOR_MISSING" ;
VAL_ 1025 BMS_brickVoltageStatus94 3 "SENSOR_BYPASSED" 2 "SENSOR_NOMINAL" 1 "SENSOR_BAD" 0 "SENSOR_MISSING" ;
VAL_ 1025 BMS_brickVoltageStatus95 3 "SENSOR_BYPASSED" 2 "SENSOR_NOMINAL" 1 "SENSOR_BAD" 0 "SENSOR_MISSING" ;
VAL_ 1025 BMS_brickVoltageStatus96 3 "SENSOR_BYPASSED" 2 "SENSOR_NOMINAL" 1 "SENSOR_BAD" 0 "SENSOR_MISSING" ;
VAL_ 1025 BMS_brickVoltageStatus97 3 "SENSOR_BYPASSED" 2 "SENSOR_NOMINAL" 1 "SENSOR_BAD" 0 "SENSOR_MISSING" ;
VAL_ 1025 BMS_brickVoltageStatus98 3 "SENSOR_BYPASSED" 2 "SENSOR_NOMINAL" 1 "SENSOR_BAD" 0 "SENSOR_MISSING" ;
VAL_ 1025 BMS_brickVoltageStatus99 3 "SENSOR_BYPASSED" 2 "SENSOR_NOMINAL" 1 "SENSOR_BAD" 0 "SENSOR_MISSING" ;
VAL_ 1025 BMS_brickVoltageStatus100 3 "SENSOR_BYPASSED" 2 "SENSOR_NOMINAL" 1 "SENSOR_BAD" 0 "SENSOR_MISSING" ;
VAL_ 1025 BMS_brickVoltageStatus101 3 "SENSOR_BYPASSED" 2 "SENSOR_NOMINAL" 1 "SENSOR_BAD" 0 "SENSOR_MISSING" ;
VAL_ 1025 BMS_brickVoltageStatus102 3 "SENSOR_BYPASSED" 2 "SENSOR_NOMINAL" 1 "SENSOR_BAD" 0 "SENSOR_MISSING" ;
VAL_ 1025 BMS_brickVoltageStatus103 3 "SENSOR_BYPASSED" 2 "SENSOR_NOMINAL" 1 "SENSOR_BAD" 0 "SENSOR_MISSING" ;
VAL_ 1025 BMS_brickVoltageStatus104 3 "SENSOR_BYPASSED" 2 "SENSOR_NOMINAL" 1 "SENSOR_BAD" 0 "SENSOR_MISSING" ;
VAL_ 1025 BMS_brickVoltageStatus105 3 "SENSOR_BYPASSED" 2 "SENSOR_NOMINAL" 1 "SENSOR_BAD" 0 "SENSOR_MISSING" ;
VAL_ 1025 BMS_brickVoltageStatus106 3 "SENSOR_BYPASSED" 2 "SENSOR_NOMINAL" 1 "SENSOR_BAD" 0 "SENSOR_MISSING" ;
VAL_ 1025 BMS_brickVoltageStatus107 3 "SENSOR_BYPASSED" 2 "SENSOR_NOMINAL" 1 "SENSOR_BAD" 0 "SENSOR_MISSING" ;
VAL_ 1025 BMS_brickVoltageStatus108 3 "SENSOR_BYPASSED" 2 "SENSOR_NOMINAL" 1 "SENSOR_BAD" 0 "SENSOR_MISSING" ;
VAL_ 1138 BMS_userChargeCurrentLimitMode 4 "USR_CHG_LIMIT_EVSE_RELOCATION_RECOMMENDED" 3 "USR_CHG_LIMIT_HIGH_SOC" 2 "USR_CHG_LIMIT_BATT_TEMP_LOW" 1 "USR_CHG_LIMIT_EVSE" 0 "USR_CHG_LIMIT_NONE" ;
VAL_ 1138 BMS_chargeCurrentLimitMode 20 "CHG_LIMIT_RIPPLE_HEAT_ACTIVE" 19 "CHG_LIMIT_NEAR_HWOT_LIMIT" 18 "CHG_LIMIT_LIMP_MODE" 17 "CHG_LIMIT_MISSING_CELL" 16 "CHG_LIMIT_CAC_IMBALANCE" 15 "CHG_LIMIT_PCS_IMPLICIT" 14 "CHG_LIMIT_EVSE_IMPLICIT" 13 "CHG_LIMIT_RAMP_UP_PHASE" 12 "CHG_LIMIT_HVAC_COOLING" 11 "CHG_LIMIT_HV_CHAIN" 10 "CHG_LIMIT_CONFIG" 9 "CHG_LIMIT_TETHERING" 8 "CHG_LIMIT_LEAKY_BUCKET" 7 "CHG_LIMIT_BRICK_VOLTAGE_REG" 6 "CHG_LIMIT_BRICK_TEMP_TOO_COLD" 5 "CHG_LIMIT_BRICK_TEMP_TOO_HOT" 4 "CHG_LIMIT_BRICK_TEMP_OPTIMAL_CELL_PROFILE" 3 "CHG_LIMIT_CP" 2 "CHG_LIMIT_PCS" 1 "CHG_LIMIT_EVSE" 0 "CHG_LIMIT_NONE" ;
VAL_ 768 BMS_buildType 4 "INFO_MFG_BUILD" 3 "INFO_TRACEABLE_CI_BUILD" 2 "INFO_LOCAL_BUILD" 1 "INFO_PLATFORM_BUILD" 0 "INFO_UNKNOWN_BUILD" ;
VAL_ 884 BMS_powerTransferStatus 8 "BMS_POWER_TRANSFER_BLOCKED" 7 "BMS_POWER_TRANSFER_FAULTED" 6 "BMS_EMERGENCY_SHUTDOWN" 5 "BMS_GRACEFUL_SHUTDOWN" 4 "BMS_POWER_TRANSFER_ENABLED" 3 "BMS_POWER_TRANSFER_ENABLING" 2 "BMS_EXT_PRECHARGE_ALLOWED" 1 "BMS_EXT_EVSE_TEST_ALLOWED" 0 "BMS_POWER_TRANSFER_STANDBY" ;
VAL_ 884 BMS_chargeEnergyWalkState 3 "ENERGY_WALK_STOPPED" 2 "ENERGY_WALK_COMPLETE" 1 "ENERGY_WALK_RUNNING" 0 "ENERGY_WALK_INIT" ;
VAL_ 884 BMS_powerTransferDisableType 3 "FAULTED" 2 "ABORTED" 1 "CANCELED" 0 "NONE" ;
VAL_ 884 BMS_powerTransferDisableReason 41 "PRECHARGE_NOT_COMPLETE" 40 "EVSE_OUTPUT_CURRENT_NOT_LOW" 39 "ALL_RETRIES_EXHAUSTED" 38 "TEMP_TOO_LOW" 37 "FEATURE_DISABLED" 36 "SOE_TOO_LOW" 35 "AC_RELAYS_NOT_OPEN" 34 "PCS_NOT_DISABLED" 33 "CP_INLET_STILL_ENERGIZED" 32 "PCS_NOT_ENABLED" 31 "CP_NOT_ENABLED" 30 "CP_NOT_READY" 29 "SYSTEM_NOT_ENABLED" 28 "PCS_DISALLOWS" 27 "CP_DISALLOWS" 26 "SYSTEM_NOT_ALLOWED" 25 "SYSTEM_NOT_POSSIBLE" 24 "PCS_GRACEFUL_SHUTDOWN_REQUESTED" 23 "CP_GRACEFUL_SHUTDOWN_REQUESTED" 22 "NOT_NEEDED_OR_WANTED" 21 "EVSE_NOT_READY" 20 "EVSE_NOT_PRESENT" 19 "STATE_TIMEOUT_EXPIRED" 18 "FC_LINK_NOT_READY" 17 "FC_CONTACTORS_NOT_CLOSED" 16 "FC_CONTACTORS_NOT_OPEN" 15 "EVSE_NOT_COMPATIBLE" 14 "FC_LINK_NOT_ALLOWED_TO_ENERGIZE" 13 "ABORT_SUPERDISCHARGE_ALERT_SET" 12 "ABORT_CHARGE_ALERT_SET" 11 "PCS_ESCALATED_SHUTDOWN_REQUESTED" 10 "CP_ESCALATED_SHUTDOWN_REQUESTED" 7 "POWERSHARE_PROTECTION_TRIPPED" 6 "SYSTEM_DIRECTOR_FAULT_REQUESTED" 5 "CP_FAULT_LINE_ASSERTED" 4 "PCS_EMERGENCY_SHUTDOWN_REQUESTED" 3 "CP_EMERGENCY_SHUTDOWN_REQUESTED" 2 "PCS_MIA" 1 "CP_MIA" 0 "COND_NONE" ;
VAL_ 884 BMS_powerTransferWaitCondition 41 "PRECHARGE_NOT_COMPLETE" 40 "EVSE_OUTPUT_CURRENT_NOT_LOW" 39 "ALL_RETRIES_EXHAUSTED" 38 "TEMP_TOO_LOW" 37 "FEATURE_DISABLED" 36 "SOE_TOO_LOW" 35 "AC_RELAYS_NOT_OPEN" 34 "PCS_NOT_DISABLED" 33 "CP_INLET_STILL_ENERGIZED" 32 "PCS_NOT_ENABLED" 31 "CP_NOT_ENABLED" 30 "CP_NOT_READY" 29 "SYSTEM_NOT_ENABLED" 28 "PCS_DISALLOWS" 27 "CP_DISALLOWS" 26 "SYSTEM_NOT_ALLOWED" 25 "SYSTEM_NOT_POSSIBLE" 24 "PCS_GRACEFUL_SHUTDOWN_REQUESTED" 23 "CP_GRACEFUL_SHUTDOWN_REQUESTED" 22 "NOT_NEEDED_OR_WANTED" 21 "EVSE_NOT_READY" 20 "EVSE_NOT_PRESENT" 19 "STATE_TIMEOUT_EXPIRED" 18 "FC_LINK_NOT_READY" 17 "FC_CONTACTORS_NOT_CLOSED" 16 "FC_CONTACTORS_NOT_OPEN" 15 "EVSE_NOT_COMPATIBLE" 14 "FC_LINK_NOT_ALLOWED_TO_ENERGIZE" 13 "ABORT_SUPERDISCHARGE_ALERT_SET" 12 "ABORT_CHARGE_ALERT_SET" 11 "PCS_ESCALATED_SHUTDOWN_REQUESTED" 10 "CP_ESCALATED_SHUTDOWN_REQUESTED" 7 "POWERSHARE_PROTECTION_TRIPPED" 6 "SYSTEM_DIRECTOR_FAULT_REQUESTED" 5 "CP_FAULT_LINE_ASSERTED" 4 "PCS_EMERGENCY_SHUTDOWN_REQUESTED" 3 "CP_EMERGENCY_SHUTDOWN_REQUESTED" 2 "PCS_MIA" 1 "CP_MIA" 0 "COND_NONE" ;
VAL_ 946 BMS_pcsPrechargeRequest 2 "LV_DISCHARGE" 1 "FC_LINK_TEST" 0 "PRECHARGE_INACTIVE" ;
VAL_ 946 BMS_cacEstimationSource 2 "CAC_SOURCE_LIFE_MODEL" 1 "CAC_SOURCE_RESTING_POINT_CAC" 0 "CAC_SOURCE_UNKNOWN" ;
VAL_ 946 BMS_cellTempTargetMode 11 "V2X_SESSION" 10 "PASSIVE_COOL_ON_NAV" 9 "ACTIVE_COOL_ON_NAV" 8 "SOH_HEAT_PACK" 7 "DRAGSTRIP" 6 "PASSIVE_HEAT_ON_NAV" 5 "ACTIVE_HEAT_ON_NAV" 4 "DISCONNECTED_PRECONDITION" 3 "CONNECTED_PRECONDITION" 2 "HIGH_POWER_CHARGE" 1 "LOW_POWER_CHARGE" 0 "DEFAULT" ;
VAL_ 914 BMS_reservedConfig_0 36 "BMS_CONFIG_36" 35 "BMS_CONFIG_35" 34 "BMS_CONFIG_34" 33 "BMS_CONFIG_33" 32 "BMS_CONFIG_32" 31 "BMS_CONFIG_31" 30 "BMS_CONFIG_30" 29 "BMS_CONFIG_29" 28 "BMS_CONFIG_28" 27 "BMS_CONFIG_27" 26 "BMS_CONFIG_26" 25 "BMS_CONFIG_25" 24 "BMS_CONFIG_24" 23 "BMS_CONFIG_23" 22 "BMS_CONFIG_22" 21 "BMS_CONFIG_21" 20 "BMS_CONFIG_20" 19 "BMS_CONFIG_19" 18 "BMS_CONFIG_18" 17 "BMS_CONFIG_17" 16 "BMS_CONFIG_16" 15 "BMS_CONFIG_15" 14 "BMS_CONFIG_14" 13 "BMS_CONFIG_13" 12 "BMS_CONFIG_12" 11 "BMS_CONFIG_11" 10 "BMS_CONFIG_10" 9 "BMS_CONFIG_9" 8 "BMS_CONFIG_8" 7 "BMS_CONFIG_7" 6 "BMS_CONFIG_6" 5 "BMS_CONFIG_5" 4 "BMS_CONFIG_4" 3 "BMS_CONFIG_3" 2 "BMS_CONFIG_2" 1 "BMS_CONFIG_1" 0 "BMS_CONFIG_0" ;
VAL_ 914 BMS_moduleType 5 "BMS_MOD_TYPE_5" 4 "BMS_MOD_TYPE_4" 3 "BMS_MOD_TYPE_3" 2 "BMS_MOD_TYPE_2" 1 "BMS_MOD_TYPE_1" 0 "BMS_MOD_TYPE_UNKNOWN" ;
VAL_ 914 BMS_thermalPackType 9 "E3D_40P" 8 "E3D" 7 "BLADERUNNER_E1" 6 "BFF00S" 5 "P2" 4 "BFF00_E1" 3 "CATL_E1" 2 "E3" 1 "E1" 0 "UNKNOWN" ;
VAL_ 914 BMS_standbySupplyContinuousPower 3 "17W" 2 "16W" 1 "4W" 0 "0W" ;
VAL_ 1810 BMS_packTemperatureStatus1 3 "SENSOR_BYPASSED" 2 "SENSOR_NOMINAL" 1 "SENSOR_BAD" 0 "SENSOR_MISSING" ;
VAL_ 1810 BMS_packTemperatureStatus2 3 "SENSOR_BYPASSED" 2 "SENSOR_NOMINAL" 1 "SENSOR_BAD" 0 "SENSOR_MISSING" ;
VAL_ 1810 BMS_packTemperatureStatus3 3 "SENSOR_BYPASSED" 2 "SENSOR_NOMINAL" 1 "SENSOR_BAD" 0 "SENSOR_MISSING" ;
VAL_ 1810 BMS_packTemperatureStatus4 3 "SENSOR_BYPASSED" 2 "SENSOR_NOMINAL" 1 "SENSOR_BAD" 0 "SENSOR_MISSING" ;
VAL_ 1810 BMS_packTemperatureStatus5 3 "SENSOR_BYPASSED" 2 "SENSOR_NOMINAL" 1 "SENSOR_BAD" 0 "SENSOR_MISSING" ;
VAL_ 1810 BMS_packTemperatureStatus6 3 "SENSOR_BYPASSED" 2 "SENSOR_NOMINAL" 1 "SENSOR_BAD" 0 "SENSOR_MISSING" ;
VAL_ 1810 BMS_packTemperatureStatus7 3 "SENSOR_BYPASSED" 2 "SENSOR_NOMINAL" 1 "SENSOR_BAD" 0 "SENSOR_MISSING" ;
VAL_ 1810 BMS_packTemperatureStatus8 3 "SENSOR_BYPASSED" 2 "SENSOR_NOMINAL" 1 "SENSOR_BAD" 0 "SENSOR_MISSING" ;
VAL_ 1810 BMS_packTemperatureStatus9 3 "SENSOR_BYPASSED" 2 "SENSOR_NOMINAL" 1 "SENSOR_BAD" 0 "SENSOR_MISSING" ;
VAL_ 1810 BMS_packTemperatureStatus10 3 "SENSOR_BYPASSED" 2 "SENSOR_NOMINAL" 1 "SENSOR_BAD" 0 "SENSOR_MISSING" ;
VAL_ 1810 BMS_packTemperatureStatus11 3 "SENSOR_BYPASSED" 2 "SENSOR_NOMINAL" 1 "SENSOR_BAD" 0 "SENSOR_MISSING" ;
VAL_ 1810 BMS_packTemperatureStatus12 3 "SENSOR_BYPASSED" 2 "SENSOR_NOMINAL" 1 "SENSOR_BAD" 0 "SENSOR_MISSING" ;
VAL_ 1810 BMS_packTemperatureStatus13 3 "SENSOR_BYPASSED" 2 "SENSOR_NOMINAL" 1 "SENSOR_BAD" 0 "SENSOR_MISSING" ;
VAL_ 1810 BMS_packTemperatureStatus14 3 "SENSOR_BYPASSED" 2 "SENSOR_NOMINAL" 1 "SENSOR_BAD" 0 "SENSOR_MISSING" ;
VAL_ 1810 BMS_packTemperatureStatus15 3 "SENSOR_BYPASSED" 2 "SENSOR_NOMINAL" 1 "SENSOR_BAD" 0 "SENSOR_MISSING" ;
VAL_ 1810 BMS_packTemperatureStatus16 3 "SENSOR_BYPASSED" 2 "SENSOR_NOMINAL" 1 "SENSOR_BAD" 0 "SENSOR_MISSING" ;
VAL_ 1810 BMS_packTemperatureStatus17 3 "SENSOR_BYPASSED" 2 "SENSOR_NOMINAL" 1 "SENSOR_BAD" 0 "SENSOR_MISSING" ;
VAL_ 1810 BMS_packTemperatureStatus18 3 "SENSOR_BYPASSED" 2 "SENSOR_NOMINAL" 1 "SENSOR_BAD" 0 "SENSOR_MISSING" ;
VAL_ 594 BMS_powerLimitsState 1 "POWER_CALCULATED_FOR_DRIVE" 0 "POWER_NOT_CALCULATED_FOR_DRIVE" ;
VAL_ 674 BMS_acRippleRequest 4 "RIPPLE_FAULTED" 3 "RIPPLE_ON" 2 "RIPPLE_STANDBY" 1 "RIPPLE_OFF" 0 "RIPPLE_NOT_SUPPORTED" ;
VAL_ 1170 BMS_userFacingSohTestState 5 "CHARGE_REST" 4 "CHARGE" 3 "DISCHARGE_REST" 2 "DISCHARGE" 1 "HEAT_PACK" 0 "NOT_RUNNING" ;
VAL_ 1170 BMS_userFacingSohTestEndMode 5 "TEST_COMPLETE_WITH_SOC_IMBALANCE" 4 "TEST_COMPLETE" 3 "FAILED" 2 "REQUEST_DROPPED" 1 "RUNNING" 0 "NONE" ;
VAL_ 530 BMS_contactorState 6 "BMS_CTRSET_BLOCKED" 5 "BMS_CTRSET_WELDED" 4 "BMS_CTRSET_CLOSED" 3 "BMS_CTRSET_CLOSING" 2 "BMS_CTRSET_OPENING" 1 "BMS_CTRSET_OPEN" 0 "BMS_CTRSET_SNA" ;
VAL_ 530 BMS_userChargeStatus 6 "BMS_CALIBRATING" 5 "BMS_CHARGE_STOPPED" 4 "BMS_CHARGE_COMPLETE" 3 "BMS_CHARGING" 2 "BMS_ABOUT_TO_CHARGE" 1 "BMS_NO_POWER" 0 "BMS_DISCONNECTED" ;
VAL_ 530 BMS_state 10 "BMS_DIAG" 9 "BMS_SNA" 8 "BMS_TEST" 7 "BMS_WELD" 6 "BMS_FAULT" 5 "BMS_CLEAR_FAULT" 4 "BMS_FEIM" 3 "BMS_CHARGE" 2 "BMS_SUPPORT" 1 "BMS_DRIVE" 0 "BMS_STANDBY" ;
VAL_ 530 BMS_diLimpRequest 1 "LIMP_REQUEST_WELDED" 0 "LIMP_REQUEST_NONE" ;
VAL_ 530 BMS_acManagerState 11 "FAULTED" 10 "OPEN_AC_RELAYS" 9 "DISABLE_PCS" 8 "GRID_FORM_ACTIVE" 7 "GRID_FOLLOW_ACTIVE" 6 "TETHERING_ACTIVE" 5 "CHARGING_ACTIVE" 4 "ENABLE_PCS" 3 "ENABLE_FC_LINK_FOR_AC" 2 "REQUEST_POWER_TRANSFER" 1 "STANDBY" 0 "INACTIVE" ;
VAL_ 530 BMS_smStateRequest 10 "BMS_DIAG" 9 "BMS_SNA" 8 "BMS_TEST" 7 "BMS_WELD" 6 "BMS_FAULT" 5 "BMS_CLEAR_FAULT" 4 "BMS_FEIM" 3 "BMS_CHARGE" 2 "BMS_SUPPORT" 1 "BMS_DRIVE" 0 "BMS_STANDBY" ;
VAL_ 530 BMS_hvState 6 "HV_UP" 5 "HV_UP_FOR_DC_CHARGE" 4 "HV_UP_FOR_CHARGE" 3 "HV_UP_FOR_DRIVE" 2 "HV_GOING_DOWN" 1 "HV_COMING_UP" 0 "HV_DOWN" ;
VAL_ 1071 BMS_acDischargeBlockedReason 41 "PRECHARGE_NOT_COMPLETE" 40 "EVSE_OUTPUT_CURRENT_NOT_LOW" 39 "ALL_RETRIES_EXHAUSTED" 38 "TEMP_TOO_LOW" 37 "FEATURE_DISABLED" 36 "SOE_TOO_LOW" 35 "AC_RELAYS_NOT_OPEN" 34 "PCS_NOT_DISABLED" 33 "CP_INLET_STILL_ENERGIZED" 32 "PCS_NOT_ENABLED" 31 "CP_NOT_ENABLED" 30 "CP_NOT_READY" 29 "SYSTEM_NOT_ENABLED" 28 "PCS_DISALLOWS" 27 "CP_DISALLOWS" 26 "SYSTEM_NOT_ALLOWED" 25 "SYSTEM_NOT_POSSIBLE" 24 "PCS_GRACEFUL_SHUTDOWN_REQUESTED" 23 "CP_GRACEFUL_SHUTDOWN_REQUESTED" 22 "NOT_NEEDED_OR_WANTED" 21 "EVSE_NOT_READY" 20 "EVSE_NOT_PRESENT" 19 "STATE_TIMEOUT_EXPIRED" 18 "FC_LINK_NOT_READY" 17 "FC_CONTACTORS_NOT_CLOSED" 16 "FC_CONTACTORS_NOT_OPEN" 15 "EVSE_NOT_COMPATIBLE" 14 "FC_LINK_NOT_ALLOWED_TO_ENERGIZE" 13 "ABORT_SUPERDISCHARGE_ALERT_SET" 12 "ABORT_CHARGE_ALERT_SET" 11 "PCS_ESCALATED_SHUTDOWN_REQUESTED" 10 "CP_ESCALATED_SHUTDOWN_REQUESTED" 7 "POWERSHARE_PROTECTION_TRIPPED" 6 "SYSTEM_DIRECTOR_FAULT_REQUESTED" 5 "CP_FAULT_LINE_ASSERTED" 4 "PCS_EMERGENCY_SHUTDOWN_REQUESTED" 3 "CP_EMERGENCY_SHUTDOWN_REQUESTED" 2 "PCS_MIA" 1 "CP_MIA" 0 "COND_NONE" ;
VAL_ 754 BMS_nmKeepAwakeReason 8 "BMS_KEEPAWAKE_REASON_OTA" 7 "BMS_KEEPAWAKE_REASON_PRECONDITIONING" 6 "BMS_KEEPAWAKE_REASON_CP_ACTIVE" 5 "BMS_KEEPAWAKE_REASON_BMS_ACTIVE" 4 "BMS_KEEPAWAKE_REASON_HVP_ACTIVE" 3 "BMS_KEEPAWAKE_REASON_FC_CTR_CLEANING" 2 "BMS_KEEPAWAKE_REASON_CRITICAL_ALERT" 1 "BMS_KEEPAWAKE_REASON_CTRS_CLOSED" 0 "BMS_KEEPAWAKE_REASON_NONE_SNA" ;
VAL_ 754 BMS_nmWakeUpReason 4 "BMS_WAKEUP_REASON_CRITICALALERT" 3 "BMS_WAKEUP_REASON_WANTTOCHARGE" 2 "BMS_WAKEUP_REASON_CAN_HVS" 1 "BMS_WAKEUP_REASON_CAN_VEH" 0 "BMS_WAKEUP_REASON_NONE" ;
VAL_ 796 CC_pilotState 3 "CC_PILOT_STATE_SNA" 2 "CC_PILOT_STATE_FAULTED" 1 "CC_PILOT_STATE_IDLE" 0 "CC_PILOT_STATE_READY" ;
VAL_ 796 CC_gridGrounding 2 "CC_GRID_GROUNDING_SNA" 1 "CC_GRID_GROUNDING_IT_SplitPhase" 0 "CC_GRID_GROUNDING_TN_TT" ;
VAL_ 797 CC_buttonState 1 "CC_BUTTON_PRESSED" 0 "CC_BUTTON_RELEASED" ;
VAL_ 797 EVSE_v2xSupport 2 "V2X_OVER_SWCAN" 1 "V2X_OVER_PLC" 0 "V2X_NOT_SUPPORTED" ;
VAL_ 812 CC_contactor1Closed 3 "CC_CONTACTOR_SNA" 1 "CC_CONTACTOR_CLOSED" 0 "CC_CONTACTOR_OPEN" ;
VAL_ 812 CC_contactor2Closed 3 "CC_CONTACTOR_SNA" 1 "CC_CONTACTOR_CLOSED" 0 "CC_CONTACTOR_OPEN" ;
VAL_ 870 CMPD_infoBuildType 4 "INFO_MFG_BUILD" 3 "INFO_TRACEABLE_CI_BUILD" 2 "INFO_LOCAL_BUILD" 1 "INFO_PLATFORM_BUILD" 0 "INFO_UNKNOWN_BUILD" ;
VAL_ 680 CMPD_state 15 "CMPD_STATE_SNA" 4 "CMPD_STATE_IDLE" 3 "CMPD_STATE_FAULT" 2 "CMPD_STATE_STANDBY" 1 "CMPD_STATE_RUNNING" 0 "CMPD_STATE_INIT" ;
VAL_ 680 CMPD_wasteHeatState 3 "CMPD_WASTE_HEAT_STATE_UNUSED" 2 "CMPD_WASTE_HEAT_STATE_NOT_AVAILABLE" 1 "CMPD_WASTE_HEAT_STATE_ACTIVE" 0 "CMPD_WASTE_HEAT_STATE_OFF" ;
VAL_ 867 CMP_infoBuildType 4 "INFO_MFG_BUILD" 3 "INFO_TRACEABLE_CI_BUILD" 2 "INFO_LOCAL_BUILD" 1 "INFO_PLATFORM_BUILD" 0 "INFO_UNKNOWN_BUILD" ;
